VERSION ""

NS_ :

BS_:

BU_: SOBDM_BCCM GWM GENERIC BECM TSTR

BO_ 2026 TesterPhysicalResSOBDM: 8 SOBDM_BCCM
 SG_ TesterPhysicalResSOBDM : 7|64@0+ (1,0) [0|1.84467E+019] "unitless"  TSTR

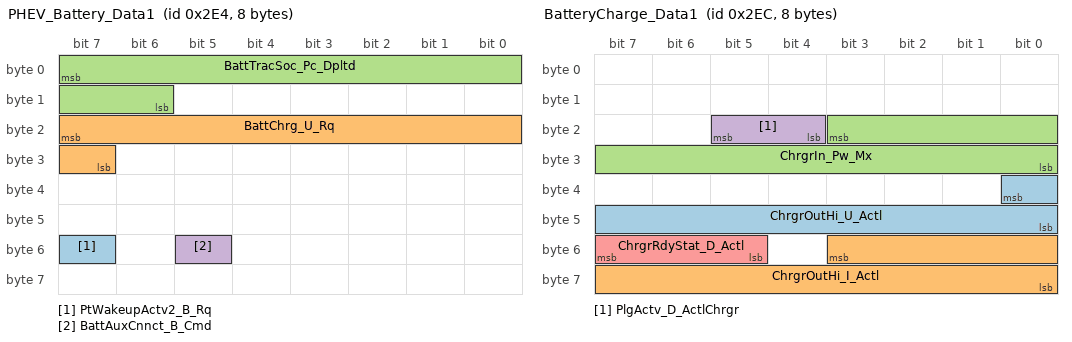
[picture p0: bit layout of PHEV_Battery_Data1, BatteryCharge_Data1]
BO_ 740 PHEV_Battery_Data1: 8 BECM
 SG_ PtWakeupActv2_B_Rq : 55|1@0+ (1,0) [0|1] "SED"  GWM
 SG_ BattChrg_U_Rq : 23|9@0+ (1,0) [0|511] "volt"  GWM,SOBDM_BCCM
 SG_ BattTracSoc_Pc_Dpltd : 7|10@0+ (0.1,0) [0|102.3] "percent"  GWM
 SG_ BattAuxCnnct_B_Cmd : 53|1@0+ (1,0) [0|1] "SED"  GWM,SOBDM_BCCM

BO_ 748 BatteryCharge_Data1: 8 SOBDM_BCCM
 SG_ ChrgrOutHi_U_Actl : 32|9@0+ (1,0) [0|510] "volt"  BECM,GWM
 SG_ ChrgrOutHi_I_Actl : 51|12@0+ (0.1,0) [0|409.4] "ampere"  BECM,GWM
 SG_ ChrgrIn_Pw_Mx : 19|12@0+ (50,0) [0|204700] "watts"  BECM,GWM
 SG_ PlgActv_D_ActlChrgr : 21|2@0+ (1,0) [0|3] "SED"  BECM,GWM
 SG_ ChrgrRdyStat_D_Actl : 55|3@0+ (1,0) [0|7] "SED"  BECM,GWM

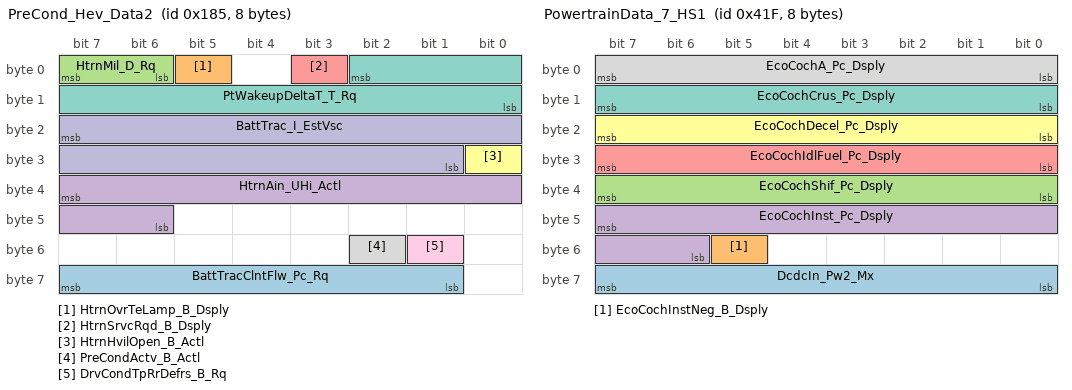
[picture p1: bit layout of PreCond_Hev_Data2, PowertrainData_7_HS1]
BO_ 389 PreCond_Hev_Data2: 8 GWM
 SG_ BattTracClntFlw_Pc_Rq : 63|7@0+ (1,0) [0|127] "percent"  BECM
 SG_ HtrnOvrTeLamp_B_Dsply : 5|1@0+ (1,0) [0|1] "SED" Vector__XXX
 SG_ HtrnMil_D_Rq : 7|2@0+ (1,0) [0|3] "SED" Vector__XXX
 SG_ HtrnAin_UHi_Actl : 39|10@0+ (0.5,0) [0|510.5] "volt"  BECM
 SG_ HtrnSrvcRqd_B_Dsply : 3|1@0+ (1,0) [0|1] "SED" Vector__XXX
 SG_ HtrnHvilOpen_B_Actl : 24|1@0+ (1,0) [0|1] "SED"  BECM
 SG_ PtWakeupDeltaT_T_Rq : 2|11@0+ (1,0) [0|2045] "minute" Vector__XXX
 SG_ PreCondActv_B_Actl : 50|1@0+ (1,0) [0|1] "SED" Vector__XXX
 SG_ DrvCondTpRrDefrs_B_Rq : 49|1@0+ (1,0) [0|1] "SED" Vector__XXX
 SG_ BattTrac_I_EstVsc : 23|15@0+ (0.05,-750) [-750|888.25] "Amps"  BECM

BO_ 1055 PowertrainData_7_HS1: 8 GWM
 SG_ DcdcIn_Pw2_Mx : 63|8@0+ (20,500) [500|5600] "watts"  BECM
 SG_ EcoCochInstNeg_B_Dsply : 53|1@0+ (1,0) [0|1] "SED" Vector__XXX
 SG_ EcoCochShif_Pc_Dsply : 39|8@0+ (0.392157,0) [0|100.000035] "percent" Vector__XXX
 SG_ EcoCochInst_Pc_Dsply : 47|10@0+ (0.1,0) [0|102.3] "percent" Vector__XXX
 SG_ EcoCochIdlFuel_Pc_Dsply : 31|8@0+ (0.392157,0) [0|100.000035] "percent" Vector__XXX
 SG_ EcoCochDecel_Pc_Dsply : 23|8@0+ (0.392157,0) [0|100.000035] "percent" Vector__XXX
 SG_ EcoCochCrus_Pc_Dsply : 15|8@0+ (0.392157,0) [0|100.000035] "percent" Vector__XXX
 SG_ EcoCochA_Pc_Dsply : 7|8@0+ (0.392157,0) [0|100.000035] "percent" Vector__XXX

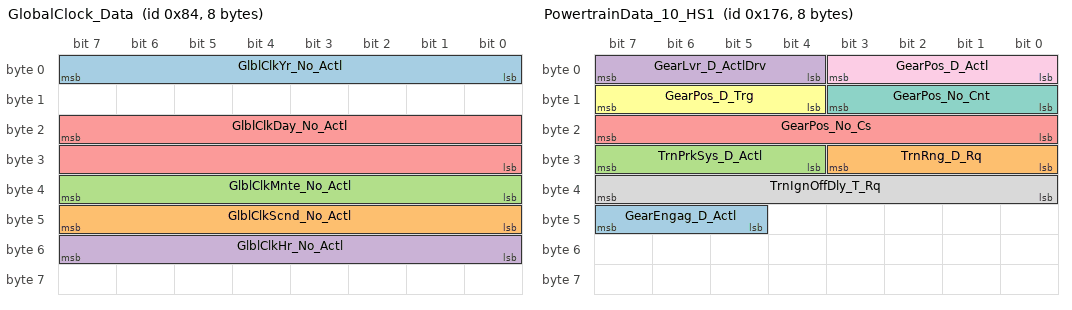
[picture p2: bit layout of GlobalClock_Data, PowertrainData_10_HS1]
BO_ 132 GlobalClock_Data: 8 GWM
 SG_ GlblClkYr_No_Actl : 7|8@0+ (1,2000) [2000|2255] "year"  BECM
 SG_ GlblClkScnd_No_Actl : 47|8@0+ (1,0) [0|255] "second" Vector__XXX
 SG_ GlblClkMnte_No_Actl : 39|8@0+ (1,0) [0|255] "minute" Vector__XXX
 SG_ GlblClkHr_No_Actl : 55|8@0+ (1,0) [0|255] "hour" Vector__XXX
 SG_ GlblClkDay_No_Actl : 23|16@0+ (1,0) [0|65535] "julian day"  BECM

BO_ 374 PowertrainData_10_HS1: 8 GWM
 SG_ GearEngag_D_Actl : 47|3@0+ (1,0) [0|7] "SED" Vector__XXX
 SG_ TrnRng_D_Rq : 27|4@0+ (1,0) [0|15] "SED"  BECM,SOBDM_BCCM
 SG_ TrnPrkSys_D_Actl : 31|4@0+ (1,0) [0|15] "SED" Vector__XXX
 SG_ GearLvr_D_ActlDrv : 7|4@0+ (1,0) [0|15] "SED" Vector__XXX
 SG_ GearPos_No_Cs : 23|8@0+ (1,0) [0|255] "unitless" Vector__XXX
 SG_ GearPos_D_Trg : 15|4@0+ (1,0) [0|15] "SED" Vector__XXX
 SG_ GearPos_No_Cnt : 11|4@0+ (1,0) [0|15] "unitless" Vector__XXX
 SG_ TrnIgnOffDly_T_Rq : 39|8@0+ (4,0) [0|1020] "ms" Vector__XXX
 SG_ GearPos_D_Actl : 3|4@0+ (1,0) [0|15] "SED" Vector__XXX

BO_ 817 Locking_Systems_2: 8 GWM
 SG_ ChildLckMde_B_Stat : 56|1@0+ (1,0) [0|1] "SED" Vector__XXX
 SG_ VehLckInd_D_Rq : 58|2@0+ (1,0) [0|3] "SED" Vector__XXX
 SG_ DrTgateOpen_B_Rq : 59|1@0+ (1,0) [0|1] "SED" Vector__XXX
 SG_ DrTgateExtSwMde_B_Stat : 32|1@0+ (1,0) [0|1] "SED" Vector__XXX
 SG_ Remote_Device_Feedback : 50|3@0+ (1,0) [0|7] "SED" Vector__XXX
 SG_ Veh_Lock_Requestor : 55|5@0+ (1,0) [0|31] "SED" Vector__XXX
 SG_ R_Pwr_Sliding_Dr_Rqst : 36|1@0+ (1,0) [0|1] "SED" Vector__XXX
 SG_ Power_Liftgate_Rqst : 0|1@0+ (1,0) [0|1] "SED" Vector__XXX
 SG_ Veh_Lock_EvNum : 47|8@0+ (1,0) [0|255] "unitless" Vector__XXX
 SG_ Power_Decklid_Rqst : 1|1@0+ (1,0) [0|1] "SED" Vector__XXX
 SG_ L_Pwr_Sliding_Dr_Rqst : 3|1@0+ (1,0) [0|1] "SED" Vector__XXX
 SG_ Keyfob_Pad_Msg_Count : 15|8@0+ (1,0) [0|255] "Counts" Vector__XXX
 SG_ Veh_Lock_Sub_Id : 63|4@0+ (1,0) [0|15] "SED" Vector__XXX
 SG_ Veh_Lock_Status : 34|2@0+ (1,0) [0|3] "SED"  SOBDM_BCCM
 SG_ ChildLck_D_Dsply : 7|2@0+ (1,0) [0|3] "SED" Vector__XXX
 SG_ WindowLockout_B_Stat : 35|1@0+ (1,0) [0|1] "SED" Vector__XXX
 SG_ RollCodeUnlock : 23|16@0+ (1,0) [0|65535] "Unitless" Vector__XXX
 SG_ Lockmsgtxt_D_Rq : 39|3@0+ (1,0) [0|7] "SED" Vector__XXX
 SG_ FobComm_D_Stat : 5|2@0+ (1,0) [0|3] "SED" Vector__XXX
 SG_ LockInhibit : 2|1@0+ (1,0) [0|1] "SED" Vector__XXX

BO_ 2018 TesterPhysicalReqSOBDM: 8 TSTR
 SG_ TesterPhysicalReqSOBDM : 7|64@0+ (1,0) [0|1.84467E+019] "unitless"  SOBDM_BCCM

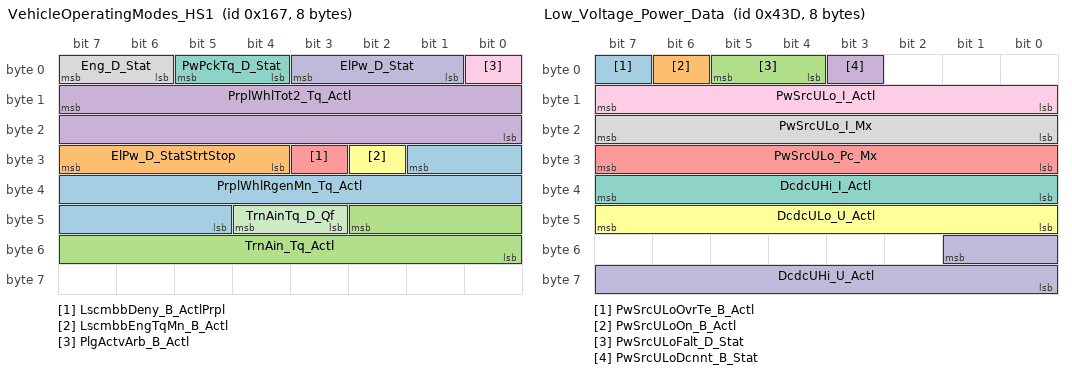
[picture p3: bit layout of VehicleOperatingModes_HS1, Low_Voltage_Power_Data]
BO_ 359 VehicleOperatingModes_HS1: 8 GWM
 SG_ PrplWhlRgenMn_Tq_Actl : 25|13@0+ (4,-16380) [-16380|16380] "Nm" Vector__XXX
 SG_ ElPw_D_StatStrtStop : 31|4@0+ (1,0) [0|15] "SED" Vector__XXX
 SG_ TrnAin_Tq_Actl : 42|11@0+ (1,-500) [-500|1547] "Nm" Vector__XXX
 SG_ PrplWhlTot2_Tq_Actl : 15|16@0+ (4,-131072) [-131072|131060] "Nm" Vector__XXX
 SG_ LscmbbDeny_B_ActlPrpl : 27|1@0+ (1,0) [0|1] "SED" Vector__XXX
 SG_ LscmbbEngTqMn_B_Actl : 26|1@0+ (1,0) [0|1] "SED" Vector__XXX
 SG_ PwPckTq_D_Stat : 5|2@0+ (1,0) [0|3] "SED"  SOBDM_BCCM,BECM
 SG_ Eng_D_Stat : 7|2@0+ (1,0) [0|3] "SED" Vector__XXX
 SG_ PlgActvArb_B_Actl : 0|1@0+ (1,0) [0|1] "SED" Vector__XXX
 SG_ ElPw_D_Stat : 3|3@0+ (1,0) [0|7] "SED" Vector__XXX
 SG_ TrnAinTq_D_Qf : 44|2@0+ (1,0) [0|3] "SED" Vector__XXX

BO_ 1085 Low_Voltage_Power_Data: 8 GWM
 SG_ PwSrcULoOvrTe_B_Actl : 7|1@0+ (1,0) [0|1] "SED" Vector__XXX
 SG_ PwSrcULoOn_B_Actl : 6|1@0+ (1,0) [0|1] "SED"  SOBDM_BCCM
 SG_ PwSrcULoFalt_D_Stat : 5|2@0+ (1,0) [0|3] "SED" Vector__XXX
 SG_ PwSrcULoDcnnt_B_Stat : 3|1@0+ (1,0) [0|1] "SED" Vector__XXX
 SG_ PwSrcULo_Pc_Mx : 31|8@0+ (0.4,0) [0|101.6] "%" Vector__XXX
 SG_ DcdcULo_U_Actl : 47|8@0+ (0.1,0) [0|25.4] "Volts" Vector__XXX
 SG_ DcdcUHi_I_Actl : 39|8@0+ (0.1,0) [0|25.4] "Amps"  BECM
 SG_ PwSrcULo_I_Mx : 23|8@0+ (1,0) [0|254] "ampere" Vector__XXX
 SG_ PwSrcULo_I_Actl : 15|8@0+ (1,0) [0|254] "ampere" Vector__XXX
 SG_ DcdcUHi_U_Actl : 49|10@0+ (0.5,0) [0|510.5] "V"  BECM

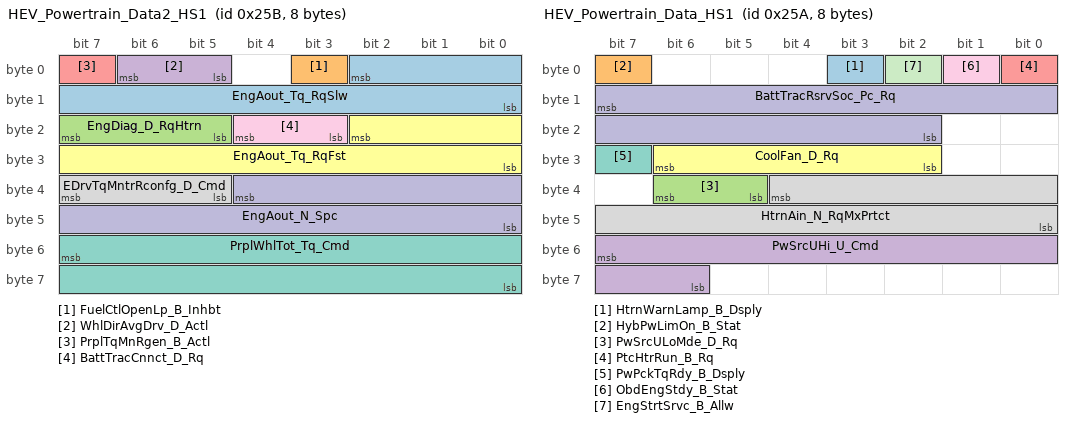
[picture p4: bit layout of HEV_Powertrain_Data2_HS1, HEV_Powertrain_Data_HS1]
BO_ 603 HEV_Powertrain_Data2_HS1: 8 GWM
 SG_ EngAout_Tq_RqSlw : 2|11@0+ (1,-500) [-500|1547] "Nm" Vector__XXX
 SG_ FuelCtlOpenLp_B_Inhbt : 3|1@0+ (1,0) [0|1] "SED" Vector__XXX
 SG_ EngDiag_D_RqHtrn : 23|3@0+ (1,0) [0|7] "SED" Vector__XXX
 SG_ WhlDirAvgDrv_D_Actl : 6|2@0+ (1,0) [0|3] "SED" Vector__XXX
 SG_ PrplTqMnRgen_B_Actl : 7|1@0+ (1,0) [0|1] "SED" Vector__XXX
 SG_ EngAout_Tq_RqFst : 18|11@0+ (1,-500) [-500|1547] "Nm" Vector__XXX
 SG_ PrplWhlTot_Tq_Cmd : 55|16@0+ (4,-131072) [-131072|131068] "Nm" Vector__XXX
 SG_ EDrvTqMntrRconfg_D_Cmd : 39|3@0+ (1,0) [0|7] "SED" Vector__XXX
 SG_ BattTracCnnct_D_Rq : 20|2@0+ (1,0) [0|3] "SED"  SOBDM_BCCM,BECM
 SG_ EngAout_N_Spc : 36|13@0+ (2,0) [0|16382] "rpm" Vector__XXX

BO_ 602 HEV_Powertrain_Data_HS1: 8 GWM
 SG_ HtrnWarnLamp_B_Dsply : 3|1@0+ (1,0) [0|1] "SED" Vector__XXX
 SG_ HybPwLimOn_B_Stat : 7|1@0+ (1,0) [0|1] "SED"  BECM
 SG_ PwSrcULoMde_D_Rq : 38|2@0+ (1,0) [0|3] "SED"  BECM
 SG_ PwSrcUHi_U_Cmd : 55|10@0+ (0.5,0) [0|511.5] "volt"  BECM
 SG_ PtcHtrRun_B_Rq : 0|1@0+ (1,0) [0|1] "SED" Vector__XXX
 SG_ CoolFan_D_Rq : 30|5@0+ (1,0) [0|31] "unitless" Vector__XXX
 SG_ PwPckTqRdy_B_Dsply : 31|1@0+ (1,0) [0|1] "SED" Vector__XXX
 SG_ HtrnAin_N_RqMxPrtct : 36|13@0+ (2,0) [0|16382] "RPM" Vector__XXX
 SG_ ObdEngStdy_B_Stat : 1|1@0+ (1,0) [0|1] "SED" Vector__XXX
 SG_ BattTracRsrvSoc_Pc_Rq : 15|14@0+ (0.01,0) [0|163.81] "percent"  BECM
 SG_ EngStrtSrvc_B_Allw : 2|1@0+ (1,0) [0|1] "SED" Vector__XXX

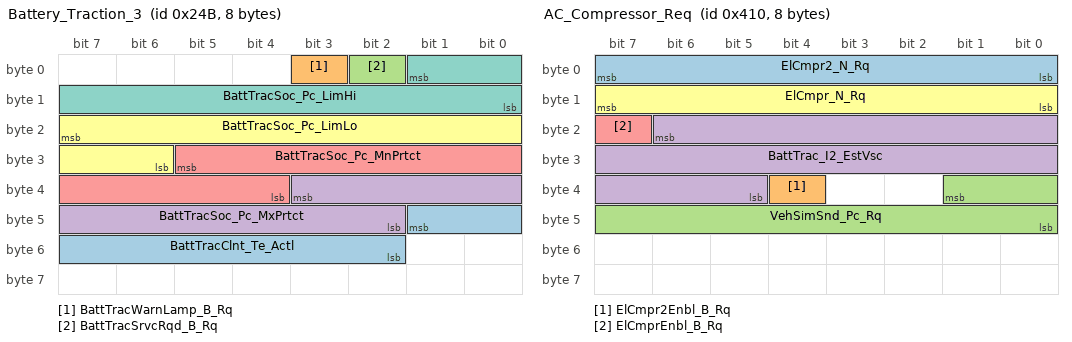
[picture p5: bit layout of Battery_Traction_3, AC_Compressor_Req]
BO_ 587 Battery_Traction_3: 8 BECM
 SG_ BattTracClnt_Te_Actl : 41|8@0+ (0.5,-60) [-60|66.5] "degC"  GWM
 SG_ BattTracWarnLamp_B_Rq : 3|1@0+ (1,0) [0|1] "SED"  GWM
 SG_ BattTracSrvcRqd_B_Rq : 2|1@0+ (1,0) [0|1] "SED"  GWM
 SG_ BattTracSoc_Pc_MxPrtct : 35|10@0+ (0.1,0) [0|100] "%"  GWM
 SG_ BattTracSoc_Pc_MnPrtct : 29|10@0+ (0.1,0) [0|100] "%"  GWM
 SG_ BattTracSoc_Pc_LimLo : 23|10@0+ (0.1,0) [0|100] "%"  GWM
 SG_ BattTracSoc_Pc_LimHi : 1|10@0+ (0.1,0) [0|100] "%"  GWM

BO_ 1040 AC_Compressor_Req: 8 GWM
 SG_ ElCmpr2_N_Rq : 7|8@0+ (50,0) [0|12750] "RPM" Vector__XXX
 SG_ ElCmpr2Enbl_B_Rq : 36|1@0+ (1,0) [0|1] "SED" Vector__XXX
 SG_ VehSimSnd_Pc_Rq : 33|10@0+ (0.2,-102.2) [-102.2|102.4] "percent" Vector__XXX
 SG_ BattTrac_I2_EstVsc : 22|18@0+ (0.05,-6553.52) [-6553.52|6553.53] "ampere"  BECM
 SG_ ElCmprEnbl_B_Rq : 23|1@0+ (1,0) [0|1] "SED" Vector__XXX
 SG_ ElCmpr_N_Rq : 15|8@0+ (50,0) [0|12750] "RPM" Vector__XXX

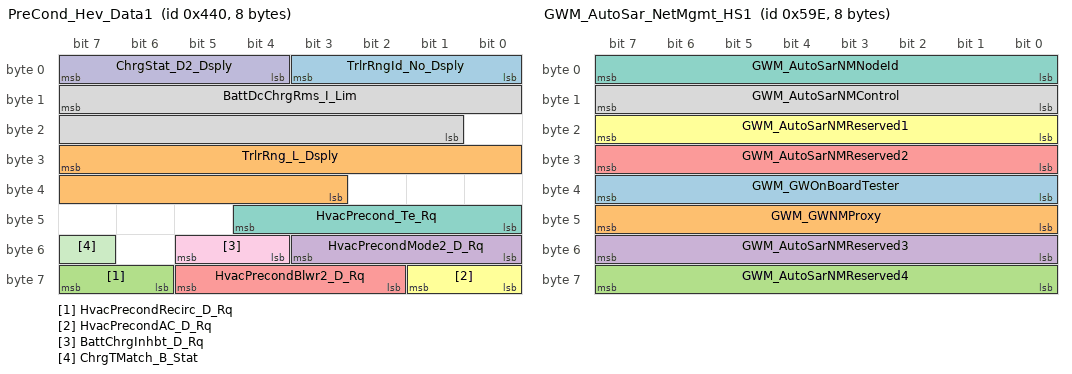
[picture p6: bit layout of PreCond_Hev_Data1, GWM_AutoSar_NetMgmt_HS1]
BO_ 1088 PreCond_Hev_Data1: 8 GWM
 SG_ TrlrRngId_No_Dsply : 3|4@0+ (1,0) [0|15] "unitless" Vector__XXX
 SG_ TrlrRng_L_Dsply : 31|13@0+ (0.1,0) [0|818.9] "kilometer" Vector__XXX
 SG_ HvacPrecondRecirc_D_Rq : 63|2@0+ (1,0) [0|3] "SED" Vector__XXX
 SG_ HvacPrecondMode2_D_Rq : 51|4@0+ (1,0) [0|15] "SED" Vector__XXX
 SG_ HvacPrecondBlwr2_D_Rq : 61|4@0+ (1,0) [0|15] "SED" Vector__XXX
 SG_ HvacPrecondAC_D_Rq : 57|2@0+ (1,0) [0|3] "SED" Vector__XXX
 SG_ HvacPrecond_Te_Rq : 44|5@0+ (0.5,14.5) [14.5|30] "deg C" Vector__XXX
 SG_ BattDcChrgRms_I_Lim : 15|15@0+ (0.05,0) [0|1638.25] "ampere"  BECM
 SG_ BattChrgInhbt_D_Rq : 53|2@0+ (1,0) [0|3] "SED"  BECM,SOBDM_BCCM
 SG_ ChrgStat_D2_Dsply : 7|4@0+ (1,0) [0|15] "SED" Vector__XXX
 SG_ ChrgTMatch_B_Stat : 55|1@0+ (1,0) [0|1] "SED" Vector__XXX

BO_ 1072 Cluster_Info1_HS1: 8 GWM
 SG_ ePRNDL_MODE_UB : 63|1@0+ (1,0) [0|1] "SED" Vector__XXX
 SG_ NtrlTowMdeEnbl_B_RqDrv : 6|1@0+ (1,0) [0|1] "SED" Vector__XXX
 SG_ NtrlTowMdeEnbl_B_RqDrv_UB : 48|1@0+ (1,0) [0|1] "SED" Vector__XXX
 SG_ Remote_Start_QuietMode_UB : 50|1@0+ (1,0) [0|1] "SED" Vector__XXX
 SG_ Remote_Start_QuietMode : 51|1@0+ (1,0) [0|1] "SED" Vector__XXX
 SG_ ParkDetect_Stat_UB : 52|1@0+ (1,0) [0|1] "SED" Vector__XXX
 SG_ ParkDetect_Stat : 53|1@0+ (1,0) [0|1] "SED" Vector__XXX
 SG_ TrlrLampCnnct_B_Actl_UB : 42|1@0+ (1,0) [0|1] "SED" Vector__XXX
 SG_ StopLamp_B_RqTrlrBrk_UB : 46|1@0+ (1,0) [0|1] "SED" Vector__XXX
 SG_ StopLamp_B_RqTrlrBrk : 47|1@0+ (1,0) [0|1] "SED" Vector__XXX
 SG_ OdometerMasterValue_UB : 1|1@0+ (1,0) [0|1] "SED"  SOBDM_BCCM,BECM
 SG_ OdometerMasterValue : 15|24@0+ (1,0) [0|16777214] "km"  SOBDM_BCCM,BECM
 SG_ FrostWarn_D_Stat : 5|2@0+ (1,0) [0|3] "SED" Vector__XXX
 SG_ ReducedGuard_D_Rq_UB : 49|1@0+ (1,0) [0|1] "SED" Vector__XXX
 SG_ ReducedGuard_D_Rq : 41|2@0+ (1,0) [0|3] "SED" Vector__XXX
 SG_ ePRNDL_MODE : 0|1@0+ (1,0) [0|1] "SED" Vector__XXX
 SG_ EngOilLife_B_RqReset : 43|1@0+ (1,0) [0|1] "SED" Vector__XXX
 SG_ Outside_Air_Temp_Stat_UB : 2|1@0+ (1,0) [0|1] "SED" Vector__XXX
 SG_ Outside_Air_Temp_Stat : 39|8@0+ (0.5,-40) [-40|86.5] "Degrees C" Vector__XXX
 SG_ KeyTypeChngMykey_D_Rq_UB : 60|1@0+ (1,0) [0|1] "SED" Vector__XXX
 SG_ KeyTypeChngMykey_D_Rq : 62|2@0+ (1,0) [0|3] "SED" Vector__XXX
 SG_ TrlrLampCnnct_B_Actl : 3|1@0+ (1,0) [0|1] "SED" Vector__XXX

BO_ 1438 GWM_AutoSar_NetMgmt_HS1: 8 GWM
 SG_ GWM_GWOnBoardTester : 39|8@0+ (1,0) [0|255] "unitless"  SOBDM_BCCM,BECM
 SG_ GWM_GWNMProxy : 47|8@0+ (1,0) [0|255] "unitless"  SOBDM_BCCM,BECM
 SG_ GWM_AutoSarNMReserved4 : 63|8@0+ (1,0) [0|255] "unitless"  SOBDM_BCCM,BECM
 SG_ GWM_AutoSarNMReserved3 : 55|8@0+ (1,0) [0|255] "unitless"  SOBDM_BCCM,BECM
 SG_ GWM_AutoSarNMReserved2 : 31|8@0+ (1,0) [0|255] "unitless"  SOBDM_BCCM,BECM
 SG_ GWM_AutoSarNMReserved1 : 23|8@0+ (1,0) [0|255] "unitless"  SOBDM_BCCM,BECM
 SG_ GWM_AutoSarNMNodeId : 7|8@0+ (1,0) [0|255] "unitless"  SOBDM_BCCM,BECM
 SG_ GWM_AutoSarNMControl : 15|8@0+ (1,0) [0|255] "unitless"  SOBDM_BCCM,BECM

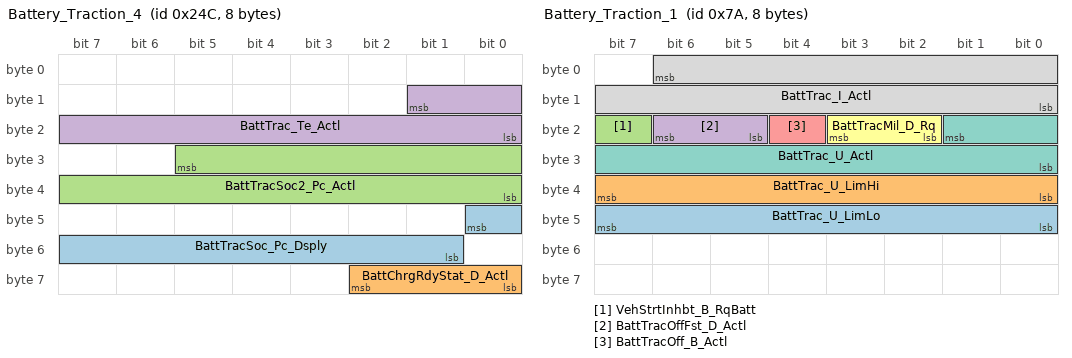
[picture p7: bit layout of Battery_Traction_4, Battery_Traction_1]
BO_ 588 Battery_Traction_4: 8 BECM
 SG_ BattTracSoc_Pc_Dsply : 40|8@0+ (0.5,0) [0|126.5] "Percent"  GWM,SOBDM_BCCM
 SG_ BattChrgRdyStat_D_Actl : 58|3@0+ (1,0) [0|7] "SED"  GWM,SOBDM_BCCM
 SG_ BattTracSoc2_Pc_Actl : 29|14@0+ (0.01,0) [0|163.81] "%"  GWM
 SG_ BattTrac_Te_Actl : 9|10@0+ (0.5,-50) [-50|460.5] "degC"  GWM

BO_ 122 Battery_Traction_1: 8 BECM
 SG_ BattTrac_U_LimLo : 47|8@0+ (2,0) [0|510] "volt"  GWM
 SG_ BattTrac_U_LimHi : 39|8@0+ (2,0) [0|510] "volt"  GWM
 SG_ VehStrtInhbt_B_RqBatt : 23|1@0+ (1,0) [0|1] "SED"  GWM
 SG_ BattTracOffFst_D_Actl : 22|2@0+ (1,0) [0|3] "SED"  SOBDM_BCCM,GWM
 SG_ BattTracOff_B_Actl : 20|1@0+ (1,0) [0|1] "SED"  GWM,SOBDM_BCCM
 SG_ BattTracMil_D_Rq : 19|2@0+ (1,0) [0|3] "SED"  GWM
 SG_ BattTrac_U_Actl : 17|10@0+ (0.5,0) [0|510.5] "Volts"  GWM,SOBDM_BCCM
 SG_ BattTrac_I_Actl : 6|15@0+ (0.05,-750) [-750|888.25] "Amps"  SOBDM_BCCM,GWM

BO_ 1814 TesterPhysicalReqGWM_H1: 8 TSTR
 SG_ TesterPhysicalReqGWM_H1 : 7|64@0+ (1,0) [0|1.84467E+019] "unitless"  GWM

BO_ 1822 TesterPhysicalResGWM_HS1: 8 GWM
 SG_ TesterPhysicalResGWM_H1 : 7|64@0+ (1,0) [0|1.84467E+019] "unitless"  TSTR

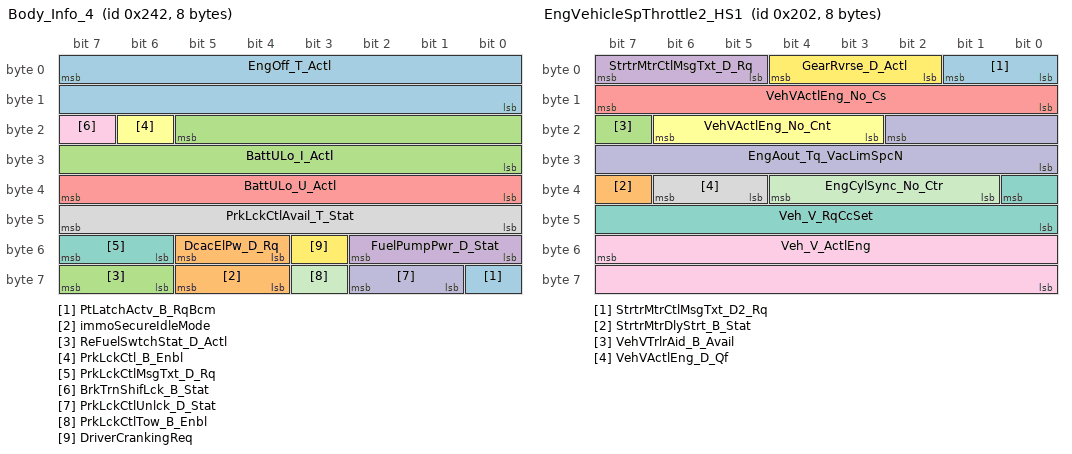
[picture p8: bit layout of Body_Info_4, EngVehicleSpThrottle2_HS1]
BO_ 578 Body_Info_4: 8 GWM
 SG_ PtLatchActv_B_RqBcm : 56|1@0+ (1,0) [0|1] "SED" Vector__XXX
 SG_ immoSecureIdleMode : 61|2@0+ (1,0) [0|3] "SED" Vector__XXX
 SG_ ReFuelSwtchStat_D_Actl : 63|2@0+ (1,0) [0|3] "SED" Vector__XXX
 SG_ FuelPumpPwr_D_Stat : 50|3@0+ (1,0) [0|7] "SED" Vector__XXX
 SG_ BattULo_U_Actl : 39|8@0+ (0.0625,0) [0|15.875] "volt"  SOBDM_BCCM,BECM
 SG_ PrkLckCtl_B_Enbl : 22|1@0+ (1,0) [0|1] "SED" Vector__XXX
 SG_ PrkLckCtlMsgTxt_D_Rq : 55|2@0+ (1,0) [0|3] "SED" Vector__XXX
 SG_ PrkLckCtlAvail_T_Stat : 47|8@0+ (1,0) [0|255] "second" Vector__XXX
 SG_ BrkTrnShifLck_B_Stat : 23|1@0+ (1,0) [0|1] "SED" Vector__XXX
 SG_ PrkLckCtlUnlck_D_Stat : 58|2@0+ (1,0) [0|3] "SED" Vector__XXX
 SG_ PrkLckCtlTow_B_Enbl : 59|1@0+ (1,0) [0|1] "SED" Vector__XXX
 SG_ DriverCrankingReq : 51|1@0+ (1,0) [0|1] "SED" Vector__XXX
 SG_ EngOff_T_Actl : 7|16@0+ (1,0) [0|65534] "second^0.5" Vector__XXX
 SG_ DcacElPw_D_Rq : 53|2@0+ (1,0) [0|3] "SED" Vector__XXX
 SG_ BattULo_I_Actl : 21|14@0+ (0.0625,-512) [-512|511.875] "ampere" Vector__XXX

BO_ 514 EngVehicleSpThrottle2_HS1: 8 GWM
 SG_ StrtrMtrCtlMsgTxt_D2_Rq : 1|2@0+ (1,0) [0|3] "SED" Vector__XXX
 SG_ StrtrMtrDlyStrt_B_Stat : 39|1@0+ (1,0) [0|1] "SED" Vector__XXX
 SG_ VehVTrlrAid_B_Avail : 23|1@0+ (1,0) [0|1] "SED" Vector__XXX
 SG_ StrtrMtrCtlMsgTxt_D_Rq : 7|3@0+ (1,0) [0|7] "SED" Vector__XXX
 SG_ VehVActlEng_No_Cs : 15|8@0+ (1,0) [0|255] "Unitless" Vector__XXX
 SG_ VehVActlEng_No_Cnt : 22|4@0+ (1,0) [0|15] "Unitless" Vector__XXX
 SG_ Veh_V_RqCcSet : 32|9@0+ (0.5,0) [0|255.5] "kph" Vector__XXX
 SG_ VehVActlEng_D_Qf : 38|2@0+ (1,0) [0|3] "SED"  BECM
 SG_ Veh_V_ActlEng : 55|16@0+ (0.01,0) [0|655.35] "kph"  BECM
 SG_ EngAout_Tq_VacLimSpcN : 18|11@0+ (1,-500) [-500|1547] "Nm" Vector__XXX
 SG_ EngCylSync_No_Ctr : 36|4@0+ (1,0) [0|15] "unitless" Vector__XXX
 SG_ GearRvrse_D_Actl : 4|3@0+ (1,0) [0|7] "SED" Vector__XXX

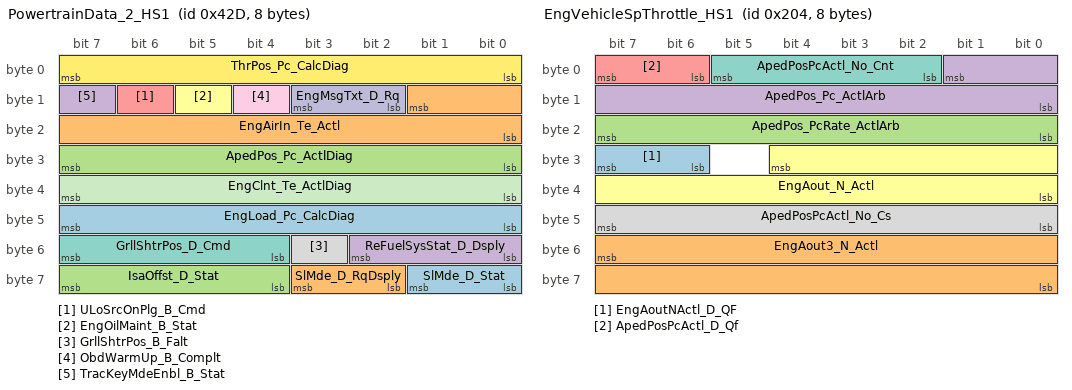
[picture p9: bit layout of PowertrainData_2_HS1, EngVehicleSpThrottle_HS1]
BO_ 1069 PowertrainData_2_HS1: 8 GWM
 SG_ SlMde_D_Stat : 57|2@0+ (1,0) [0|3] "SED" Vector__XXX
 SG_ SlMde_D_RqDsply : 59|2@0+ (1,0) [0|3] "SED" Vector__XXX
 SG_ IsaOffst_D_Stat : 63|4@0+ (1,0) [0|15] "SED" Vector__XXX
 SG_ ReFuelSysStat_D_Dsply : 50|3@0+ (1,0) [0|7] "SED" Vector__XXX
 SG_ ULoSrcOnPlg_B_Cmd : 14|1@0+ (1,0) [0|1] "SED"  BECM
 SG_ EngOilMaint_B_Stat : 13|1@0+ (1,0) [0|1] "SED" Vector__XXX
 SG_ GrllShtrPos_D_Cmd : 55|4@0+ (1,0) [0|15] "SED" Vector__XXX
 SG_ GrllShtrPos_B_Falt : 51|1@0+ (1,0) [0|1] "SED" Vector__XXX
 SG_ ObdWarmUp_B_Complt : 12|1@0+ (1,0) [0|1] "SED"  SOBDM_BCCM,BECM
 SG_ EngMsgTxt_D_Rq : 11|2@0+ (1,0) [0|3] "SED" Vector__XXX
 SG_ EngClnt_Te_ActlDiag : 39|8@0+ (1,-40) [-40|215] "degC"  BECM
 SG_ ThrPos_Pc_CalcDiag : 7|8@0+ (0.392157,0) [0|100.000035] "%" Vector__XXX
 SG_ EngLoad_Pc_CalcDiag : 47|8@0+ (0.392157,0) [0|100.000035] "%"  BECM
 SG_ EngAirIn_Te_Actl : 9|10@0+ (0.25,-128) [-128|127.25] "degC" Vector__XXX
 SG_ ApedPos_Pc_ActlDiag : 31|8@0+ (0.392157,0) [0|100.000035] "%"  BECM
 SG_ TracKeyMdeEnbl_B_Stat : 15|1@0+ (1,0) [0|1] "SED" Vector__XXX

BO_ 2015 TesterFunctionalReq_H1: 8 TSTR
 SG_ TesterFunctionalReq : 7|64@0+ (1,0) [0|1.84467E+019] "unitless"  SOBDM_BCCM,GWM,BECM

BO_ 516 EngVehicleSpThrottle_HS1: 8 GWM
 SG_ EngAoutNActl_D_QF : 31|2@0+ (1,0) [0|3] "SED" Vector__XXX
 SG_ EngAout3_N_Actl : 55|16@0+ (0.25,0) [0|16383.5] "RPM" Vector__XXX
 SG_ ApedPos_PcRate_ActlArb : 23|8@0+ (0.04,-5) [-5|5.12] "%/ms" Vector__XXX
 SG_ ApedPos_Pc_ActlArb : 1|10@0+ (0.1,0) [0|102.3] "%" Vector__XXX
 SG_ ApedPosPcActl_D_Qf : 7|2@0+ (1,0) [0|3] "SED" Vector__XXX
 SG_ EngAout_N_Actl : 28|13@0+ (2,0) [0|16382] "rpm"  BECM
 SG_ ApedPosPcActl_No_Cnt : 5|4@0+ (1,0) [0|15] "Unitless" Vector__XXX
 SG_ ApedPosPcActl_No_Cs : 47|8@0+ (1,0) [0|255] "Unitless" Vector__XXX

BO_ 76 RCMStatusMessage2_HS1: 8 GWM
 SG_ RstrnPsngrOn_D_Stat : 39|4@0+ (1,0) [0|15] "SED" Vector__XXX
 SG_ FirstRowBuckle_No_Cs : 47|8@0+ (1,0) [0|255] "unitless" Vector__XXX
 SG_ RCMStatusMsg2_No_Cnt : 35|4@0+ (1,0) [0|15] "Unitless" Vector__XXX
 SG_ PsngrFmidDetct_D_Actl : 26|2@0+ (1,0) [0|3] "SED" Vector__XXX
 SG_ FirstRowBuckleMid : 28|2@0+ (1,0) [0|3] "SED" Vector__XXX
 SG_ ThirdRowBucklePsngr : 17|2@0+ (1,0) [0|3] "SED" Vector__XXX
 SG_ ThirdRowBuckleMid : 19|2@0+ (1,0) [0|3] "SED" Vector__XXX
 SG_ ThirdRowBuckleDriver : 21|2@0+ (1,0) [0|3] "SED" Vector__XXX
 SG_ SecondRowBucklePsngr : 23|2@0+ (1,0) [0|3] "SED" Vector__XXX
 SG_ SecondRowBuckleMid : 9|2@0+ (1,0) [0|3] "SED" Vector__XXX
 SG_ SecondRowBuckleDriver : 11|2@0+ (1,0) [0|3] "SED" Vector__XXX
 SG_ FirstRowBuckleDriver : 15|2@0+ (1,0) [0|3] "SED" Vector__XXX
 SG_ RILReq : 7|2@0+ (1,0) [0|3] "SED" Vector__XXX
 SG_ FirstRowBucklePsngr : 13|2@0+ (1,0) [0|3] "SED" Vector__XXX
 SG_ RstrnImpactEvntStatus : 3|3@0+ (1,0) [0|7] "SED"  SOBDM_BCCM,BECM
 SG_ PsngrFrntDetct_D_Actl : 5|2@0+ (1,0) [0|3] "SED" Vector__XXX
 SG_ EDRTriggerEvntSync : 29|1@0+ (1,0) [0|1] "SED" Vector__XXX
 SG_ PassRstrnInd_Req : 31|2@0+ (1,0) [0|3] "SED" Vector__XXX

BO_ 2028 TesterPhysicalResBECM: 8 BECM
 SG_ TesterPhysicalResBECM : 7|64@0+ (1,0) [0|1.84467E+019] "unitless"  TSTR

BO_ 2020 TesterPhysicalReqBECM: 8 TSTR
 SG_ TesterPhysicalReqBECM : 7|64@0+ (1,0) [0|1.84467E+019] "unitless"  BECM

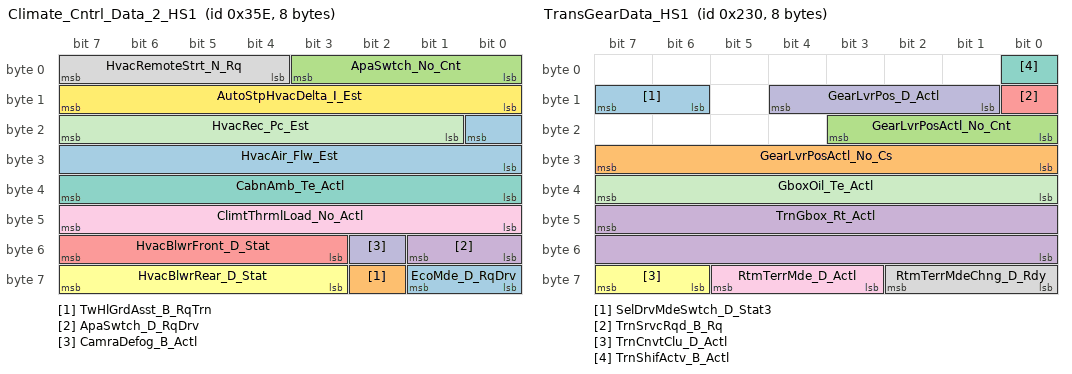
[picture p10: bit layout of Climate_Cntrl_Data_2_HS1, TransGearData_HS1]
BO_ 862 Climate_Cntrl_Data_2_HS1: 8 GWM
 SG_ EcoMde_D_RqDrv : 57|2@0+ (1,0) [0|3] "SED" Vector__XXX
 SG_ TwHlGrdAsst_B_RqTrn : 58|1@0+ (1,0) [0|1] "SED" Vector__XXX
 SG_ ApaSwtch_No_Cnt : 3|4@0+ (1,0) [0|15] "Unitless" Vector__XXX
 SG_ ApaSwtch_D_RqDrv : 49|2@0+ (1,0) [0|3] "SED" Vector__XXX
 SG_ HvacBlwrFront_D_Stat : 55|5@0+ (1,0) [0|31] "SED" Vector__XXX
 SG_ HvacBlwrRear_D_Stat : 63|5@0+ (1,0) [0|31] "SED" Vector__XXX
 SG_ CabnAmb_Te_Actl : 39|8@0+ (0.5,-57) [-57|70] "degreesC"  SOBDM_BCCM
 SG_ HvacRemoteStrt_N_Rq : 7|4@0+ (100,450) [450|1950] "RPM" Vector__XXX
 SG_ ClimtThrmlLoad_No_Actl : 47|8@0+ (1,0) [0|254] "unitless" Vector__XXX
 SG_ CamraDefog_B_Actl : 50|1@0+ (1,0) [0|1] "SED" Vector__XXX
 SG_ HvacRec_Pc_Est : 23|7@0+ (1,0) [0|127] "Percent" Vector__XXX
 SG_ AutoStpHvacDelta_I_Est : 15|8@0+ (1,-192) [-192|62] "ampere" Vector__XXX
 SG_ HvacAir_Flw_Est : 16|9@0+ (0.5,0) [0|255.5] "liter/second"  BECM

BO_ 560 TransGearData_HS1: 8 GWM
 SG_ SelDrvMdeSwtch_D_Stat3 : 15|2@0+ (1,0) [0|3] "SED" Vector__XXX
 SG_ GearLvrPosActl_No_Cs : 31|8@0+ (1,0) [0|255] "Unitless" Vector__XXX
 SG_ GearLvrPosActl_No_Cnt : 19|4@0+ (1,0) [0|15] "Unitless" Vector__XXX
 SG_ TrnGbox_Rt_Actl : 47|16@0+ (0.001,0) [0|65.533] "Unitless" Vector__XXX
 SG_ TrnSrvcRqd_B_Rq : 8|1@0+ (1,0) [0|1] "SED" Vector__XXX
 SG_ TrnCnvtClu_D_Actl : 63|2@0+ (1,0) [0|3] "SED" Vector__XXX
 SG_ TrnShifActv_B_Actl : 0|1@0+ (1,0) [0|1] "SED" Vector__XXX
 SG_ RtmTerrMdeChng_D_Rdy : 58|3@0+ (1,0) [0|7] "SED" Vector__XXX
 SG_ RtmTerrMde_D_Actl : 61|3@0+ (1,0) [0|7] "SED" Vector__XXX
 SG_ GearLvrPos_D_Actl : 12|4@0+ (1,0) [0|15] "SED"  SOBDM_BCCM,BECM
 SG_ GboxOil_Te_Actl : 39|8@0+ (1,-60) [-60|193] "degC" Vector__XXX

BO_ 1034 GGCC_Config_Mgmt_ID_1: 8 GWM
 SG_ VehicleGGCCData : 7|64@0+ (1,0) [0|1.84467E+019] "mixed"  SOBDM_BCCM,BECM

BO_ 947 BodyInfo_3: 8 GWM
 SG_ ValetMode_D_Mem : 16|1@0+ (1,0) [0|1] "SED" Vector__XXX
 SG_ DimmingLvlEvnt_No_Actl : 18|2@0+ (1,0) [0|3] "unitless" Vector__XXX
 SG_ DrStatDrvErrCnt_B_Stat : 19|1@0+ (1,0) [0|1] "SED" Vector__XXX
 SG_ TurnLghtRight_D_Rq : 63|2@0+ (1,0) [0|3] "SED" Vector__XXX
 SG_ TurnLghtRightOn_B_Stat : 35|1@0+ (1,0) [0|1] "SED" Vector__XXX
 SG_ TurnLghtLeftOn_B_Stat : 54|1@0+ (1,0) [0|1] "SED" Vector__XXX
 SG_ FogLghtRearOn_B_Stat : 1|1@0+ (1,0) [0|1] "SED" Vector__XXX
 SG_ Backlit_LED_Status : 23|4@0+ (1,0) [0|15] "SED" Vector__XXX
 SG_ TurnLghtLeft_D_Rq : 9|2@0+ (1,0) [0|3] "SED" Vector__XXX
 SG_ FogLghtFrontOn_B_Stat : 56|1@0+ (1,0) [0|1] "SED" Vector__XXX
 SG_ IgnKeyType_D_Actl : 39|4@0+ (1,0) [0|15] "SED" Vector__XXX
 SG_ Parklamp_Status : 3|2@0+ (1,0) [0|3] "SED" Vector__XXX
 SG_ Litval : 47|8@0+ (1,0) [0|253] "SED" Vector__XXX
 SG_ Key_In_Ignition_Stat : 11|1@0+ (1,0) [0|1] "SED" Vector__XXX
 SG_ Ignition_Status : 7|4@0+ (1,0) [0|15] "SED"  SOBDM_BCCM,BECM
 SG_ Dimming_Lvl : 31|8@0+ (1,0) [0|253] "SED" Vector__XXX
 SG_ Day_Night_Status : 15|2@0+ (1,0) [0|3] "SED"  SOBDM_BCCM
 SG_ Remote_Start_Status : 13|2@0+ (1,0) [0|3] "SED" Vector__XXX
 SG_ DrStatTgate_B_Actl : 0|1@0+ (1,0) [0|1] "SED" Vector__XXX
 SG_ DrStatRr_B_Actl : 49|1@0+ (1,0) [0|1] "SED" Vector__XXX
 SG_ DrStatRl_B_Actl : 48|1@0+ (1,0) [0|1] "SED" Vector__XXX
 SG_ DrStatPsngr_B_Actl : 60|1@0+ (1,0) [0|1] "SED" Vector__XXX
 SG_ DrStatInnrTgate_B_Actl : 58|1@0+ (1,0) [0|1] "SED" Vector__XXX
 SG_ DrStatHood_B_Actl : 59|1@0+ (1,0) [0|1] "SED" Vector__XXX
 SG_ DrStatDrv_B_Actl : 61|1@0+ (1,0) [0|1] "SED" Vector__XXX
 SG_ PrkBrkActv_B_Actl : 55|1@0+ (1,0) [0|1] "SED" Vector__XXX
 SG_ LifeCycMde_D_Actl : 53|4@0+ (1,0) [0|15] "SED"  SOBDM_BCCM
 SG_ Delay_Accy : 57|1@0+ (1,0) [0|1] "SED" Vector__XXX
 SG_ CrashEvnt_D_Stat : 34|2@0+ (1,0) [0|3] "SED" Vector__XXX
 SG_ FuelPmpInhbt_B_Stat : 32|1@0+ (1,0) [0|1] "SED" Vector__XXX
 SG_ BodySrvcRqd_B_Rq : 10|1@0+ (1,0) [0|1] "SED" Vector__XXX

CM_ BO_ 374 "Programs w/o HS1 0x172 will need HS1 0x176 for GearPos_D_Actl.  Future MY Programs that choose c/o still require HS1 0x172. ";
CM_ SG_ 374 TrnRng_D_Rq "Powersplit HEVs with HF45, HPCM will Tx  this message.  For all other programs it will be Tx by PCM or TCM. ";
CM_ SG_ 374 TrnPrkSys_D_Actl "Powersplit HEVs with HF45, HPCM will Tx  this message.  For all other programs it will be Tx by PCM or TCM. ";
CM_ SG_ 374 GearLvr_D_ActlDrv "Powersplit HEVs with HF45, HPCM will Tx  this message.  For all other programs it will be Tx by PCM or TCM. ";
CM_ SG_ 374 GearPos_No_Cs "Powersplit HEVs with HF45, HPCM will Tx  this message.  For all other programs it will be Tx by PCM or TCM. ";
CM_ SG_ 374 GearPos_D_Trg "Powersplit HEVs with HF45, HPCM will Tx  this message.  For all other programs it will be Tx by PCM or TCM. ";
CM_ SG_ 374 GearPos_No_Cnt "Powersplit HEVs with HF45, HPCM will Tx  this message.  For all other programs it will be Tx by PCM or TCM. ";
CM_ SG_ 374 GearPos_D_Actl "Powersplit HEVs with HF45, HPCM will Tx  this message.  For all other programs it will be Tx by PCM or TCM. ";
CM_ SG_ 359 TrnAin_Tq_Actl "Signal not transmitted on HEV variances.";
CM_ SG_ 359 PlgActvArb_B_Actl "Only supported on PHEV programs.  PlgActvArb_B_Actl HPCM will Tx on Powersplit PHEV’s,  On MHT PHEVs the PCM_HEV will Tx and HPCM will Rx. 
";
CM_ SG_ 359 TrnAinTq_D_Qf "Signal not transmitted on HEV variances.";
CM_ BO_ 1085 "HS1 0x43D Tx by HS1 BECM, DCDC_HEV, DCDC_LISB
Or FrameGateway from FD1
Set to FixedPeriodic 50ms at all nodes so the transmit method and rate export from mdc to dbc
Program specific msg lists update attributes as needed.";
CM_ SG_ 1085 DcdcULo_U_Actl "Signal not transmitted on gas and diesel variants.";
CM_ SG_ 1085 DcdcUHi_I_Actl "Signal not transmitted on gas and diesel variants.";
CM_ SG_ 1085 DcdcUHi_U_Actl "Signal not transmitted on gas and diesel variants.";
CM_ BO_ 603 "48V mHEV: ECM_HEVDSL is Tx
MHT HEV: PCM_HEV is Tx
Powersplit HEV: SOBDMC_HPCM is Tx
";
CM_ SG_ 603 WhlDirAvgDrv_D_Actl "48V mHEV: ECM_HEVDSL is Tx,  MHT HEV: PCM_HEV is Tx,  Powersplit HEV: SOBDMC_HPCM is Tx";
CM_ SG_ 603 PrplTqMnRgen_B_Actl "48V mHEV: ECM_HEVDSL is Tx,  MHT HEV: PCM_HEV is Tx,  Powersplit HEV: SOBDMC_HPCM is Tx";
CM_ SG_ 603 BattTracCnnct_D_Rq "48V mHEV: ECM_HEVDSL is Tx,  MHT HEV: PCM_HEV is Tx,  Powersplit HEV: SOBDMC_HPCM is Tx";
CM_ SG_ 1088 HvacPrecondMode2_D_Rq "Signal not transmitted on vehicles that do not have the Fuel operated heater feature.";
CM_ SG_ 1088 HvacPrecondBlwr2_D_Rq "Signal not transmitted on vehicles that do not have the Fuel operated heater feature.";
CM_ SG_ 1072 StopLamp_B_RqTrlrBrk "Signal not transmitted on all variants.";
CM_ SG_ 1072 Outside_Air_Temp_Stat "Filtered value, i.e. same as disply for customer";
CM_ SG_ 514 EngAout_Tq_VacLimSpcN "Signal not transmitted on gas and diesel variances.";
CM_ SG_ 514 EngCylSync_No_Ctr "Signal not transmitted on gas and diesel variances.";
CM_ SG_ 514 GearRvrse_D_Actl "Do not implement GearRvrse_D_Actl  until eTracker 8804151 is approved, 11/24/09";
CM_ SG_ 1069 SlMde_D_Stat "IPC and HUD_ADV Receve from HS3 FGW 0x42D, not HS3 0x38A, MSG DCR 506.";
CM_ SG_ 1069 SlMde_D_RqDsply "IPC and HUD_ADV Receve from HS3 FGW 0x42D, not HS3 0x38A, MSG DCR 506.";
CM_ SG_ 1069 ObdWarmUp_B_Complt "Signal not transmitted on gas and diesel variants.";
CM_ SG_ 1069 EngMsgTxt_D_Rq "Signal not transmitted on diesel variants.";
CM_ SG_ 1069 EngClnt_Te_ActlDiag "Signal not transmitted on gas variants.";
CM_ SG_ 1069 EngLoad_Pc_CalcDiag "Signal not transmitted on gas variants.";
CM_ SG_ 1069 ApedPos_Pc_ActlDiag "Signal not transmitted on gas variants.";
CM_ BO_ 2015 "OBDII Request ($7DF) messages are for FNOS 1.0.1 only.
Diagnostic Functional Addressing ($7DF) and Dual Rate Periodic messages are for FNOS I3 only.";
CM_ SG_ 516 EngAout3_N_Actl "Signal not transmitted on gas and diesel variants.";
CM_ SG_ 516 ApedPosPcActl_No_Cnt "Signal not transmitted on gas and diesel variants.";
CM_ SG_ 516 ApedPosPcActl_No_Cs "Signal not transmitted on gas and diesel variants.";
CM_ BO_ 560 "MHT (U611/625) the HPCM will Rx 0x230 from the PCM_HEV
Powersplit FWD HEV’s (Cx482/3 430) the HPCM will Tx 0x230";
CM_ SG_ 560 SelDrvMdeSwtch_D_Stat3 "ECM_HEV does not support or Transmit signal.";
CM_ SG_ 560 GearLvrPosActl_No_Cs "Signal not transmitted on Gas & HEV variants. MHT(U611/625) HPCM Rx 0x230 from PCM_HEV. Powersplit FWD HEV’s(Cx482/3 430) HPCM Tx 0x230.";
CM_ SG_ 560 GearLvrPosActl_No_Cnt "Signal not transmitted on Gas & HEV variants. MHT(U611/625) HPCM Rx 0x230 from PCM_HEV. Powersplit FWD HEV’s(Cx482/3 430) HPCM Tx 0x230.";
CM_ SG_ 560 TrnGbox_Rt_Actl "Signal not transmitted on Gas & HEV variants. MHT(U611/625) HPCM Rx 0x230 from PCM_HEV. Powersplit FWD HEV’s(Cx482/3 430) HPCM Tx 0x230.";
CM_ SG_ 560 TrnSrvcRqd_B_Rq "Signal not transmitted on Diesel & HEV variants. MHT(U611/625) HPCM Rx 0x230 from PCM_HEV. Powersplit FWD HEV’s(Cx482/3 430) HPCM Tx 0x230.";
CM_ SG_ 560 TrnCnvtClu_D_Actl "Signal not transmitted on Gas & HEV variants. MHT(U611/625) HPCM Rx 0x230 from PCM_HEV. Powersplit FWD HEV’s(Cx482/3 430) HPCM Tx 0x230.";
CM_ SG_ 560 TrnShifActv_B_Actl "Signal not transmitted on HEV variants. MHT(U611/625) HPCM Rx 0x230 from PCM_HEV. Powersplit FWD HEV’s(Cx482/3 430) HPCM Tx 0x230.";
CM_ SG_ 560 GboxOil_Te_Actl "Signal not transmitted on HEV variants. MHT(U611/625) HPCM Rx 0x230 from PCM_HEV. Powersplit FWD HEV’s(Cx482/3 430) HPCM Tx 0x230.";
CM_ SG_ 1034 VehicleGGCCData "RCMGenSigTimeout=6000";
CM_ SG_ 947 Dimming_Lvl "Refer to Vehicle Interior Illum Dimming Ctrl Sys Eng Spec, Table 2

";
CM_ SG_ 947 PrkBrkActv_B_Actl "Signal not transmitted on vehicles with electric park brake. ";
BA_DEF_ BO_  "FrameRouting" STRING ;
BA_DEF_ BO_  "FrameGatewayNetwork" STRING ;
BA_DEF_ BO_  "NetworkInitialization" ENUM  "No","Yes";
BA_DEF_ BO_  "FrameGatewayId" HEX 0 1407;
BA_DEF_ BO_  "EventRateOfChange" INT 10 10000;
BA_DEF_ BO_  "GenMsgNrOfRepetition" INT 0 100;
BA_DEF_ BO_  "GenMsgDelayTime" INT 0 1000;
BA_DEF_ BO_  "GenMsgCycleTime" INT 0 100000;
BA_DEF_ BO_  "GenMsgSendType" ENUM  "FixedPeriodic","Event","EnabledPeriodic","NotUsed","NotUsed","EventPeriodic","NotUsed","NotUsed","NoMsgSendType";
BA_DEF_ SG_  "U_CD764_MY2022_Tx" ENUM  "No","Yes";
BA_DEF_ SG_  "U_U55X_MY2022_Tx" ENUM  "No","Yes";
BA_DEF_ SG_  "U_CD542_MY2021_Tx" ENUM  "No","Yes";
BA_DEF_ SG_  "ECGUsedTxSignal" ENUM  "No","Yes";
BA_DEF_ SG_  "U_T6_MCA_MY2020_Tx" ENUM  "No","Yes";
BA_DEF_ SG_  "U_P702_MY2021_Tx" ENUM  "No","Yes";
BA_DEF_ SG_  "U_CX727_MY2021_Tx" ENUM  "No","Yes";
BA_DEF_ SG_  "U_CD764_MY2022_Rx" ENUM  "No","Yes";
BA_DEF_ SG_  "U_U55X_MY2022_Rx" ENUM  "No","Yes";
BA_DEF_ SG_  "U_CD542_MY2021_Rx" ENUM  "No","Yes";
BA_DEF_ SG_  "ECGUsedRxSignal" ENUM  "No","Yes";
BA_DEF_ SG_  "U_T6_MCA_MY2020_Rx" ENUM  "No","Yes";
BA_DEF_ SG_  "U_P702_MY2021_Rx" ENUM  "No","Yes";
BA_DEF_ SG_  "U_CX727_MY2021_Rx" ENUM  "No","Yes";
BA_DEF_ SG_  "GenSigStartValue" HEX 0 268435455;
BA_DEF_ SG_  "MetaData" ENUM  "No","Yes";
BA_DEF_ SG_  "ContentDependant" ENUM  "No","Yes";
BA_DEF_ SG_  "GenSigStartValueInteger" INT 0 1000000000;
BA_DEF_ SG_  "UsedOnPgmDBC" ENUM  "No","Yes";
BA_DEF_ SG_  "WakeupSignal" ENUM  "No","Yes";
BA_DEF_ SG_  "GenSigInactiveValue" INT 0 100000;
BA_DEF_ SG_  "GenSigSendType" ENUM  "Cyclic","OnWrite","vector_leerstring","OnChange","vector_leerstring","IfActive","vector_leerstring","NoSigSendType";
BA_DEF_ BO_  "SCP_FreshnessValueLength" INT 0 512;
BA_DEF_ BO_  "SCP_FreshnessValueTxLength" INT 0 512;
BA_DEF_ BO_  "SCP_AuthInfoTxLength" INT 0 512;
BA_DEF_ BO_  "NmAsrMessage" ENUM  "No","Yes";
BA_DEF_ BO_  "DiagState" ENUM  "No","Yes";
BA_DEF_ BO_  "DiagRequest" ENUM  "No","Yes";
BA_DEF_ BO_  "DiagResponse" ENUM  "No","Yes";
BA_DEF_ BO_  "GenMsgILSupport" ENUM  "No","Yes";
BA_DEF_DEF_  "FrameRouting" "";
BA_DEF_DEF_  "FrameGatewayNetwork" "NONE";
BA_DEF_DEF_  "NetworkInitialization" "Yes";
BA_DEF_DEF_  "FrameGatewayId" 0;
BA_DEF_DEF_  "EventRateOfChange" 10000;
BA_DEF_DEF_  "GenMsgNrOfRepetition" 1;
BA_DEF_DEF_  "GenMsgDelayTime" 20;
BA_DEF_DEF_  "GenMsgCycleTime" 0;
BA_DEF_DEF_  "GenMsgSendType" "NoMsgSendType";
BA_DEF_DEF_  "U_CD764_MY2022_Tx" "No";
BA_DEF_DEF_  "U_U55X_MY2022_Tx" "No";
BA_DEF_DEF_  "U_CD542_MY2021_Tx" "No";
BA_DEF_DEF_  "ECGUsedTxSignal" "No";
BA_DEF_DEF_  "U_T6_MCA_MY2020_Tx" "No";
BA_DEF_DEF_  "U_P702_MY2021_Tx" "No";
BA_DEF_DEF_  "U_CX727_MY2021_Tx" "No";
BA_DEF_DEF_  "U_CD764_MY2022_Rx" "No";
BA_DEF_DEF_  "U_U55X_MY2022_Rx" "No";
BA_DEF_DEF_  "U_CD542_MY2021_Rx" "No";
BA_DEF_DEF_  "ECGUsedRxSignal" "No";
BA_DEF_DEF_  "U_T6_MCA_MY2020_Rx" "No";
BA_DEF_DEF_  "U_P702_MY2021_Rx" "No";
BA_DEF_DEF_  "U_CX727_MY2021_Rx" "No";
BA_DEF_DEF_  "GenSigStartValue" 0;
BA_DEF_DEF_  "MetaData" "No";
BA_DEF_DEF_  "ContentDependant" "No";
BA_DEF_DEF_  "GenSigStartValueInteger" 0;
BA_DEF_DEF_  "UsedOnPgmDBC" "Yes";
BA_DEF_DEF_  "WakeupSignal" "No";
BA_DEF_DEF_  "GenSigInactiveValue" 0;
BA_DEF_DEF_  "GenSigSendType" "NoSigSendType";
BA_DEF_DEF_  "SCP_FreshnessValueLength" 64;
BA_DEF_DEF_  "SCP_FreshnessValueTxLength" 11;
BA_DEF_DEF_  "SCP_AuthInfoTxLength" 53;
BA_DEF_DEF_  "NmAsrMessage" "No";
BA_DEF_DEF_  "DiagState" "No";
BA_DEF_DEF_  "DiagRequest" "No";
BA_DEF_DEF_  "DiagResponse" "No";
BA_DEF_DEF_  "GenMsgILSupport" "Yes";
BA_ "GenMsgILSupport" BO_ 2026 0;
BA_ "DiagResponse" BO_ 2026 1;
BA_ "GenMsgSendType" BO_ 2026 1;
BA_ "GenMsgDelayTime" BO_ 2026 0;
BA_ "NetworkInitialization" BO_ 2026 0;
BA_ "GenMsgSendType" BO_ 740 0;
BA_ "GenMsgCycleTime" BO_ 740 100;
BA_ "GenMsgSendType" BO_ 748 0;
BA_ "GenMsgCycleTime" BO_ 748 100;
BA_ "FrameGatewayId" BO_ 389 389;
BA_ "FrameGatewayNetwork" BO_ 389 "FD1_CAN";
BA_ "FrameRouting" BO_ 389 "FD1_CAN,0x185;";
BA_ "FrameGatewayId" BO_ 1055 1055;
BA_ "FrameGatewayNetwork" BO_ 1055 "FD1_CAN";
BA_ "FrameRouting" BO_ 1055 "FD1_CAN,0x41F;";
BA_ "FrameRouting" BO_ 132 "HS1_CAN,0x84";
BA_ "FrameGatewayId" BO_ 132 132;
BA_ "FrameGatewayNetwork" BO_ 132 "HS1_CAN";
BA_ "FrameGatewayId" BO_ 374 374;
BA_ "FrameGatewayNetwork" BO_ 374 "FD1_CAN";
BA_ "FrameRouting" BO_ 374 "FD1_CAN,0x176;";
BA_ "FrameRouting" BO_ 817 "HS1_CAN,0x331";
BA_ "FrameGatewayId" BO_ 817 817;
BA_ "FrameGatewayNetwork" BO_ 817 "HS1_CAN";
BA_ "GenMsgILSupport" BO_ 2018 0;
BA_ "DiagRequest" BO_ 2018 1;
BA_ "GenMsgSendType" BO_ 2018 1;
BA_ "GenMsgDelayTime" BO_ 2018 0;
BA_ "NetworkInitialization" BO_ 2018 0;
BA_ "FrameGatewayId" BO_ 359 359;
BA_ "FrameGatewayNetwork" BO_ 359 "FD1_CAN";
BA_ "FrameRouting" BO_ 359 "FD1_CAN,0x167;";
BA_ "FrameRouting" BO_ 1085 "HS1_CAN,0x43D";
BA_ "FrameGatewayId" BO_ 1085 1085;
BA_ "FrameGatewayNetwork" BO_ 1085 "HS1_CAN";
BA_ "FrameGatewayId" BO_ 603 603;
BA_ "FrameGatewayNetwork" BO_ 603 "FD1_CAN";
BA_ "FrameRouting" BO_ 603 "FD1_CAN,0x25B;";
BA_ "FrameGatewayId" BO_ 602 602;
BA_ "FrameGatewayNetwork" BO_ 602 "FD1_CAN";
BA_ "FrameRouting" BO_ 602 "FD1_CAN,0x25A;";
BA_ "GenMsgSendType" BO_ 587 0;
BA_ "GenMsgCycleTime" BO_ 587 100;
BA_ "FrameGatewayId" BO_ 1040 1040;
BA_ "FrameGatewayNetwork" BO_ 1040 "FD1_CAN";
BA_ "FrameRouting" BO_ 1040 "FD1_CAN,0x410;";
BA_ "FrameGatewayId" BO_ 1088 1088;
BA_ "FrameGatewayNetwork" BO_ 1088 "FD1_CAN";
BA_ "FrameRouting" BO_ 1088 "FD1_CAN,0x440;";
BA_ "GenMsgSendType" BO_ 1072 5;
BA_ "GenMsgCycleTime" BO_ 1072 100;
BA_ "GenMsgILSupport" BO_ 1438 0;
BA_ "NmAsrMessage" BO_ 1438 1;
BA_ "GenMsgSendType" BO_ 1438 0;
BA_ "GenMsgCycleTime" BO_ 1438 1000;
BA_ "NetworkInitialization" BO_ 1438 0;
BA_ "GenMsgSendType" BO_ 588 0;
BA_ "GenMsgCycleTime" BO_ 588 100;
BA_ "GenMsgSendType" BO_ 122 0;
BA_ "GenMsgCycleTime" BO_ 122 10;
BA_ "GenMsgDelayTime" BO_ 122 0;
BA_ "GenMsgILSupport" BO_ 1814 0;
BA_ "DiagRequest" BO_ 1814 1;
BA_ "GenMsgSendType" BO_ 1814 1;
BA_ "GenMsgDelayTime" BO_ 1814 0;
BA_ "NetworkInitialization" BO_ 1814 0;
BA_ "GenMsgILSupport" BO_ 1822 0;
BA_ "DiagResponse" BO_ 1822 1;
BA_ "GenMsgSendType" BO_ 1822 1;
BA_ "GenMsgDelayTime" BO_ 1822 0;
BA_ "NetworkInitialization" BO_ 1822 0;
BA_ "FrameRouting" BO_ 578 "HS1_CAN,0x242";
BA_ "FrameGatewayId" BO_ 578 578;
BA_ "FrameGatewayNetwork" BO_ 578 "HS1_CAN";
BA_ "FrameGatewayId" BO_ 514 514;
BA_ "FrameGatewayNetwork" BO_ 514 "FD1_CAN";
BA_ "FrameRouting" BO_ 514 "FD1_CAN,0x202;";
BA_ "FrameGatewayId" BO_ 1069 1069;
BA_ "FrameGatewayNetwork" BO_ 1069 "FD1_CAN";
BA_ "FrameRouting" BO_ 1069 "FD1_CAN,0x42D;";
BA_ "GenMsgILSupport" BO_ 2015 0;
BA_ "DiagState" BO_ 2015 1;
BA_ "GenMsgSendType" BO_ 2015 1;
BA_ "GenMsgDelayTime" BO_ 2015 0;
BA_ "NetworkInitialization" BO_ 2015 0;
BA_ "FrameGatewayId" BO_ 516 516;
BA_ "FrameGatewayNetwork" BO_ 516 "FD1_CAN";
BA_ "FrameRouting" BO_ 516 "FD1_CAN,0x204;";
BA_ "GenMsgDelayTime" BO_ 76 10;
BA_ "FrameGatewayId" BO_ 76 76;
BA_ "FrameGatewayNetwork" BO_ 76 "HS2_CAN";
BA_ "FrameRouting" BO_ 76 "HS2_CAN,0x4C;";
BA_ "GenMsgILSupport" BO_ 2028 0;
BA_ "DiagResponse" BO_ 2028 1;
BA_ "GenMsgSendType" BO_ 2028 1;
BA_ "GenMsgDelayTime" BO_ 2028 0;
BA_ "NetworkInitialization" BO_ 2028 0;
BA_ "GenMsgILSupport" BO_ 2020 0;
BA_ "DiagRequest" BO_ 2020 1;
BA_ "GenMsgSendType" BO_ 2020 1;
BA_ "GenMsgDelayTime" BO_ 2020 0;
BA_ "NetworkInitialization" BO_ 2020 0;
BA_ "FrameGatewayId" BO_ 862 862;
BA_ "FrameGatewayNetwork" BO_ 862 "MS1_CAN";
BA_ "FrameRouting" BO_ 862 "MS1_CAN,0x35E;";
BA_ "FrameGatewayId" BO_ 560 560;
BA_ "FrameGatewayNetwork" BO_ 560 "FD1_CAN";
BA_ "FrameRouting" BO_ 560 "FD1_CAN,0x230;";
BA_ "FrameRouting" BO_ 1034 "HS1_CAN,0x40A";
BA_ "FrameGatewayId" BO_ 1034 1034;
BA_ "FrameGatewayNetwork" BO_ 1034 "HS1_CAN";
BA_ "FrameRouting" BO_ 947 "HS1_CAN,0x3B3";
BA_ "FrameGatewayId" BO_ 947 947;
BA_ "FrameGatewayNetwork" BO_ 947 "HS1_CAN";
BA_ "GenSigSendType" SG_ 2026 TesterPhysicalResSOBDM 3;
BA_ "U_CX727_MY2021_Tx" SG_ 2026 TesterPhysicalResSOBDM 1;
BA_ "U_CD542_MY2021_Tx" SG_ 2026 TesterPhysicalResSOBDM 1;
BA_ "WakeupSignal" SG_ 740 PtWakeupActv2_B_Rq 1;
BA_ "U_CX727_MY2021_Rx" SG_ 740 PtWakeupActv2_B_Rq 1;
BA_ "U_P702_MY2021_Rx" SG_ 740 PtWakeupActv2_B_Rq 1;
BA_ "U_T6_MCA_MY2020_Rx" SG_ 740 PtWakeupActv2_B_Rq 1;
BA_ "U_CD542_MY2021_Rx" SG_ 740 PtWakeupActv2_B_Rq 1;
BA_ "U_U55X_MY2022_Rx" SG_ 740 PtWakeupActv2_B_Rq 1;
BA_ "U_CD764_MY2022_Rx" SG_ 740 PtWakeupActv2_B_Rq 1;
BA_ "U_CX727_MY2021_Rx" SG_ 740 BattChrg_U_Rq 1;
BA_ "U_CD542_MY2021_Rx" SG_ 740 BattChrg_U_Rq 1;
BA_ "U_CX727_MY2021_Tx" SG_ 740 BattChrg_U_Rq 1;
BA_ "U_CD542_MY2021_Tx" SG_ 740 BattChrg_U_Rq 1;
BA_ "U_CX727_MY2021_Tx" SG_ 740 BattTracSoc_Pc_Dpltd 1;
BA_ "U_CD542_MY2021_Tx" SG_ 740 BattTracSoc_Pc_Dpltd 1;
BA_ "U_CX727_MY2021_Rx" SG_ 740 BattAuxCnnct_B_Cmd 1;
BA_ "U_CD542_MY2021_Rx" SG_ 740 BattAuxCnnct_B_Cmd 1;
BA_ "U_P702_MY2021_Rx" SG_ 740 BattAuxCnnct_B_Cmd 1;
BA_ "U_CX727_MY2021_Tx" SG_ 740 BattAuxCnnct_B_Cmd 1;
BA_ "U_CD542_MY2021_Tx" SG_ 740 BattAuxCnnct_B_Cmd 1;
BA_ "U_CX727_MY2021_Rx" SG_ 748 ChrgrOutHi_U_Actl 1;
BA_ "U_CD542_MY2021_Rx" SG_ 748 ChrgrOutHi_U_Actl 1;
BA_ "ECGUsedRxSignal" SG_ 748 ChrgrOutHi_U_Actl 1;
BA_ "U_U55X_MY2022_Rx" SG_ 748 ChrgrOutHi_U_Actl 1;
BA_ "U_CX727_MY2021_Tx" SG_ 748 ChrgrOutHi_U_Actl 1;
BA_ "U_CD542_MY2021_Tx" SG_ 748 ChrgrOutHi_U_Actl 1;
BA_ "U_CX727_MY2021_Rx" SG_ 748 ChrgrOutHi_I_Actl 1;
BA_ "U_CD542_MY2021_Rx" SG_ 748 ChrgrOutHi_I_Actl 1;
BA_ "ECGUsedRxSignal" SG_ 748 ChrgrOutHi_I_Actl 1;
BA_ "U_U55X_MY2022_Rx" SG_ 748 ChrgrOutHi_I_Actl 1;
BA_ "U_CX727_MY2021_Tx" SG_ 748 ChrgrOutHi_I_Actl 1;
BA_ "U_CD542_MY2021_Tx" SG_ 748 ChrgrOutHi_I_Actl 1;
BA_ "ECGUsedRxSignal" SG_ 748 ChrgrIn_Pw_Mx 1;
BA_ "U_CD542_MY2021_Rx" SG_ 748 ChrgrIn_Pw_Mx 1;
BA_ "U_U55X_MY2022_Rx" SG_ 748 ChrgrIn_Pw_Mx 1;
BA_ "U_CX727_MY2021_Rx" SG_ 748 ChrgrIn_Pw_Mx 1;
BA_ "U_CX727_MY2021_Tx" SG_ 748 ChrgrIn_Pw_Mx 1;
BA_ "U_CD542_MY2021_Tx" SG_ 748 ChrgrIn_Pw_Mx 1;
BA_ "GenSigStartValueInteger" SG_ 748 PlgActv_D_ActlChrgr 3;
BA_ "GenSigStartValue" SG_ 748 PlgActv_D_ActlChrgr 2;
BA_ "U_CX727_MY2021_Rx" SG_ 748 PlgActv_D_ActlChrgr 1;
BA_ "ECGUsedRxSignal" SG_ 748 PlgActv_D_ActlChrgr 1;
BA_ "U_CD542_MY2021_Rx" SG_ 748 PlgActv_D_ActlChrgr 1;
BA_ "U_U55X_MY2022_Rx" SG_ 748 PlgActv_D_ActlChrgr 1;
BA_ "U_CX727_MY2021_Tx" SG_ 748 PlgActv_D_ActlChrgr 1;
BA_ "U_CD542_MY2021_Tx" SG_ 748 PlgActv_D_ActlChrgr 1;
BA_ "U_CX727_MY2021_Rx" SG_ 748 ChrgrRdyStat_D_Actl 1;
BA_ "U_CD542_MY2021_Rx" SG_ 748 ChrgrRdyStat_D_Actl 1;
BA_ "U_CX727_MY2021_Tx" SG_ 748 ChrgrRdyStat_D_Actl 1;
BA_ "U_CD542_MY2021_Tx" SG_ 748 ChrgrRdyStat_D_Actl 1;
BA_ "U_CX727_MY2021_Rx" SG_ 389 BattTracClntFlw_Pc_Rq 1;
BA_ "U_P702_MY2021_Rx" SG_ 389 BattTracClntFlw_Pc_Rq 1;
BA_ "U_CD542_MY2021_Rx" SG_ 389 BattTracClntFlw_Pc_Rq 1;
BA_ "U_CX727_MY2021_Rx" SG_ 389 HtrnAin_UHi_Actl 1;
BA_ "U_P702_MY2021_Rx" SG_ 389 HtrnAin_UHi_Actl 1;
BA_ "U_CD542_MY2021_Rx" SG_ 389 HtrnAin_UHi_Actl 1;
BA_ "U_CX727_MY2021_Rx" SG_ 389 HtrnHvilOpen_B_Actl 1;
BA_ "U_P702_MY2021_Rx" SG_ 389 HtrnHvilOpen_B_Actl 1;
BA_ "U_CD542_MY2021_Rx" SG_ 389 HtrnHvilOpen_B_Actl 1;
BA_ "U_CX727_MY2021_Rx" SG_ 389 PreCondActv_B_Actl 1;
BA_ "U_P702_MY2021_Rx" SG_ 389 PreCondActv_B_Actl 1;
BA_ "U_T6_MCA_MY2020_Rx" SG_ 389 PreCondActv_B_Actl 1;
BA_ "U_CD542_MY2021_Rx" SG_ 389 PreCondActv_B_Actl 1;
BA_ "U_U55X_MY2022_Rx" SG_ 389 PreCondActv_B_Actl 1;
BA_ "U_CD764_MY2022_Rx" SG_ 389 PreCondActv_B_Actl 1;
BA_ "GenSigStartValueInteger" SG_ 389 BattTrac_I_EstVsc 15000;
BA_ "U_CX727_MY2021_Rx" SG_ 389 BattTrac_I_EstVsc 1;
BA_ "U_P702_MY2021_Rx" SG_ 389 BattTrac_I_EstVsc 1;
BA_ "U_CD542_MY2021_Rx" SG_ 389 BattTrac_I_EstVsc 1;
BA_ "GenSigStartValueInteger" SG_ 1055 EcoCochShif_Pc_Dsply 255;
BA_ "GenSigStartValue" SG_ 1055 EcoCochShif_Pc_Dsply 255;
BA_ "GenSigStartValueInteger" SG_ 1055 EcoCochInst_Pc_Dsply 1000;
BA_ "GenSigStartValue" SG_ 1055 EcoCochInst_Pc_Dsply 100;
BA_ "GenSigStartValueInteger" SG_ 1055 EcoCochIdlFuel_Pc_Dsply 255;
BA_ "GenSigStartValue" SG_ 1055 EcoCochIdlFuel_Pc_Dsply 255;
BA_ "GenSigStartValueInteger" SG_ 1055 EcoCochDecel_Pc_Dsply 255;
BA_ "GenSigStartValue" SG_ 1055 EcoCochDecel_Pc_Dsply 255;
BA_ "GenSigStartValueInteger" SG_ 1055 EcoCochCrus_Pc_Dsply 255;
BA_ "GenSigStartValue" SG_ 1055 EcoCochCrus_Pc_Dsply 255;
BA_ "GenSigStartValueInteger" SG_ 1055 EcoCochA_Pc_Dsply 255;
BA_ "GenSigStartValue" SG_ 1055 EcoCochA_Pc_Dsply 255;
BA_ "U_CX727_MY2021_Tx" SG_ 132 GlblClkYr_No_Actl 1;
BA_ "U_P702_MY2021_Tx" SG_ 132 GlblClkYr_No_Actl 1;
BA_ "U_T6_MCA_MY2020_Tx" SG_ 132 GlblClkYr_No_Actl 1;
BA_ "U_CD542_MY2021_Tx" SG_ 132 GlblClkYr_No_Actl 1;
BA_ "U_U55X_MY2022_Tx" SG_ 132 GlblClkYr_No_Actl 1;
BA_ "U_CD764_MY2022_Tx" SG_ 132 GlblClkYr_No_Actl 1;
BA_ "GenSigSendType" SG_ 132 GlblClkScnd_No_Actl 3;
BA_ "U_CX727_MY2021_Tx" SG_ 132 GlblClkScnd_No_Actl 1;
BA_ "U_P702_MY2021_Tx" SG_ 132 GlblClkScnd_No_Actl 1;
BA_ "U_T6_MCA_MY2020_Tx" SG_ 132 GlblClkScnd_No_Actl 1;
BA_ "U_CD542_MY2021_Tx" SG_ 132 GlblClkScnd_No_Actl 1;
BA_ "U_U55X_MY2022_Tx" SG_ 132 GlblClkScnd_No_Actl 1;
BA_ "U_CD764_MY2022_Tx" SG_ 132 GlblClkScnd_No_Actl 1;
BA_ "U_CX727_MY2021_Tx" SG_ 132 GlblClkMnte_No_Actl 1;
BA_ "U_P702_MY2021_Tx" SG_ 132 GlblClkMnte_No_Actl 1;
BA_ "U_T6_MCA_MY2020_Tx" SG_ 132 GlblClkMnte_No_Actl 1;
BA_ "U_CD542_MY2021_Tx" SG_ 132 GlblClkMnte_No_Actl 1;
BA_ "U_U55X_MY2022_Tx" SG_ 132 GlblClkMnte_No_Actl 1;
BA_ "U_CD764_MY2022_Tx" SG_ 132 GlblClkMnte_No_Actl 1;
BA_ "U_CX727_MY2021_Tx" SG_ 132 GlblClkHr_No_Actl 1;
BA_ "U_P702_MY2021_Tx" SG_ 132 GlblClkHr_No_Actl 1;
BA_ "U_T6_MCA_MY2020_Tx" SG_ 132 GlblClkHr_No_Actl 1;
BA_ "U_CD542_MY2021_Tx" SG_ 132 GlblClkHr_No_Actl 1;
BA_ "U_U55X_MY2022_Tx" SG_ 132 GlblClkHr_No_Actl 1;
BA_ "U_CD764_MY2022_Tx" SG_ 132 GlblClkHr_No_Actl 1;
BA_ "U_CX727_MY2021_Tx" SG_ 132 GlblClkDay_No_Actl 1;
BA_ "U_P702_MY2021_Tx" SG_ 132 GlblClkDay_No_Actl 1;
BA_ "U_T6_MCA_MY2020_Tx" SG_ 132 GlblClkDay_No_Actl 1;
BA_ "U_CD542_MY2021_Tx" SG_ 132 GlblClkDay_No_Actl 1;
BA_ "U_U55X_MY2022_Tx" SG_ 132 GlblClkDay_No_Actl 1;
BA_ "U_CD764_MY2022_Tx" SG_ 132 GlblClkDay_No_Actl 1;
BA_ "GenSigSendType" SG_ 374 GearEngag_D_Actl 3;
BA_ "GenSigStartValueInteger" SG_ 374 TrnRng_D_Rq 14;
BA_ "ContentDependant" SG_ 374 TrnRng_D_Rq 1;
BA_ "GenSigStartValue" SG_ 374 TrnRng_D_Rq 14;
BA_ "GenSigSendType" SG_ 374 TrnRng_D_Rq 3;
BA_ "U_CX727_MY2021_Rx" SG_ 374 TrnRng_D_Rq 1;
BA_ "U_U55X_MY2022_Rx" SG_ 374 TrnRng_D_Rq 1;
BA_ "U_CD542_MY2021_Rx" SG_ 374 TrnRng_D_Rq 1;
BA_ "ContentDependant" SG_ 374 TrnPrkSys_D_Actl 1;
BA_ "GenSigSendType" SG_ 374 TrnPrkSys_D_Actl 3;
BA_ "U_CX727_MY2021_Rx" SG_ 374 TrnPrkSys_D_Actl 1;
BA_ "U_P702_MY2021_Rx" SG_ 374 TrnPrkSys_D_Actl 1;
BA_ "U_T6_MCA_MY2020_Rx" SG_ 374 TrnPrkSys_D_Actl 1;
BA_ "U_CD542_MY2021_Rx" SG_ 374 TrnPrkSys_D_Actl 1;
BA_ "U_U55X_MY2022_Rx" SG_ 374 TrnPrkSys_D_Actl 1;
BA_ "U_CD764_MY2022_Rx" SG_ 374 TrnPrkSys_D_Actl 1;
BA_ "ContentDependant" SG_ 374 GearLvr_D_ActlDrv 1;
BA_ "GenSigSendType" SG_ 374 GearLvr_D_ActlDrv 3;
BA_ "U_CX727_MY2021_Rx" SG_ 374 GearLvr_D_ActlDrv 1;
BA_ "U_U55X_MY2022_Rx" SG_ 374 GearLvr_D_ActlDrv 1;
BA_ "ContentDependant" SG_ 374 GearPos_No_Cs 1;
BA_ "MetaData" SG_ 374 GearPos_No_Cs 1;
BA_ "U_CX727_MY2021_Rx" SG_ 374 GearPos_No_Cs 1;
BA_ "U_U55X_MY2022_Rx" SG_ 374 GearPos_No_Cs 1;
BA_ "GenSigStartValueInteger" SG_ 374 GearPos_D_Trg 15;
BA_ "ContentDependant" SG_ 374 GearPos_D_Trg 1;
BA_ "GenSigStartValue" SG_ 374 GearPos_D_Trg 15;
BA_ "GenSigSendType" SG_ 374 GearPos_D_Trg 3;
BA_ "U_CX727_MY2021_Rx" SG_ 374 GearPos_D_Trg 1;
BA_ "U_U55X_MY2022_Rx" SG_ 374 GearPos_D_Trg 1;
BA_ "ContentDependant" SG_ 374 GearPos_No_Cnt 1;
BA_ "MetaData" SG_ 374 GearPos_No_Cnt 1;
BA_ "U_CX727_MY2021_Rx" SG_ 374 GearPos_No_Cnt 1;
BA_ "U_U55X_MY2022_Rx" SG_ 374 GearPos_No_Cnt 1;
BA_ "U_CX727_MY2021_Rx" SG_ 374 TrnIgnOffDly_T_Rq 1;
BA_ "U_P702_MY2021_Rx" SG_ 374 TrnIgnOffDly_T_Rq 1;
BA_ "U_T6_MCA_MY2020_Rx" SG_ 374 TrnIgnOffDly_T_Rq 1;
BA_ "U_CD542_MY2021_Rx" SG_ 374 TrnIgnOffDly_T_Rq 1;
BA_ "U_U55X_MY2022_Rx" SG_ 374 TrnIgnOffDly_T_Rq 1;
BA_ "U_CD764_MY2022_Rx" SG_ 374 TrnIgnOffDly_T_Rq 1;
BA_ "GenSigStartValueInteger" SG_ 374 GearPos_D_Actl 15;
BA_ "ContentDependant" SG_ 374 GearPos_D_Actl 1;
BA_ "GenSigStartValue" SG_ 374 GearPos_D_Actl 15;
BA_ "GenSigSendType" SG_ 374 GearPos_D_Actl 3;
BA_ "U_CX727_MY2021_Rx" SG_ 374 GearPos_D_Actl 1;
BA_ "U_U55X_MY2022_Rx" SG_ 374 GearPos_D_Actl 1;
BA_ "GenSigSendType" SG_ 817 ChildLckMde_B_Stat 3;
BA_ "U_CX727_MY2021_Tx" SG_ 817 ChildLckMde_B_Stat 1;
BA_ "U_P702_MY2021_Tx" SG_ 817 ChildLckMde_B_Stat 1;
BA_ "U_T6_MCA_MY2020_Tx" SG_ 817 ChildLckMde_B_Stat 1;
BA_ "U_CD542_MY2021_Tx" SG_ 817 ChildLckMde_B_Stat 1;
BA_ "U_U55X_MY2022_Tx" SG_ 817 ChildLckMde_B_Stat 1;
BA_ "U_CD764_MY2022_Tx" SG_ 817 ChildLckMde_B_Stat 1;
BA_ "GenSigSendType" SG_ 817 VehLckInd_D_Rq 3;
BA_ "U_CX727_MY2021_Tx" SG_ 817 VehLckInd_D_Rq 1;
BA_ "U_P702_MY2021_Tx" SG_ 817 VehLckInd_D_Rq 1;
BA_ "U_T6_MCA_MY2020_Tx" SG_ 817 VehLckInd_D_Rq 1;
BA_ "U_CD542_MY2021_Tx" SG_ 817 VehLckInd_D_Rq 1;
BA_ "U_U55X_MY2022_Tx" SG_ 817 VehLckInd_D_Rq 1;
BA_ "U_CD764_MY2022_Tx" SG_ 817 VehLckInd_D_Rq 1;
BA_ "WakeupSignal" SG_ 817 DrTgateOpen_B_Rq 1;
BA_ "GenSigSendType" SG_ 817 DrTgateOpen_B_Rq 3;
BA_ "U_CX727_MY2021_Tx" SG_ 817 DrTgateOpen_B_Rq 1;
BA_ "U_P702_MY2021_Tx" SG_ 817 DrTgateOpen_B_Rq 1;
BA_ "U_T6_MCA_MY2020_Tx" SG_ 817 DrTgateOpen_B_Rq 1;
BA_ "U_CD542_MY2021_Tx" SG_ 817 DrTgateOpen_B_Rq 1;
BA_ "U_U55X_MY2022_Tx" SG_ 817 DrTgateOpen_B_Rq 1;
BA_ "U_CD764_MY2022_Tx" SG_ 817 DrTgateOpen_B_Rq 1;
BA_ "WakeupSignal" SG_ 817 DrTgateExtSwMde_B_Stat 1;
BA_ "GenSigSendType" SG_ 817 DrTgateExtSwMde_B_Stat 3;
BA_ "U_CX727_MY2021_Tx" SG_ 817 DrTgateExtSwMde_B_Stat 1;
BA_ "U_P702_MY2021_Tx" SG_ 817 DrTgateExtSwMde_B_Stat 1;
BA_ "U_T6_MCA_MY2020_Tx" SG_ 817 DrTgateExtSwMde_B_Stat 1;
BA_ "U_CD542_MY2021_Tx" SG_ 817 DrTgateExtSwMde_B_Stat 1;
BA_ "U_U55X_MY2022_Tx" SG_ 817 DrTgateExtSwMde_B_Stat 1;
BA_ "U_CD764_MY2022_Tx" SG_ 817 DrTgateExtSwMde_B_Stat 1;
BA_ "WakeupSignal" SG_ 817 Remote_Device_Feedback 1;
BA_ "GenSigSendType" SG_ 817 Remote_Device_Feedback 3;
BA_ "U_T6_MCA_MY2020_Rx" SG_ 817 Remote_Device_Feedback 1;
BA_ "ECGUsedRxSignal" SG_ 817 Remote_Device_Feedback 1;
BA_ "U_CD542_MY2021_Rx" SG_ 817 Remote_Device_Feedback 1;
BA_ "U_U55X_MY2022_Rx" SG_ 817 Remote_Device_Feedback 1;
BA_ "U_CD764_MY2022_Rx" SG_ 817 Remote_Device_Feedback 1;
BA_ "U_CX727_MY2021_Tx" SG_ 817 Remote_Device_Feedback 1;
BA_ "U_P702_MY2021_Tx" SG_ 817 Remote_Device_Feedback 1;
BA_ "U_T6_MCA_MY2020_Tx" SG_ 817 Remote_Device_Feedback 1;
BA_ "U_CD542_MY2021_Tx" SG_ 817 Remote_Device_Feedback 1;
BA_ "U_U55X_MY2022_Tx" SG_ 817 Remote_Device_Feedback 1;
BA_ "U_CD764_MY2022_Tx" SG_ 817 Remote_Device_Feedback 1;
BA_ "WakeupSignal" SG_ 817 Veh_Lock_Requestor 1;
BA_ "GenSigSendType" SG_ 817 Veh_Lock_Requestor 3;
BA_ "U_CX727_MY2021_Tx" SG_ 817 Veh_Lock_Requestor 1;
BA_ "U_P702_MY2021_Tx" SG_ 817 Veh_Lock_Requestor 1;
BA_ "U_T6_MCA_MY2020_Tx" SG_ 817 Veh_Lock_Requestor 1;
BA_ "U_CD542_MY2021_Tx" SG_ 817 Veh_Lock_Requestor 1;
BA_ "U_U55X_MY2022_Tx" SG_ 817 Veh_Lock_Requestor 1;
BA_ "U_CD764_MY2022_Tx" SG_ 817 Veh_Lock_Requestor 1;
BA_ "WakeupSignal" SG_ 817 R_Pwr_Sliding_Dr_Rqst 1;
BA_ "GenSigSendType" SG_ 817 R_Pwr_Sliding_Dr_Rqst 3;
BA_ "U_CX727_MY2021_Tx" SG_ 817 R_Pwr_Sliding_Dr_Rqst 1;
BA_ "U_P702_MY2021_Tx" SG_ 817 R_Pwr_Sliding_Dr_Rqst 1;
BA_ "U_T6_MCA_MY2020_Tx" SG_ 817 R_Pwr_Sliding_Dr_Rqst 1;
BA_ "U_CD542_MY2021_Tx" SG_ 817 R_Pwr_Sliding_Dr_Rqst 1;
BA_ "U_U55X_MY2022_Tx" SG_ 817 R_Pwr_Sliding_Dr_Rqst 1;
BA_ "U_CD764_MY2022_Tx" SG_ 817 R_Pwr_Sliding_Dr_Rqst 1;
BA_ "WakeupSignal" SG_ 817 Power_Liftgate_Rqst 1;
BA_ "GenSigSendType" SG_ 817 Power_Liftgate_Rqst 3;
BA_ "U_CX727_MY2021_Tx" SG_ 817 Power_Liftgate_Rqst 1;
BA_ "U_P702_MY2021_Tx" SG_ 817 Power_Liftgate_Rqst 1;
BA_ "U_T6_MCA_MY2020_Tx" SG_ 817 Power_Liftgate_Rqst 1;
BA_ "U_CD542_MY2021_Tx" SG_ 817 Power_Liftgate_Rqst 1;
BA_ "U_U55X_MY2022_Tx" SG_ 817 Power_Liftgate_Rqst 1;
BA_ "U_CD764_MY2022_Tx" SG_ 817 Power_Liftgate_Rqst 1;
BA_ "WakeupSignal" SG_ 817 Veh_Lock_EvNum 1;
BA_ "GenSigSendType" SG_ 817 Veh_Lock_EvNum 3;
BA_ "U_CX727_MY2021_Tx" SG_ 817 Veh_Lock_EvNum 1;
BA_ "U_P702_MY2021_Tx" SG_ 817 Veh_Lock_EvNum 1;
BA_ "U_T6_MCA_MY2020_Tx" SG_ 817 Veh_Lock_EvNum 1;
BA_ "U_CD542_MY2021_Tx" SG_ 817 Veh_Lock_EvNum 1;
BA_ "U_U55X_MY2022_Tx" SG_ 817 Veh_Lock_EvNum 1;
BA_ "U_CD764_MY2022_Tx" SG_ 817 Veh_Lock_EvNum 1;
BA_ "WakeupSignal" SG_ 817 Power_Decklid_Rqst 1;
BA_ "GenSigSendType" SG_ 817 Power_Decklid_Rqst 3;
BA_ "U_CX727_MY2021_Tx" SG_ 817 Power_Decklid_Rqst 1;
BA_ "U_P702_MY2021_Tx" SG_ 817 Power_Decklid_Rqst 1;
BA_ "U_T6_MCA_MY2020_Tx" SG_ 817 Power_Decklid_Rqst 1;
BA_ "U_CD542_MY2021_Tx" SG_ 817 Power_Decklid_Rqst 1;
BA_ "U_U55X_MY2022_Tx" SG_ 817 Power_Decklid_Rqst 1;
BA_ "U_CD764_MY2022_Tx" SG_ 817 Power_Decklid_Rqst 1;
BA_ "WakeupSignal" SG_ 817 L_Pwr_Sliding_Dr_Rqst 1;
BA_ "GenSigSendType" SG_ 817 L_Pwr_Sliding_Dr_Rqst 3;
BA_ "U_CX727_MY2021_Tx" SG_ 817 L_Pwr_Sliding_Dr_Rqst 1;
BA_ "U_P702_MY2021_Tx" SG_ 817 L_Pwr_Sliding_Dr_Rqst 1;
BA_ "U_T6_MCA_MY2020_Tx" SG_ 817 L_Pwr_Sliding_Dr_Rqst 1;
BA_ "U_CD542_MY2021_Tx" SG_ 817 L_Pwr_Sliding_Dr_Rqst 1;
BA_ "U_U55X_MY2022_Tx" SG_ 817 L_Pwr_Sliding_Dr_Rqst 1;
BA_ "U_CD764_MY2022_Tx" SG_ 817 L_Pwr_Sliding_Dr_Rqst 1;
BA_ "WakeupSignal" SG_ 817 Keyfob_Pad_Msg_Count 1;
BA_ "GenSigSendType" SG_ 817 Keyfob_Pad_Msg_Count 3;
BA_ "U_CX727_MY2021_Tx" SG_ 817 Keyfob_Pad_Msg_Count 1;
BA_ "U_P702_MY2021_Tx" SG_ 817 Keyfob_Pad_Msg_Count 1;
BA_ "U_T6_MCA_MY2020_Tx" SG_ 817 Keyfob_Pad_Msg_Count 1;
BA_ "U_CD542_MY2021_Tx" SG_ 817 Keyfob_Pad_Msg_Count 1;
BA_ "U_U55X_MY2022_Tx" SG_ 817 Keyfob_Pad_Msg_Count 1;
BA_ "U_CD764_MY2022_Tx" SG_ 817 Keyfob_Pad_Msg_Count 1;
BA_ "GenSigSendType" SG_ 817 Veh_Lock_Sub_Id 3;
BA_ "U_CX727_MY2021_Tx" SG_ 817 Veh_Lock_Sub_Id 1;
BA_ "U_P702_MY2021_Tx" SG_ 817 Veh_Lock_Sub_Id 1;
BA_ "U_T6_MCA_MY2020_Tx" SG_ 817 Veh_Lock_Sub_Id 1;
BA_ "U_CD542_MY2021_Tx" SG_ 817 Veh_Lock_Sub_Id 1;
BA_ "U_U55X_MY2022_Tx" SG_ 817 Veh_Lock_Sub_Id 1;
BA_ "U_CD764_MY2022_Tx" SG_ 817 Veh_Lock_Sub_Id 1;
BA_ "WakeupSignal" SG_ 817 Veh_Lock_Status 1;
BA_ "GenSigStartValueInteger" SG_ 817 Veh_Lock_Status 1;
BA_ "GenSigStartValue" SG_ 817 Veh_Lock_Status 1;
BA_ "GenSigSendType" SG_ 817 Veh_Lock_Status 3;
BA_ "U_T6_MCA_MY2020_Rx" SG_ 817 Veh_Lock_Status 1;
BA_ "ECGUsedRxSignal" SG_ 817 Veh_Lock_Status 1;
BA_ "U_CD542_MY2021_Rx" SG_ 817 Veh_Lock_Status 1;
BA_ "U_U55X_MY2022_Rx" SG_ 817 Veh_Lock_Status 1;
BA_ "U_CD764_MY2022_Rx" SG_ 817 Veh_Lock_Status 1;
BA_ "U_CX727_MY2021_Tx" SG_ 817 Veh_Lock_Status 1;
BA_ "U_P702_MY2021_Tx" SG_ 817 Veh_Lock_Status 1;
BA_ "U_T6_MCA_MY2020_Tx" SG_ 817 Veh_Lock_Status 1;
BA_ "U_CD542_MY2021_Tx" SG_ 817 Veh_Lock_Status 1;
BA_ "U_U55X_MY2022_Tx" SG_ 817 Veh_Lock_Status 1;
BA_ "U_CD764_MY2022_Tx" SG_ 817 Veh_Lock_Status 1;
BA_ "WakeupSignal" SG_ 817 ChildLck_D_Dsply 1;
BA_ "GenSigStartValueInteger" SG_ 817 ChildLck_D_Dsply 1;
BA_ "GenSigStartValue" SG_ 817 ChildLck_D_Dsply 1;
BA_ "GenSigSendType" SG_ 817 ChildLck_D_Dsply 3;
BA_ "U_CX727_MY2021_Tx" SG_ 817 ChildLck_D_Dsply 1;
BA_ "U_P702_MY2021_Tx" SG_ 817 ChildLck_D_Dsply 1;
BA_ "U_T6_MCA_MY2020_Tx" SG_ 817 ChildLck_D_Dsply 1;
BA_ "U_CD542_MY2021_Tx" SG_ 817 ChildLck_D_Dsply 1;
BA_ "U_U55X_MY2022_Tx" SG_ 817 ChildLck_D_Dsply 1;
BA_ "U_CD764_MY2022_Tx" SG_ 817 ChildLck_D_Dsply 1;
BA_ "GenSigSendType" SG_ 817 WindowLockout_B_Stat 3;
BA_ "U_CX727_MY2021_Tx" SG_ 817 WindowLockout_B_Stat 1;
BA_ "U_P702_MY2021_Tx" SG_ 817 WindowLockout_B_Stat 1;
BA_ "U_T6_MCA_MY2020_Tx" SG_ 817 WindowLockout_B_Stat 1;
BA_ "U_CD542_MY2021_Tx" SG_ 817 WindowLockout_B_Stat 1;
BA_ "U_U55X_MY2022_Tx" SG_ 817 WindowLockout_B_Stat 1;
BA_ "U_CD764_MY2022_Tx" SG_ 817 WindowLockout_B_Stat 1;
BA_ "GenSigSendType" SG_ 817 RollCodeUnlock 3;
BA_ "U_T6_MCA_MY2020_Rx" SG_ 817 RollCodeUnlock 1;
BA_ "ECGUsedRxSignal" SG_ 817 RollCodeUnlock 1;
BA_ "U_CD542_MY2021_Rx" SG_ 817 RollCodeUnlock 1;
BA_ "U_U55X_MY2022_Rx" SG_ 817 RollCodeUnlock 1;
BA_ "U_CD764_MY2022_Rx" SG_ 817 RollCodeUnlock 1;
BA_ "U_CX727_MY2021_Tx" SG_ 817 RollCodeUnlock 1;
BA_ "U_P702_MY2021_Tx" SG_ 817 RollCodeUnlock 1;
BA_ "U_T6_MCA_MY2020_Tx" SG_ 817 RollCodeUnlock 1;
BA_ "U_CD542_MY2021_Tx" SG_ 817 RollCodeUnlock 1;
BA_ "U_U55X_MY2022_Tx" SG_ 817 RollCodeUnlock 1;
BA_ "U_CD764_MY2022_Tx" SG_ 817 RollCodeUnlock 1;
BA_ "WakeupSignal" SG_ 817 Lockmsgtxt_D_Rq 1;
BA_ "GenSigSendType" SG_ 817 Lockmsgtxt_D_Rq 3;
BA_ "U_CX727_MY2021_Tx" SG_ 817 Lockmsgtxt_D_Rq 1;
BA_ "U_P702_MY2021_Tx" SG_ 817 Lockmsgtxt_D_Rq 1;
BA_ "U_T6_MCA_MY2020_Tx" SG_ 817 Lockmsgtxt_D_Rq 1;
BA_ "U_CD542_MY2021_Tx" SG_ 817 Lockmsgtxt_D_Rq 1;
BA_ "U_U55X_MY2022_Tx" SG_ 817 Lockmsgtxt_D_Rq 1;
BA_ "U_CD764_MY2022_Tx" SG_ 817 Lockmsgtxt_D_Rq 1;
BA_ "GenSigSendType" SG_ 817 FobComm_D_Stat 3;
BA_ "U_CX727_MY2021_Tx" SG_ 817 FobComm_D_Stat 1;
BA_ "U_P702_MY2021_Tx" SG_ 817 FobComm_D_Stat 1;
BA_ "U_T6_MCA_MY2020_Tx" SG_ 817 FobComm_D_Stat 1;
BA_ "U_CD542_MY2021_Tx" SG_ 817 FobComm_D_Stat 1;
BA_ "U_U55X_MY2022_Tx" SG_ 817 FobComm_D_Stat 1;
BA_ "U_CD764_MY2022_Tx" SG_ 817 FobComm_D_Stat 1;
BA_ "WakeupSignal" SG_ 817 LockInhibit 1;
BA_ "GenSigSendType" SG_ 817 LockInhibit 3;
BA_ "U_CX727_MY2021_Tx" SG_ 817 LockInhibit 1;
BA_ "U_P702_MY2021_Tx" SG_ 817 LockInhibit 1;
BA_ "U_T6_MCA_MY2020_Tx" SG_ 817 LockInhibit 1;
BA_ "U_CD542_MY2021_Tx" SG_ 817 LockInhibit 1;
BA_ "U_U55X_MY2022_Tx" SG_ 817 LockInhibit 1;
BA_ "U_CD764_MY2022_Tx" SG_ 817 LockInhibit 1;
BA_ "GenSigSendType" SG_ 2018 TesterPhysicalReqSOBDM 3;
BA_ "U_CX727_MY2021_Rx" SG_ 2018 TesterPhysicalReqSOBDM 1;
BA_ "U_CD542_MY2021_Rx" SG_ 2018 TesterPhysicalReqSOBDM 1;
BA_ "GenSigStartValueInteger" SG_ 359 PrplWhlRgenMn_Tq_Actl 4095;
BA_ "ContentDependant" SG_ 359 TrnAin_Tq_Actl 1;
BA_ "U_U55X_MY2022_Rx" SG_ 359 PrplWhlTot2_Tq_Actl 1;
BA_ "U_CX727_MY2021_Rx" SG_ 359 PwPckTq_D_Stat 1;
BA_ "U_P702_MY2021_Rx" SG_ 359 PwPckTq_D_Stat 1;
BA_ "U_CD542_MY2021_Rx" SG_ 359 PwPckTq_D_Stat 1;
BA_ "U_T6_MCA_MY2020_Rx" SG_ 359 PwPckTq_D_Stat 1;
BA_ "U_U55X_MY2022_Rx" SG_ 359 PwPckTq_D_Stat 1;
BA_ "U_CD764_MY2022_Rx" SG_ 359 PwPckTq_D_Stat 1;
BA_ "U_CX727_MY2021_Rx" SG_ 359 Eng_D_Stat 1;
BA_ "U_P702_MY2021_Rx" SG_ 359 Eng_D_Stat 1;
BA_ "U_T6_MCA_MY2020_Rx" SG_ 359 Eng_D_Stat 1;
BA_ "U_CD542_MY2021_Rx" SG_ 359 Eng_D_Stat 1;
BA_ "U_U55X_MY2022_Rx" SG_ 359 Eng_D_Stat 1;
BA_ "U_CD764_MY2022_Rx" SG_ 359 Eng_D_Stat 1;
BA_ "GenSigStartValueInteger" SG_ 359 PlgActvArb_B_Actl 1;
BA_ "ContentDependant" SG_ 359 PlgActvArb_B_Actl 1;
BA_ "GenSigStartValue" SG_ 359 PlgActvArb_B_Actl 1;
BA_ "U_CX727_MY2021_Rx" SG_ 359 PlgActvArb_B_Actl 1;
BA_ "U_P702_MY2021_Rx" SG_ 359 PlgActvArb_B_Actl 1;
BA_ "U_T6_MCA_MY2020_Rx" SG_ 359 PlgActvArb_B_Actl 1;
BA_ "U_CD542_MY2021_Rx" SG_ 359 PlgActvArb_B_Actl 1;
BA_ "U_U55X_MY2022_Rx" SG_ 359 PlgActvArb_B_Actl 1;
BA_ "U_CD764_MY2022_Rx" SG_ 359 PlgActvArb_B_Actl 1;
BA_ "U_CX727_MY2021_Rx" SG_ 359 ElPw_D_Stat 1;
BA_ "U_P702_MY2021_Rx" SG_ 359 ElPw_D_Stat 1;
BA_ "U_T6_MCA_MY2020_Rx" SG_ 359 ElPw_D_Stat 1;
BA_ "U_CD542_MY2021_Rx" SG_ 359 ElPw_D_Stat 1;
BA_ "U_U55X_MY2022_Rx" SG_ 359 ElPw_D_Stat 1;
BA_ "U_CD764_MY2022_Rx" SG_ 359 ElPw_D_Stat 1;
BA_ "ContentDependant" SG_ 359 TrnAinTq_D_Qf 1;
BA_ "MetaData" SG_ 359 TrnAinTq_D_Qf 1;
BA_ "U_CX727_MY2021_Rx" SG_ 1085 PwSrcULoOvrTe_B_Actl 1;
BA_ "U_P702_MY2021_Rx" SG_ 1085 PwSrcULoOvrTe_B_Actl 1;
BA_ "U_T6_MCA_MY2020_Rx" SG_ 1085 PwSrcULoOvrTe_B_Actl 1;
BA_ "U_U55X_MY2022_Rx" SG_ 1085 PwSrcULoOvrTe_B_Actl 1;
BA_ "U_CD764_MY2022_Rx" SG_ 1085 PwSrcULoOvrTe_B_Actl 1;
BA_ "ECGUsedRxSignal" SG_ 1085 PwSrcULoOvrTe_B_Actl 1;
BA_ "U_CX727_MY2021_Tx" SG_ 1085 PwSrcULoOvrTe_B_Actl 1;
BA_ "U_P702_MY2021_Tx" SG_ 1085 PwSrcULoOvrTe_B_Actl 1;
BA_ "U_CD542_MY2021_Tx" SG_ 1085 PwSrcULoOvrTe_B_Actl 1;
BA_ "U_CX727_MY2021_Rx" SG_ 1085 PwSrcULoOn_B_Actl 1;
BA_ "ECGUsedRxSignal" SG_ 1085 PwSrcULoOn_B_Actl 1;
BA_ "U_U55X_MY2022_Rx" SG_ 1085 PwSrcULoOn_B_Actl 1;
BA_ "U_CX727_MY2021_Tx" SG_ 1085 PwSrcULoOn_B_Actl 1;
BA_ "U_P702_MY2021_Tx" SG_ 1085 PwSrcULoOn_B_Actl 1;
BA_ "U_CD542_MY2021_Tx" SG_ 1085 PwSrcULoOn_B_Actl 1;
BA_ "U_CX727_MY2021_Rx" SG_ 1085 PwSrcULoFalt_D_Stat 1;
BA_ "U_P702_MY2021_Rx" SG_ 1085 PwSrcULoFalt_D_Stat 1;
BA_ "U_T6_MCA_MY2020_Rx" SG_ 1085 PwSrcULoFalt_D_Stat 1;
BA_ "U_U55X_MY2022_Rx" SG_ 1085 PwSrcULoFalt_D_Stat 1;
BA_ "U_CD764_MY2022_Rx" SG_ 1085 PwSrcULoFalt_D_Stat 1;
BA_ "ECGUsedRxSignal" SG_ 1085 PwSrcULoFalt_D_Stat 1;
BA_ "U_CX727_MY2021_Tx" SG_ 1085 PwSrcULoFalt_D_Stat 1;
BA_ "U_P702_MY2021_Tx" SG_ 1085 PwSrcULoFalt_D_Stat 1;
BA_ "U_CD542_MY2021_Tx" SG_ 1085 PwSrcULoFalt_D_Stat 1;
BA_ "U_CX727_MY2021_Rx" SG_ 1085 PwSrcULoDcnnt_B_Stat 1;
BA_ "U_P702_MY2021_Rx" SG_ 1085 PwSrcULoDcnnt_B_Stat 1;
BA_ "U_T6_MCA_MY2020_Rx" SG_ 1085 PwSrcULoDcnnt_B_Stat 1;
BA_ "U_CD542_MY2021_Rx" SG_ 1085 PwSrcULoDcnnt_B_Stat 1;
BA_ "U_U55X_MY2022_Rx" SG_ 1085 PwSrcULoDcnnt_B_Stat 1;
BA_ "U_CD764_MY2022_Rx" SG_ 1085 PwSrcULoDcnnt_B_Stat 1;
BA_ "U_CX727_MY2021_Tx" SG_ 1085 PwSrcULoDcnnt_B_Stat 1;
BA_ "U_P702_MY2021_Tx" SG_ 1085 PwSrcULoDcnnt_B_Stat 1;
BA_ "U_CD542_MY2021_Tx" SG_ 1085 PwSrcULoDcnnt_B_Stat 1;
BA_ "U_CX727_MY2021_Rx" SG_ 1085 PwSrcULo_Pc_Mx 1;
BA_ "U_P702_MY2021_Rx" SG_ 1085 PwSrcULo_Pc_Mx 1;
BA_ "U_T6_MCA_MY2020_Rx" SG_ 1085 PwSrcULo_Pc_Mx 1;
BA_ "U_CD542_MY2021_Rx" SG_ 1085 PwSrcULo_Pc_Mx 1;
BA_ "U_U55X_MY2022_Rx" SG_ 1085 PwSrcULo_Pc_Mx 1;
BA_ "U_CD764_MY2022_Rx" SG_ 1085 PwSrcULo_Pc_Mx 1;
BA_ "U_CX727_MY2021_Tx" SG_ 1085 PwSrcULo_Pc_Mx 1;
BA_ "U_P702_MY2021_Tx" SG_ 1085 PwSrcULo_Pc_Mx 1;
BA_ "U_CD542_MY2021_Tx" SG_ 1085 PwSrcULo_Pc_Mx 1;
BA_ "ContentDependant" SG_ 1085 DcdcULo_U_Actl 1;
BA_ "U_CX727_MY2021_Rx" SG_ 1085 DcdcULo_U_Actl 1;
BA_ "U_P702_MY2021_Rx" SG_ 1085 DcdcULo_U_Actl 1;
BA_ "U_CX727_MY2021_Tx" SG_ 1085 DcdcULo_U_Actl 1;
BA_ "U_P702_MY2021_Tx" SG_ 1085 DcdcULo_U_Actl 1;
BA_ "U_CD542_MY2021_Tx" SG_ 1085 DcdcULo_U_Actl 1;
BA_ "ContentDependant" SG_ 1085 DcdcUHi_I_Actl 1;
BA_ "U_CX727_MY2021_Rx" SG_ 1085 DcdcUHi_I_Actl 1;
BA_ "U_CD542_MY2021_Rx" SG_ 1085 DcdcUHi_I_Actl 1;
BA_ "U_U55X_MY2022_Rx" SG_ 1085 DcdcUHi_I_Actl 1;
BA_ "U_CX727_MY2021_Tx" SG_ 1085 DcdcUHi_I_Actl 1;
BA_ "U_P702_MY2021_Tx" SG_ 1085 DcdcUHi_I_Actl 1;
BA_ "U_CD542_MY2021_Tx" SG_ 1085 DcdcUHi_I_Actl 1;
BA_ "U_CX727_MY2021_Rx" SG_ 1085 PwSrcULo_I_Mx 1;
BA_ "U_P702_MY2021_Rx" SG_ 1085 PwSrcULo_I_Mx 1;
BA_ "U_T6_MCA_MY2020_Rx" SG_ 1085 PwSrcULo_I_Mx 1;
BA_ "U_CD542_MY2021_Rx" SG_ 1085 PwSrcULo_I_Mx 1;
BA_ "U_U55X_MY2022_Rx" SG_ 1085 PwSrcULo_I_Mx 1;
BA_ "U_CD764_MY2022_Rx" SG_ 1085 PwSrcULo_I_Mx 1;
BA_ "U_CX727_MY2021_Tx" SG_ 1085 PwSrcULo_I_Mx 1;
BA_ "U_P702_MY2021_Tx" SG_ 1085 PwSrcULo_I_Mx 1;
BA_ "U_CD542_MY2021_Tx" SG_ 1085 PwSrcULo_I_Mx 1;
BA_ "U_CX727_MY2021_Rx" SG_ 1085 PwSrcULo_I_Actl 1;
BA_ "U_P702_MY2021_Rx" SG_ 1085 PwSrcULo_I_Actl 1;
BA_ "U_T6_MCA_MY2020_Rx" SG_ 1085 PwSrcULo_I_Actl 1;
BA_ "U_CD542_MY2021_Rx" SG_ 1085 PwSrcULo_I_Actl 1;
BA_ "U_U55X_MY2022_Rx" SG_ 1085 PwSrcULo_I_Actl 1;
BA_ "U_CD764_MY2022_Rx" SG_ 1085 PwSrcULo_I_Actl 1;
BA_ "U_CX727_MY2021_Tx" SG_ 1085 PwSrcULo_I_Actl 1;
BA_ "U_P702_MY2021_Tx" SG_ 1085 PwSrcULo_I_Actl 1;
BA_ "U_CD542_MY2021_Tx" SG_ 1085 PwSrcULo_I_Actl 1;
BA_ "ContentDependant" SG_ 1085 DcdcUHi_U_Actl 1;
BA_ "U_CX727_MY2021_Rx" SG_ 1085 DcdcUHi_U_Actl 1;
BA_ "U_P702_MY2021_Rx" SG_ 1085 DcdcUHi_U_Actl 1;
BA_ "U_CD542_MY2021_Rx" SG_ 1085 DcdcUHi_U_Actl 1;
BA_ "U_U55X_MY2022_Rx" SG_ 1085 DcdcUHi_U_Actl 1;
BA_ "U_CX727_MY2021_Tx" SG_ 1085 DcdcUHi_U_Actl 1;
BA_ "U_P702_MY2021_Tx" SG_ 1085 DcdcUHi_U_Actl 1;
BA_ "U_CD542_MY2021_Tx" SG_ 1085 DcdcUHi_U_Actl 1;
BA_ "ContentDependant" SG_ 603 WhlDirAvgDrv_D_Actl 1;
BA_ "ContentDependant" SG_ 603 PrplTqMnRgen_B_Actl 1;
BA_ "U_CX727_MY2021_Rx" SG_ 603 PrplWhlTot_Tq_Cmd 1;
BA_ "GenSigStartValueInteger" SG_ 603 EDrvTqMntrRconfg_D_Cmd 7;
BA_ "GenSigStartValue" SG_ 603 EDrvTqMntrRconfg_D_Cmd 7;
BA_ "GenSigStartValueInteger" SG_ 603 BattTracCnnct_D_Rq 2;
BA_ "ContentDependant" SG_ 603 BattTracCnnct_D_Rq 1;
BA_ "GenSigStartValue" SG_ 603 BattTracCnnct_D_Rq 2;
BA_ "U_CX727_MY2021_Rx" SG_ 603 BattTracCnnct_D_Rq 1;
BA_ "U_P702_MY2021_Rx" SG_ 603 BattTracCnnct_D_Rq 1;
BA_ "U_CD542_MY2021_Rx" SG_ 603 BattTracCnnct_D_Rq 1;
BA_ "ECGUsedRxSignal" SG_ 602 HtrnWarnLamp_B_Dsply 1;
BA_ "U_CD542_MY2021_Rx" SG_ 602 HtrnWarnLamp_B_Dsply 1;
BA_ "GenSigStartValue" SG_ 602 BattTracRsrvSoc_Pc_Rq 16382;
BA_ "GenSigStartValueInteger" SG_ 587 BattTracClnt_Te_Actl 164;
BA_ "GenSigStartValue" SG_ 587 BattTracClnt_Te_Actl 254;
BA_ "U_CX727_MY2021_Tx" SG_ 587 BattTracClnt_Te_Actl 1;
BA_ "U_P702_MY2021_Tx" SG_ 587 BattTracClnt_Te_Actl 1;
BA_ "U_CD542_MY2021_Tx" SG_ 587 BattTracClnt_Te_Actl 1;
BA_ "ECGUsedRxSignal" SG_ 587 BattTracWarnLamp_B_Rq 1;
BA_ "U_CD542_MY2021_Rx" SG_ 587 BattTracWarnLamp_B_Rq 1;
BA_ "U_U55X_MY2022_Rx" SG_ 587 BattTracWarnLamp_B_Rq 1;
BA_ "U_CX727_MY2021_Tx" SG_ 587 BattTracWarnLamp_B_Rq 1;
BA_ "U_P702_MY2021_Tx" SG_ 587 BattTracWarnLamp_B_Rq 1;
BA_ "U_CD542_MY2021_Tx" SG_ 587 BattTracWarnLamp_B_Rq 1;
BA_ "ECGUsedRxSignal" SG_ 587 BattTracSrvcRqd_B_Rq 1;
BA_ "U_CD542_MY2021_Rx" SG_ 587 BattTracSrvcRqd_B_Rq 1;
BA_ "U_U55X_MY2022_Rx" SG_ 587 BattTracSrvcRqd_B_Rq 1;
BA_ "U_CX727_MY2021_Tx" SG_ 587 BattTracSrvcRqd_B_Rq 1;
BA_ "U_P702_MY2021_Tx" SG_ 587 BattTracSrvcRqd_B_Rq 1;
BA_ "U_CD542_MY2021_Tx" SG_ 587 BattTracSrvcRqd_B_Rq 1;
BA_ "GenSigStartValueInteger" SG_ 587 BattTracSoc_Pc_MxPrtct 700;
BA_ "GenSigStartValue" SG_ 587 BattTracSoc_Pc_MxPrtct 700;
BA_ "U_CX727_MY2021_Tx" SG_ 587 BattTracSoc_Pc_MxPrtct 1;
BA_ "U_P702_MY2021_Tx" SG_ 587 BattTracSoc_Pc_MxPrtct 1;
BA_ "U_CD542_MY2021_Tx" SG_ 587 BattTracSoc_Pc_MxPrtct 1;
BA_ "GenSigStartValueInteger" SG_ 587 BattTracSoc_Pc_MnPrtct 300;
BA_ "GenSigStartValue" SG_ 587 BattTracSoc_Pc_MnPrtct 30;
BA_ "U_CX727_MY2021_Tx" SG_ 587 BattTracSoc_Pc_MnPrtct 1;
BA_ "U_P702_MY2021_Tx" SG_ 587 BattTracSoc_Pc_MnPrtct 1;
BA_ "U_CD542_MY2021_Tx" SG_ 587 BattTracSoc_Pc_MnPrtct 1;
BA_ "GenSigStartValueInteger" SG_ 587 BattTracSoc_Pc_LimLo 400;
BA_ "GenSigStartValue" SG_ 587 BattTracSoc_Pc_LimLo 400;
BA_ "U_CX727_MY2021_Tx" SG_ 587 BattTracSoc_Pc_LimLo 1;
BA_ "U_P702_MY2021_Tx" SG_ 587 BattTracSoc_Pc_LimLo 1;
BA_ "U_CD542_MY2021_Tx" SG_ 587 BattTracSoc_Pc_LimLo 1;
BA_ "GenSigStartValueInteger" SG_ 587 BattTracSoc_Pc_LimHi 600;
BA_ "GenSigStartValue" SG_ 587 BattTracSoc_Pc_LimHi 600;
BA_ "U_CX727_MY2021_Tx" SG_ 587 BattTracSoc_Pc_LimHi 1;
BA_ "U_P702_MY2021_Tx" SG_ 587 BattTracSoc_Pc_LimHi 1;
BA_ "U_CD542_MY2021_Tx" SG_ 587 BattTracSoc_Pc_LimHi 1;
BA_ "GenSigStartValue" SG_ 1040 VehSimSnd_Pc_Rq 511;
BA_ "GenSigStartValueInteger" SG_ 1040 BattTrac_I2_EstVsc 15000;
BA_ "GenSigStartValue" SG_ 1040 BattTrac_I2_EstVsc 262142;
BA_ "U_CX727_MY2021_Rx" SG_ 1040 ElCmprEnbl_B_Rq 1;
BA_ "U_P702_MY2021_Rx" SG_ 1040 ElCmprEnbl_B_Rq 1;
BA_ "U_CD542_MY2021_Rx" SG_ 1040 ElCmprEnbl_B_Rq 1;
BA_ "U_CX727_MY2021_Rx" SG_ 1040 ElCmpr_N_Rq 1;
BA_ "U_P702_MY2021_Rx" SG_ 1040 ElCmpr_N_Rq 1;
BA_ "U_CD542_MY2021_Rx" SG_ 1040 ElCmpr_N_Rq 1;
BA_ "GenSigStartValue" SG_ 1088 TrlrRng_L_Dsply 8190;
BA_ "WakeupSignal" SG_ 1088 HvacPrecondMode2_D_Rq 1;
BA_ "ContentDependant" SG_ 1088 HvacPrecondMode2_D_Rq 1;
BA_ "WakeupSignal" SG_ 1088 HvacPrecondBlwr2_D_Rq 1;
BA_ "ContentDependant" SG_ 1088 HvacPrecondBlwr2_D_Rq 1;
BA_ "GenSigStartValueInteger" SG_ 1088 HvacPrecond_Te_Rq 2;
BA_ "GenSigStartValue" SG_ 1088 HvacPrecond_Te_Rq 2;
BA_ "GenSigStartValue" SG_ 1088 BattDcChrgRms_I_Lim 32766;
BA_ "U_CX727_MY2021_Rx" SG_ 1088 BattChrgInhbt_D_Rq 1;
BA_ "U_CD542_MY2021_Rx" SG_ 1088 BattChrgInhbt_D_Rq 1;
BA_ "WakeupSignal" SG_ 1088 ChrgStat_D2_Dsply 1;
BA_ "U_CX727_MY2021_Rx" SG_ 1072 ePRNDL_MODE_UB 1;
BA_ "U_P702_MY2021_Rx" SG_ 1072 ePRNDL_MODE_UB 1;
BA_ "U_T6_MCA_MY2020_Rx" SG_ 1072 ePRNDL_MODE_UB 1;
BA_ "U_CD542_MY2021_Rx" SG_ 1072 ePRNDL_MODE_UB 1;
BA_ "U_U55X_MY2022_Rx" SG_ 1072 ePRNDL_MODE_UB 1;
BA_ "U_CD764_MY2022_Rx" SG_ 1072 ePRNDL_MODE_UB 1;
BA_ "GenSigSendType" SG_ 1072 NtrlTowMdeEnbl_B_RqDrv 3;
BA_ "U_CX727_MY2021_Rx" SG_ 1072 Remote_Start_QuietMode_UB 1;
BA_ "U_P702_MY2021_Rx" SG_ 1072 Remote_Start_QuietMode_UB 1;
BA_ "U_T6_MCA_MY2020_Rx" SG_ 1072 Remote_Start_QuietMode_UB 1;
BA_ "U_CD542_MY2021_Rx" SG_ 1072 Remote_Start_QuietMode_UB 1;
BA_ "U_U55X_MY2022_Rx" SG_ 1072 Remote_Start_QuietMode_UB 1;
BA_ "U_CD764_MY2022_Rx" SG_ 1072 Remote_Start_QuietMode_UB 1;
BA_ "GenSigSendType" SG_ 1072 Remote_Start_QuietMode 3;
BA_ "U_CX727_MY2021_Rx" SG_ 1072 Remote_Start_QuietMode 1;
BA_ "U_P702_MY2021_Rx" SG_ 1072 Remote_Start_QuietMode 1;
BA_ "U_T6_MCA_MY2020_Rx" SG_ 1072 Remote_Start_QuietMode 1;
BA_ "U_CD542_MY2021_Rx" SG_ 1072 Remote_Start_QuietMode 1;
BA_ "U_U55X_MY2022_Rx" SG_ 1072 Remote_Start_QuietMode 1;
BA_ "U_CD764_MY2022_Rx" SG_ 1072 Remote_Start_QuietMode 1;
BA_ "U_CX727_MY2021_Rx" SG_ 1072 ParkDetect_Stat_UB 1;
BA_ "U_P702_MY2021_Rx" SG_ 1072 ParkDetect_Stat_UB 1;
BA_ "U_T6_MCA_MY2020_Rx" SG_ 1072 ParkDetect_Stat_UB 1;
BA_ "U_CD542_MY2021_Rx" SG_ 1072 ParkDetect_Stat_UB 1;
BA_ "U_U55X_MY2022_Rx" SG_ 1072 ParkDetect_Stat_UB 1;
BA_ "U_CD764_MY2022_Rx" SG_ 1072 ParkDetect_Stat_UB 1;
BA_ "GenSigSendType" SG_ 1072 ParkDetect_Stat 3;
BA_ "U_CX727_MY2021_Rx" SG_ 1072 ParkDetect_Stat 1;
BA_ "U_P702_MY2021_Rx" SG_ 1072 ParkDetect_Stat 1;
BA_ "U_T6_MCA_MY2020_Rx" SG_ 1072 ParkDetect_Stat 1;
BA_ "U_CD542_MY2021_Rx" SG_ 1072 ParkDetect_Stat 1;
BA_ "U_U55X_MY2022_Rx" SG_ 1072 ParkDetect_Stat 1;
BA_ "U_CD764_MY2022_Rx" SG_ 1072 ParkDetect_Stat 1;
BA_ "U_CX727_MY2021_Rx" SG_ 1072 TrlrLampCnnct_B_Actl_UB 1;
BA_ "U_P702_MY2021_Rx" SG_ 1072 TrlrLampCnnct_B_Actl_UB 1;
BA_ "U_T6_MCA_MY2020_Rx" SG_ 1072 TrlrLampCnnct_B_Actl_UB 1;
BA_ "U_CD542_MY2021_Rx" SG_ 1072 TrlrLampCnnct_B_Actl_UB 1;
BA_ "U_U55X_MY2022_Rx" SG_ 1072 TrlrLampCnnct_B_Actl_UB 1;
BA_ "U_CD764_MY2022_Rx" SG_ 1072 TrlrLampCnnct_B_Actl_UB 1;
BA_ "U_CX727_MY2021_Rx" SG_ 1072 StopLamp_B_RqTrlrBrk_UB 1;
BA_ "U_P702_MY2021_Rx" SG_ 1072 StopLamp_B_RqTrlrBrk_UB 1;
BA_ "U_T6_MCA_MY2020_Rx" SG_ 1072 StopLamp_B_RqTrlrBrk_UB 1;
BA_ "U_CD542_MY2021_Rx" SG_ 1072 StopLamp_B_RqTrlrBrk_UB 1;
BA_ "U_U55X_MY2022_Rx" SG_ 1072 StopLamp_B_RqTrlrBrk_UB 1;
BA_ "U_CD764_MY2022_Rx" SG_ 1072 StopLamp_B_RqTrlrBrk_UB 1;
BA_ "ContentDependant" SG_ 1072 StopLamp_B_RqTrlrBrk 1;
BA_ "GenSigSendType" SG_ 1072 StopLamp_B_RqTrlrBrk 3;
BA_ "U_CX727_MY2021_Rx" SG_ 1072 StopLamp_B_RqTrlrBrk 1;
BA_ "U_P702_MY2021_Rx" SG_ 1072 StopLamp_B_RqTrlrBrk 1;
BA_ "U_T6_MCA_MY2020_Rx" SG_ 1072 StopLamp_B_RqTrlrBrk 1;
BA_ "U_CD542_MY2021_Rx" SG_ 1072 StopLamp_B_RqTrlrBrk 1;
BA_ "U_U55X_MY2022_Rx" SG_ 1072 StopLamp_B_RqTrlrBrk 1;
BA_ "U_CD764_MY2022_Rx" SG_ 1072 StopLamp_B_RqTrlrBrk 1;
BA_ "U_CX727_MY2021_Rx" SG_ 1072 OdometerMasterValue_UB 1;
BA_ "U_P702_MY2021_Rx" SG_ 1072 OdometerMasterValue_UB 1;
BA_ "U_T6_MCA_MY2020_Rx" SG_ 1072 OdometerMasterValue_UB 1;
BA_ "U_CD542_MY2021_Rx" SG_ 1072 OdometerMasterValue_UB 1;
BA_ "U_U55X_MY2022_Rx" SG_ 1072 OdometerMasterValue_UB 1;
BA_ "U_CD764_MY2022_Rx" SG_ 1072 OdometerMasterValue_UB 1;
BA_ "GenSigSendType" SG_ 1072 OdometerMasterValue 3;
BA_ "U_CX727_MY2021_Rx" SG_ 1072 OdometerMasterValue 1;
BA_ "U_P702_MY2021_Rx" SG_ 1072 OdometerMasterValue 1;
BA_ "U_T6_MCA_MY2020_Rx" SG_ 1072 OdometerMasterValue 1;
BA_ "U_CD542_MY2021_Rx" SG_ 1072 OdometerMasterValue 1;
BA_ "U_U55X_MY2022_Rx" SG_ 1072 OdometerMasterValue 1;
BA_ "U_CD764_MY2022_Rx" SG_ 1072 OdometerMasterValue 1;
BA_ "GenSigSendType" SG_ 1072 FrostWarn_D_Stat 3;
BA_ "U_CX727_MY2021_Rx" SG_ 1072 ReducedGuard_D_Rq_UB 1;
BA_ "U_P702_MY2021_Rx" SG_ 1072 ReducedGuard_D_Rq_UB 1;
BA_ "U_T6_MCA_MY2020_Rx" SG_ 1072 ReducedGuard_D_Rq_UB 1;
BA_ "U_CD542_MY2021_Rx" SG_ 1072 ReducedGuard_D_Rq_UB 1;
BA_ "U_U55X_MY2022_Rx" SG_ 1072 ReducedGuard_D_Rq_UB 1;
BA_ "U_CD764_MY2022_Rx" SG_ 1072 ReducedGuard_D_Rq_UB 1;
BA_ "GenSigSendType" SG_ 1072 ReducedGuard_D_Rq 3;
BA_ "U_CX727_MY2021_Rx" SG_ 1072 ReducedGuard_D_Rq 1;
BA_ "U_P702_MY2021_Rx" SG_ 1072 ReducedGuard_D_Rq 1;
BA_ "U_T6_MCA_MY2020_Rx" SG_ 1072 ReducedGuard_D_Rq 1;
BA_ "U_CD542_MY2021_Rx" SG_ 1072 ReducedGuard_D_Rq 1;
BA_ "U_U55X_MY2022_Rx" SG_ 1072 ReducedGuard_D_Rq 1;
BA_ "U_CD764_MY2022_Rx" SG_ 1072 ReducedGuard_D_Rq 1;
BA_ "WakeupSignal" SG_ 1072 ePRNDL_MODE 1;
BA_ "GenSigSendType" SG_ 1072 ePRNDL_MODE 3;
BA_ "U_CX727_MY2021_Rx" SG_ 1072 ePRNDL_MODE 1;
BA_ "U_P702_MY2021_Rx" SG_ 1072 ePRNDL_MODE 1;
BA_ "U_T6_MCA_MY2020_Rx" SG_ 1072 ePRNDL_MODE 1;
BA_ "U_CD542_MY2021_Rx" SG_ 1072 ePRNDL_MODE 1;
BA_ "U_U55X_MY2022_Rx" SG_ 1072 ePRNDL_MODE 1;
BA_ "U_CD764_MY2022_Rx" SG_ 1072 ePRNDL_MODE 1;
BA_ "GenSigSendType" SG_ 1072 EngOilLife_B_RqReset 3;
BA_ "U_U55X_MY2022_Rx" SG_ 1072 Outside_Air_Temp_Stat_UB 1;
BA_ "GenSigStartValueInteger" SG_ 1072 Outside_Air_Temp_Stat 254;
BA_ "GenSigStartValue" SG_ 1072 Outside_Air_Temp_Stat 254;
BA_ "GenSigSendType" SG_ 1072 Outside_Air_Temp_Stat 3;
BA_ "U_U55X_MY2022_Rx" SG_ 1072 Outside_Air_Temp_Stat 1;
BA_ "U_CX727_MY2021_Rx" SG_ 1072 KeyTypeChngMykey_D_Rq_UB 1;
BA_ "U_P702_MY2021_Rx" SG_ 1072 KeyTypeChngMykey_D_Rq_UB 1;
BA_ "U_T6_MCA_MY2020_Rx" SG_ 1072 KeyTypeChngMykey_D_Rq_UB 1;
BA_ "U_CD542_MY2021_Rx" SG_ 1072 KeyTypeChngMykey_D_Rq_UB 1;
BA_ "U_U55X_MY2022_Rx" SG_ 1072 KeyTypeChngMykey_D_Rq_UB 1;
BA_ "U_CD764_MY2022_Rx" SG_ 1072 KeyTypeChngMykey_D_Rq_UB 1;
BA_ "GenSigSendType" SG_ 1072 KeyTypeChngMykey_D_Rq 3;
BA_ "U_CX727_MY2021_Rx" SG_ 1072 KeyTypeChngMykey_D_Rq 1;
BA_ "U_P702_MY2021_Rx" SG_ 1072 KeyTypeChngMykey_D_Rq 1;
BA_ "U_T6_MCA_MY2020_Rx" SG_ 1072 KeyTypeChngMykey_D_Rq 1;
BA_ "U_CD542_MY2021_Rx" SG_ 1072 KeyTypeChngMykey_D_Rq 1;
BA_ "U_U55X_MY2022_Rx" SG_ 1072 KeyTypeChngMykey_D_Rq 1;
BA_ "U_CD764_MY2022_Rx" SG_ 1072 KeyTypeChngMykey_D_Rq 1;
BA_ "GenSigSendType" SG_ 1072 TrlrLampCnnct_B_Actl 3;
BA_ "U_CX727_MY2021_Rx" SG_ 1072 TrlrLampCnnct_B_Actl 1;
BA_ "U_P702_MY2021_Rx" SG_ 1072 TrlrLampCnnct_B_Actl 1;
BA_ "U_T6_MCA_MY2020_Rx" SG_ 1072 TrlrLampCnnct_B_Actl 1;
BA_ "U_CD542_MY2021_Rx" SG_ 1072 TrlrLampCnnct_B_Actl 1;
BA_ "U_U55X_MY2022_Rx" SG_ 1072 TrlrLampCnnct_B_Actl 1;
BA_ "U_CD764_MY2022_Rx" SG_ 1072 TrlrLampCnnct_B_Actl 1;
BA_ "GenSigStartValueInteger" SG_ 1438 GWM_GWOnBoardTester 255;
BA_ "ContentDependant" SG_ 1438 GWM_GWOnBoardTester 1;
BA_ "GenSigStartValue" SG_ 1438 GWM_GWOnBoardTester 255;
BA_ "U_CX727_MY2021_Rx" SG_ 1438 GWM_GWOnBoardTester 1;
BA_ "U_P702_MY2021_Rx" SG_ 1438 GWM_GWOnBoardTester 1;
BA_ "U_T6_MCA_MY2020_Rx" SG_ 1438 GWM_GWOnBoardTester 1;
BA_ "U_CD542_MY2021_Rx" SG_ 1438 GWM_GWOnBoardTester 1;
BA_ "U_U55X_MY2022_Rx" SG_ 1438 GWM_GWOnBoardTester 1;
BA_ "U_CD764_MY2022_Rx" SG_ 1438 GWM_GWOnBoardTester 1;
BA_ "U_T6_MCA_MY2020_Tx" SG_ 1438 GWM_GWOnBoardTester 1;
BA_ "ECGUsedTxSignal" SG_ 1438 GWM_GWOnBoardTester 1;
BA_ "U_CD542_MY2021_Tx" SG_ 1438 GWM_GWOnBoardTester 1;
BA_ "U_U55X_MY2022_Tx" SG_ 1438 GWM_GWOnBoardTester 1;
BA_ "U_CD764_MY2022_Tx" SG_ 1438 GWM_GWOnBoardTester 1;
BA_ "GenSigStartValueInteger" SG_ 1438 GWM_GWNMProxy 255;
BA_ "ContentDependant" SG_ 1438 GWM_GWNMProxy 1;
BA_ "GenSigStartValue" SG_ 1438 GWM_GWNMProxy 255;
BA_ "U_CX727_MY2021_Rx" SG_ 1438 GWM_GWNMProxy 1;
BA_ "U_P702_MY2021_Rx" SG_ 1438 GWM_GWNMProxy 1;
BA_ "U_T6_MCA_MY2020_Rx" SG_ 1438 GWM_GWNMProxy 1;
BA_ "U_CD542_MY2021_Rx" SG_ 1438 GWM_GWNMProxy 1;
BA_ "U_U55X_MY2022_Rx" SG_ 1438 GWM_GWNMProxy 1;
BA_ "U_CD764_MY2022_Rx" SG_ 1438 GWM_GWNMProxy 1;
BA_ "U_T6_MCA_MY2020_Tx" SG_ 1438 GWM_GWNMProxy 1;
BA_ "ECGUsedTxSignal" SG_ 1438 GWM_GWNMProxy 1;
BA_ "U_CD542_MY2021_Tx" SG_ 1438 GWM_GWNMProxy 1;
BA_ "U_U55X_MY2022_Tx" SG_ 1438 GWM_GWNMProxy 1;
BA_ "U_CD764_MY2022_Tx" SG_ 1438 GWM_GWNMProxy 1;
BA_ "GenSigStartValueInteger" SG_ 1438 GWM_AutoSarNMReserved4 255;
BA_ "ContentDependant" SG_ 1438 GWM_AutoSarNMReserved4 1;
BA_ "GenSigStartValue" SG_ 1438 GWM_AutoSarNMReserved4 255;
BA_ "U_CX727_MY2021_Rx" SG_ 1438 GWM_AutoSarNMReserved4 1;
BA_ "U_P702_MY2021_Rx" SG_ 1438 GWM_AutoSarNMReserved4 1;
BA_ "U_T6_MCA_MY2020_Rx" SG_ 1438 GWM_AutoSarNMReserved4 1;
BA_ "U_CD542_MY2021_Rx" SG_ 1438 GWM_AutoSarNMReserved4 1;
BA_ "U_U55X_MY2022_Rx" SG_ 1438 GWM_AutoSarNMReserved4 1;
BA_ "U_CD764_MY2022_Rx" SG_ 1438 GWM_AutoSarNMReserved4 1;
BA_ "U_T6_MCA_MY2020_Tx" SG_ 1438 GWM_AutoSarNMReserved4 1;
BA_ "ECGUsedTxSignal" SG_ 1438 GWM_AutoSarNMReserved4 1;
BA_ "U_CD542_MY2021_Tx" SG_ 1438 GWM_AutoSarNMReserved4 1;
BA_ "U_U55X_MY2022_Tx" SG_ 1438 GWM_AutoSarNMReserved4 1;
BA_ "U_CD764_MY2022_Tx" SG_ 1438 GWM_AutoSarNMReserved4 1;
BA_ "GenSigStartValueInteger" SG_ 1438 GWM_AutoSarNMReserved3 255;
BA_ "ContentDependant" SG_ 1438 GWM_AutoSarNMReserved3 1;
BA_ "GenSigStartValue" SG_ 1438 GWM_AutoSarNMReserved3 255;
BA_ "U_CX727_MY2021_Rx" SG_ 1438 GWM_AutoSarNMReserved3 1;
BA_ "U_P702_MY2021_Rx" SG_ 1438 GWM_AutoSarNMReserved3 1;
BA_ "U_T6_MCA_MY2020_Rx" SG_ 1438 GWM_AutoSarNMReserved3 1;
BA_ "U_CD542_MY2021_Rx" SG_ 1438 GWM_AutoSarNMReserved3 1;
BA_ "U_U55X_MY2022_Rx" SG_ 1438 GWM_AutoSarNMReserved3 1;
BA_ "U_CD764_MY2022_Rx" SG_ 1438 GWM_AutoSarNMReserved3 1;
BA_ "U_T6_MCA_MY2020_Tx" SG_ 1438 GWM_AutoSarNMReserved3 1;
BA_ "ECGUsedTxSignal" SG_ 1438 GWM_AutoSarNMReserved3 1;
BA_ "U_CD542_MY2021_Tx" SG_ 1438 GWM_AutoSarNMReserved3 1;
BA_ "U_U55X_MY2022_Tx" SG_ 1438 GWM_AutoSarNMReserved3 1;
BA_ "U_CD764_MY2022_Tx" SG_ 1438 GWM_AutoSarNMReserved3 1;
BA_ "GenSigStartValueInteger" SG_ 1438 GWM_AutoSarNMReserved2 255;
BA_ "ContentDependant" SG_ 1438 GWM_AutoSarNMReserved2 1;
BA_ "GenSigStartValue" SG_ 1438 GWM_AutoSarNMReserved2 255;
BA_ "U_CX727_MY2021_Rx" SG_ 1438 GWM_AutoSarNMReserved2 1;
BA_ "U_P702_MY2021_Rx" SG_ 1438 GWM_AutoSarNMReserved2 1;
BA_ "U_T6_MCA_MY2020_Rx" SG_ 1438 GWM_AutoSarNMReserved2 1;
BA_ "U_CD542_MY2021_Rx" SG_ 1438 GWM_AutoSarNMReserved2 1;
BA_ "U_U55X_MY2022_Rx" SG_ 1438 GWM_AutoSarNMReserved2 1;
BA_ "U_CD764_MY2022_Rx" SG_ 1438 GWM_AutoSarNMReserved2 1;
BA_ "U_T6_MCA_MY2020_Tx" SG_ 1438 GWM_AutoSarNMReserved2 1;
BA_ "ECGUsedTxSignal" SG_ 1438 GWM_AutoSarNMReserved2 1;
BA_ "U_CD542_MY2021_Tx" SG_ 1438 GWM_AutoSarNMReserved2 1;
BA_ "U_U55X_MY2022_Tx" SG_ 1438 GWM_AutoSarNMReserved2 1;
BA_ "U_CD764_MY2022_Tx" SG_ 1438 GWM_AutoSarNMReserved2 1;
BA_ "GenSigStartValueInteger" SG_ 1438 GWM_AutoSarNMReserved1 255;
BA_ "ContentDependant" SG_ 1438 GWM_AutoSarNMReserved1 1;
BA_ "GenSigStartValue" SG_ 1438 GWM_AutoSarNMReserved1 255;
BA_ "U_CX727_MY2021_Rx" SG_ 1438 GWM_AutoSarNMReserved1 1;
BA_ "U_P702_MY2021_Rx" SG_ 1438 GWM_AutoSarNMReserved1 1;
BA_ "U_T6_MCA_MY2020_Rx" SG_ 1438 GWM_AutoSarNMReserved1 1;
BA_ "U_CD542_MY2021_Rx" SG_ 1438 GWM_AutoSarNMReserved1 1;
BA_ "U_U55X_MY2022_Rx" SG_ 1438 GWM_AutoSarNMReserved1 1;
BA_ "U_CD764_MY2022_Rx" SG_ 1438 GWM_AutoSarNMReserved1 1;
BA_ "U_T6_MCA_MY2020_Tx" SG_ 1438 GWM_AutoSarNMReserved1 1;
BA_ "ECGUsedTxSignal" SG_ 1438 GWM_AutoSarNMReserved1 1;
BA_ "U_CD542_MY2021_Tx" SG_ 1438 GWM_AutoSarNMReserved1 1;
BA_ "U_U55X_MY2022_Tx" SG_ 1438 GWM_AutoSarNMReserved1 1;
BA_ "U_CD764_MY2022_Tx" SG_ 1438 GWM_AutoSarNMReserved1 1;
BA_ "GenSigStartValueInteger" SG_ 1438 GWM_AutoSarNMNodeId 158;
BA_ "ContentDependant" SG_ 1438 GWM_AutoSarNMNodeId 1;
BA_ "GenSigStartValue" SG_ 1438 GWM_AutoSarNMNodeId 158;
BA_ "U_CX727_MY2021_Rx" SG_ 1438 GWM_AutoSarNMNodeId 1;
BA_ "U_P702_MY2021_Rx" SG_ 1438 GWM_AutoSarNMNodeId 1;
BA_ "U_T6_MCA_MY2020_Rx" SG_ 1438 GWM_AutoSarNMNodeId 1;
BA_ "U_CD542_MY2021_Rx" SG_ 1438 GWM_AutoSarNMNodeId 1;
BA_ "U_U55X_MY2022_Rx" SG_ 1438 GWM_AutoSarNMNodeId 1;
BA_ "U_CD764_MY2022_Rx" SG_ 1438 GWM_AutoSarNMNodeId 1;
BA_ "U_T6_MCA_MY2020_Tx" SG_ 1438 GWM_AutoSarNMNodeId 1;
BA_ "ECGUsedTxSignal" SG_ 1438 GWM_AutoSarNMNodeId 1;
BA_ "U_CD542_MY2021_Tx" SG_ 1438 GWM_AutoSarNMNodeId 1;
BA_ "U_U55X_MY2022_Tx" SG_ 1438 GWM_AutoSarNMNodeId 1;
BA_ "U_CD764_MY2022_Tx" SG_ 1438 GWM_AutoSarNMNodeId 1;
BA_ "ContentDependant" SG_ 1438 GWM_AutoSarNMControl 1;
BA_ "U_CX727_MY2021_Rx" SG_ 1438 GWM_AutoSarNMControl 1;
BA_ "U_P702_MY2021_Rx" SG_ 1438 GWM_AutoSarNMControl 1;
BA_ "U_T6_MCA_MY2020_Rx" SG_ 1438 GWM_AutoSarNMControl 1;
BA_ "U_CD542_MY2021_Rx" SG_ 1438 GWM_AutoSarNMControl 1;
BA_ "U_U55X_MY2022_Rx" SG_ 1438 GWM_AutoSarNMControl 1;
BA_ "U_CD764_MY2022_Rx" SG_ 1438 GWM_AutoSarNMControl 1;
BA_ "U_T6_MCA_MY2020_Tx" SG_ 1438 GWM_AutoSarNMControl 1;
BA_ "ECGUsedTxSignal" SG_ 1438 GWM_AutoSarNMControl 1;
BA_ "U_CD542_MY2021_Tx" SG_ 1438 GWM_AutoSarNMControl 1;
BA_ "U_U55X_MY2022_Tx" SG_ 1438 GWM_AutoSarNMControl 1;
BA_ "U_CD764_MY2022_Tx" SG_ 1438 GWM_AutoSarNMControl 1;
BA_ "GenSigStartValueInteger" SG_ 588 BattTracSoc_Pc_Dsply 254;
BA_ "GenSigStartValue" SG_ 588 BattTracSoc_Pc_Dsply 254;
BA_ "U_CX727_MY2021_Rx" SG_ 588 BattTracSoc_Pc_Dsply 1;
BA_ "U_CD542_MY2021_Rx" SG_ 588 BattTracSoc_Pc_Dsply 1;
BA_ "ECGUsedRxSignal" SG_ 588 BattTracSoc_Pc_Dsply 1;
BA_ "U_U55X_MY2022_Rx" SG_ 588 BattTracSoc_Pc_Dsply 1;
BA_ "U_CX727_MY2021_Tx" SG_ 588 BattTracSoc_Pc_Dsply 1;
BA_ "U_CD542_MY2021_Tx" SG_ 588 BattTracSoc_Pc_Dsply 1;
BA_ "U_CX727_MY2021_Rx" SG_ 588 BattChrgRdyStat_D_Actl 1;
BA_ "U_CD542_MY2021_Rx" SG_ 588 BattChrgRdyStat_D_Actl 1;
BA_ "U_CX727_MY2021_Tx" SG_ 588 BattChrgRdyStat_D_Actl 1;
BA_ "U_CD542_MY2021_Tx" SG_ 588 BattChrgRdyStat_D_Actl 1;
BA_ "GenSigStartValueInteger" SG_ 588 BattTracSoc2_Pc_Actl 16382;
BA_ "GenSigStartValue" SG_ 588 BattTracSoc2_Pc_Actl 16382;
BA_ "ECGUsedRxSignal" SG_ 588 BattTracSoc2_Pc_Actl 1;
BA_ "U_CD542_MY2021_Rx" SG_ 588 BattTracSoc2_Pc_Actl 1;
BA_ "U_U55X_MY2022_Rx" SG_ 588 BattTracSoc2_Pc_Actl 1;
BA_ "U_CX727_MY2021_Tx" SG_ 588 BattTracSoc2_Pc_Actl 1;
BA_ "U_P702_MY2021_Tx" SG_ 588 BattTracSoc2_Pc_Actl 1;
BA_ "U_CD542_MY2021_Tx" SG_ 588 BattTracSoc2_Pc_Actl 1;
BA_ "GenSigStartValueInteger" SG_ 588 BattTrac_Te_Actl 150;
BA_ "GenSigStartValue" SG_ 588 BattTrac_Te_Actl 150;
BA_ "ECGUsedRxSignal" SG_ 588 BattTrac_Te_Actl 1;
BA_ "U_CD542_MY2021_Rx" SG_ 588 BattTrac_Te_Actl 1;
BA_ "U_U55X_MY2022_Rx" SG_ 588 BattTrac_Te_Actl 1;
BA_ "U_CX727_MY2021_Tx" SG_ 588 BattTrac_Te_Actl 1;
BA_ "U_P702_MY2021_Tx" SG_ 588 BattTrac_Te_Actl 1;
BA_ "U_CD542_MY2021_Tx" SG_ 588 BattTrac_Te_Actl 1;
BA_ "GenSigStartValueInteger" SG_ 122 BattTrac_U_LimLo 88;
BA_ "GenSigStartValue" SG_ 122 BattTrac_U_LimLo 88;
BA_ "U_CX727_MY2021_Rx" SG_ 122 BattTrac_U_LimLo 1;
BA_ "U_CX727_MY2021_Tx" SG_ 122 BattTrac_U_LimLo 1;
BA_ "U_P702_MY2021_Tx" SG_ 122 BattTrac_U_LimLo 1;
BA_ "U_CD542_MY2021_Tx" SG_ 122 BattTrac_U_LimLo 1;
BA_ "GenSigStartValueInteger" SG_ 122 BattTrac_U_LimHi 163;
BA_ "GenSigStartValue" SG_ 122 BattTrac_U_LimHi 163;
BA_ "U_CX727_MY2021_Rx" SG_ 122 BattTrac_U_LimHi 1;
BA_ "U_CX727_MY2021_Tx" SG_ 122 BattTrac_U_LimHi 1;
BA_ "U_P702_MY2021_Tx" SG_ 122 BattTrac_U_LimHi 1;
BA_ "U_CD542_MY2021_Tx" SG_ 122 BattTrac_U_LimHi 1;
BA_ "U_CX727_MY2021_Tx" SG_ 122 VehStrtInhbt_B_RqBatt 1;
BA_ "U_P702_MY2021_Tx" SG_ 122 VehStrtInhbt_B_RqBatt 1;
BA_ "U_CD542_MY2021_Tx" SG_ 122 VehStrtInhbt_B_RqBatt 1;
BA_ "U_CX727_MY2021_Rx" SG_ 122 BattTracOffFst_D_Actl 1;
BA_ "U_P702_MY2021_Rx" SG_ 122 BattTracOffFst_D_Actl 1;
BA_ "U_CD542_MY2021_Rx" SG_ 122 BattTracOffFst_D_Actl 1;
BA_ "U_CX727_MY2021_Tx" SG_ 122 BattTracOffFst_D_Actl 1;
BA_ "U_P702_MY2021_Tx" SG_ 122 BattTracOffFst_D_Actl 1;
BA_ "U_CD542_MY2021_Tx" SG_ 122 BattTracOffFst_D_Actl 1;
BA_ "U_CX727_MY2021_Rx" SG_ 122 BattTracOff_B_Actl 1;
BA_ "U_CD542_MY2021_Rx" SG_ 122 BattTracOff_B_Actl 1;
BA_ "ECGUsedRxSignal" SG_ 122 BattTracOff_B_Actl 1;
BA_ "U_U55X_MY2022_Rx" SG_ 122 BattTracOff_B_Actl 1;
BA_ "U_CX727_MY2021_Tx" SG_ 122 BattTracOff_B_Actl 1;
BA_ "U_P702_MY2021_Tx" SG_ 122 BattTracOff_B_Actl 1;
BA_ "U_CD542_MY2021_Tx" SG_ 122 BattTracOff_B_Actl 1;
BA_ "ECGUsedRxSignal" SG_ 122 BattTracMil_D_Rq 1;
BA_ "U_CD542_MY2021_Rx" SG_ 122 BattTracMil_D_Rq 1;
BA_ "U_U55X_MY2022_Rx" SG_ 122 BattTracMil_D_Rq 1;
BA_ "U_CX727_MY2021_Tx" SG_ 122 BattTracMil_D_Rq 1;
BA_ "U_P702_MY2021_Tx" SG_ 122 BattTracMil_D_Rq 1;
BA_ "U_CD542_MY2021_Tx" SG_ 122 BattTracMil_D_Rq 1;
BA_ "GenSigStartValueInteger" SG_ 122 BattTrac_U_Actl 1022;
BA_ "GenSigStartValue" SG_ 122 BattTrac_U_Actl 1022;
BA_ "U_CX727_MY2021_Rx" SG_ 122 BattTrac_U_Actl 1;
BA_ "U_P702_MY2021_Rx" SG_ 122 BattTrac_U_Actl 1;
BA_ "U_CD542_MY2021_Rx" SG_ 122 BattTrac_U_Actl 1;
BA_ "ECGUsedRxSignal" SG_ 122 BattTrac_U_Actl 1;
BA_ "U_U55X_MY2022_Rx" SG_ 122 BattTrac_U_Actl 1;
BA_ "U_CX727_MY2021_Tx" SG_ 122 BattTrac_U_Actl 1;
BA_ "U_P702_MY2021_Tx" SG_ 122 BattTrac_U_Actl 1;
BA_ "U_CD542_MY2021_Tx" SG_ 122 BattTrac_U_Actl 1;
BA_ "GenSigStartValueInteger" SG_ 122 BattTrac_I_Actl 15000;
BA_ "U_CX727_MY2021_Rx" SG_ 122 BattTrac_I_Actl 1;
BA_ "U_CD542_MY2021_Rx" SG_ 122 BattTrac_I_Actl 1;
BA_ "ECGUsedRxSignal" SG_ 122 BattTrac_I_Actl 1;
BA_ "U_U55X_MY2022_Rx" SG_ 122 BattTrac_I_Actl 1;
BA_ "U_CX727_MY2021_Tx" SG_ 122 BattTrac_I_Actl 1;
BA_ "U_P702_MY2021_Tx" SG_ 122 BattTrac_I_Actl 1;
BA_ "U_CD542_MY2021_Tx" SG_ 122 BattTrac_I_Actl 1;
BA_ "GenSigSendType" SG_ 1814 TesterPhysicalReqGWM_H1 3;
BA_ "U_T6_MCA_MY2020_Rx" SG_ 1814 TesterPhysicalReqGWM_H1 1;
BA_ "ECGUsedRxSignal" SG_ 1814 TesterPhysicalReqGWM_H1 1;
BA_ "U_CD542_MY2021_Rx" SG_ 1814 TesterPhysicalReqGWM_H1 1;
BA_ "U_U55X_MY2022_Rx" SG_ 1814 TesterPhysicalReqGWM_H1 1;
BA_ "U_CD764_MY2022_Rx" SG_ 1814 TesterPhysicalReqGWM_H1 1;
BA_ "GenSigSendType" SG_ 1822 TesterPhysicalResGWM_H1 3;
BA_ "U_T6_MCA_MY2020_Tx" SG_ 1822 TesterPhysicalResGWM_H1 1;
BA_ "ECGUsedTxSignal" SG_ 1822 TesterPhysicalResGWM_H1 1;
BA_ "U_CD542_MY2021_Tx" SG_ 1822 TesterPhysicalResGWM_H1 1;
BA_ "U_U55X_MY2022_Tx" SG_ 1822 TesterPhysicalResGWM_H1 1;
BA_ "U_CD764_MY2022_Tx" SG_ 1822 TesterPhysicalResGWM_H1 1;
BA_ "U_CX727_MY2021_Tx" SG_ 578 PtLatchActv_B_RqBcm 1;
BA_ "U_P702_MY2021_Tx" SG_ 578 PtLatchActv_B_RqBcm 1;
BA_ "U_T6_MCA_MY2020_Tx" SG_ 578 PtLatchActv_B_RqBcm 1;
BA_ "U_CD542_MY2021_Tx" SG_ 578 PtLatchActv_B_RqBcm 1;
BA_ "U_U55X_MY2022_Tx" SG_ 578 PtLatchActv_B_RqBcm 1;
BA_ "U_CD764_MY2022_Tx" SG_ 578 PtLatchActv_B_RqBcm 1;
BA_ "U_CX727_MY2021_Rx" SG_ 578 immoSecureIdleMode 1;
BA_ "U_CX727_MY2021_Tx" SG_ 578 immoSecureIdleMode 1;
BA_ "U_P702_MY2021_Tx" SG_ 578 immoSecureIdleMode 1;
BA_ "U_T6_MCA_MY2020_Tx" SG_ 578 immoSecureIdleMode 1;
BA_ "U_CD542_MY2021_Tx" SG_ 578 immoSecureIdleMode 1;
BA_ "U_U55X_MY2022_Tx" SG_ 578 immoSecureIdleMode 1;
BA_ "U_CD764_MY2022_Tx" SG_ 578 immoSecureIdleMode 1;
BA_ "WakeupSignal" SG_ 578 ReFuelSwtchStat_D_Actl 1;
BA_ "U_CX727_MY2021_Tx" SG_ 578 ReFuelSwtchStat_D_Actl 1;
BA_ "U_P702_MY2021_Tx" SG_ 578 ReFuelSwtchStat_D_Actl 1;
BA_ "U_T6_MCA_MY2020_Tx" SG_ 578 ReFuelSwtchStat_D_Actl 1;
BA_ "U_CD542_MY2021_Tx" SG_ 578 ReFuelSwtchStat_D_Actl 1;
BA_ "U_U55X_MY2022_Tx" SG_ 578 ReFuelSwtchStat_D_Actl 1;
BA_ "U_CD764_MY2022_Tx" SG_ 578 ReFuelSwtchStat_D_Actl 1;
BA_ "U_CX727_MY2021_Tx" SG_ 578 FuelPumpPwr_D_Stat 1;
BA_ "U_P702_MY2021_Tx" SG_ 578 FuelPumpPwr_D_Stat 1;
BA_ "U_T6_MCA_MY2020_Tx" SG_ 578 FuelPumpPwr_D_Stat 1;
BA_ "U_CD542_MY2021_Tx" SG_ 578 FuelPumpPwr_D_Stat 1;
BA_ "U_U55X_MY2022_Tx" SG_ 578 FuelPumpPwr_D_Stat 1;
BA_ "U_CD764_MY2022_Tx" SG_ 578 FuelPumpPwr_D_Stat 1;
BA_ "GenSigStartValueInteger" SG_ 578 BattULo_U_Actl 255;
BA_ "GenSigStartValue" SG_ 578 BattULo_U_Actl 255;
BA_ "U_CX727_MY2021_Rx" SG_ 578 BattULo_U_Actl 1;
BA_ "U_P702_MY2021_Rx" SG_ 578 BattULo_U_Actl 1;
BA_ "U_CD542_MY2021_Rx" SG_ 578 BattULo_U_Actl 1;
BA_ "U_T6_MCA_MY2020_Rx" SG_ 578 BattULo_U_Actl 1;
BA_ "ECGUsedRxSignal" SG_ 578 BattULo_U_Actl 1;
BA_ "U_U55X_MY2022_Rx" SG_ 578 BattULo_U_Actl 1;
BA_ "U_CX727_MY2021_Tx" SG_ 578 BattULo_U_Actl 1;
BA_ "U_P702_MY2021_Tx" SG_ 578 BattULo_U_Actl 1;
BA_ "U_T6_MCA_MY2020_Tx" SG_ 578 BattULo_U_Actl 1;
BA_ "U_CD542_MY2021_Tx" SG_ 578 BattULo_U_Actl 1;
BA_ "U_U55X_MY2022_Tx" SG_ 578 BattULo_U_Actl 1;
BA_ "U_CD764_MY2022_Tx" SG_ 578 BattULo_U_Actl 1;
BA_ "U_CX727_MY2021_Tx" SG_ 578 PrkLckCtl_B_Enbl 1;
BA_ "U_P702_MY2021_Tx" SG_ 578 PrkLckCtl_B_Enbl 1;
BA_ "U_T6_MCA_MY2020_Tx" SG_ 578 PrkLckCtl_B_Enbl 1;
BA_ "U_CD542_MY2021_Tx" SG_ 578 PrkLckCtl_B_Enbl 1;
BA_ "U_U55X_MY2022_Tx" SG_ 578 PrkLckCtl_B_Enbl 1;
BA_ "U_CD764_MY2022_Tx" SG_ 578 PrkLckCtl_B_Enbl 1;
BA_ "WakeupSignal" SG_ 578 PrkLckCtlMsgTxt_D_Rq 1;
BA_ "U_CX727_MY2021_Tx" SG_ 578 PrkLckCtlMsgTxt_D_Rq 1;
BA_ "U_P702_MY2021_Tx" SG_ 578 PrkLckCtlMsgTxt_D_Rq 1;
BA_ "U_T6_MCA_MY2020_Tx" SG_ 578 PrkLckCtlMsgTxt_D_Rq 1;
BA_ "U_CD542_MY2021_Tx" SG_ 578 PrkLckCtlMsgTxt_D_Rq 1;
BA_ "U_U55X_MY2022_Tx" SG_ 578 PrkLckCtlMsgTxt_D_Rq 1;
BA_ "U_CD764_MY2022_Tx" SG_ 578 PrkLckCtlMsgTxt_D_Rq 1;
BA_ "WakeupSignal" SG_ 578 PrkLckCtlAvail_T_Stat 1;
BA_ "U_CX727_MY2021_Tx" SG_ 578 PrkLckCtlAvail_T_Stat 1;
BA_ "U_P702_MY2021_Tx" SG_ 578 PrkLckCtlAvail_T_Stat 1;
BA_ "U_T6_MCA_MY2020_Tx" SG_ 578 PrkLckCtlAvail_T_Stat 1;
BA_ "U_CD542_MY2021_Tx" SG_ 578 PrkLckCtlAvail_T_Stat 1;
BA_ "U_U55X_MY2022_Tx" SG_ 578 PrkLckCtlAvail_T_Stat 1;
BA_ "U_CD764_MY2022_Tx" SG_ 578 PrkLckCtlAvail_T_Stat 1;
BA_ "U_CX727_MY2021_Tx" SG_ 578 BrkTrnShifLck_B_Stat 1;
BA_ "U_P702_MY2021_Tx" SG_ 578 BrkTrnShifLck_B_Stat 1;
BA_ "U_T6_MCA_MY2020_Tx" SG_ 578 BrkTrnShifLck_B_Stat 1;
BA_ "U_CD542_MY2021_Tx" SG_ 578 BrkTrnShifLck_B_Stat 1;
BA_ "U_U55X_MY2022_Tx" SG_ 578 BrkTrnShifLck_B_Stat 1;
BA_ "U_CD764_MY2022_Tx" SG_ 578 BrkTrnShifLck_B_Stat 1;
BA_ "U_CX727_MY2021_Tx" SG_ 578 PrkLckCtlUnlck_D_Stat 1;
BA_ "U_P702_MY2021_Tx" SG_ 578 PrkLckCtlUnlck_D_Stat 1;
BA_ "U_T6_MCA_MY2020_Tx" SG_ 578 PrkLckCtlUnlck_D_Stat 1;
BA_ "U_CD542_MY2021_Tx" SG_ 578 PrkLckCtlUnlck_D_Stat 1;
BA_ "U_U55X_MY2022_Tx" SG_ 578 PrkLckCtlUnlck_D_Stat 1;
BA_ "U_CD764_MY2022_Tx" SG_ 578 PrkLckCtlUnlck_D_Stat 1;
BA_ "U_CX727_MY2021_Tx" SG_ 578 PrkLckCtlTow_B_Enbl 1;
BA_ "U_P702_MY2021_Tx" SG_ 578 PrkLckCtlTow_B_Enbl 1;
BA_ "U_T6_MCA_MY2020_Tx" SG_ 578 PrkLckCtlTow_B_Enbl 1;
BA_ "U_CD542_MY2021_Tx" SG_ 578 PrkLckCtlTow_B_Enbl 1;
BA_ "U_U55X_MY2022_Tx" SG_ 578 PrkLckCtlTow_B_Enbl 1;
BA_ "U_CD764_MY2022_Tx" SG_ 578 PrkLckCtlTow_B_Enbl 1;
BA_ "U_CX727_MY2021_Tx" SG_ 578 DriverCrankingReq 1;
BA_ "U_P702_MY2021_Tx" SG_ 578 DriverCrankingReq 1;
BA_ "U_T6_MCA_MY2020_Tx" SG_ 578 DriverCrankingReq 1;
BA_ "U_CD542_MY2021_Tx" SG_ 578 DriverCrankingReq 1;
BA_ "U_U55X_MY2022_Tx" SG_ 578 DriverCrankingReq 1;
BA_ "U_CD764_MY2022_Tx" SG_ 578 DriverCrankingReq 1;
BA_ "U_U55X_MY2022_Rx" SG_ 578 EngOff_T_Actl 1;
BA_ "U_CX727_MY2021_Tx" SG_ 578 EngOff_T_Actl 1;
BA_ "U_P702_MY2021_Tx" SG_ 578 EngOff_T_Actl 1;
BA_ "U_T6_MCA_MY2020_Tx" SG_ 578 EngOff_T_Actl 1;
BA_ "U_CD542_MY2021_Tx" SG_ 578 EngOff_T_Actl 1;
BA_ "U_U55X_MY2022_Tx" SG_ 578 EngOff_T_Actl 1;
BA_ "U_CD764_MY2022_Tx" SG_ 578 EngOff_T_Actl 1;
BA_ "U_CX727_MY2021_Tx" SG_ 578 DcacElPw_D_Rq 1;
BA_ "U_P702_MY2021_Tx" SG_ 578 DcacElPw_D_Rq 1;
BA_ "U_T6_MCA_MY2020_Tx" SG_ 578 DcacElPw_D_Rq 1;
BA_ "U_CD542_MY2021_Tx" SG_ 578 DcacElPw_D_Rq 1;
BA_ "U_U55X_MY2022_Tx" SG_ 578 DcacElPw_D_Rq 1;
BA_ "U_CD764_MY2022_Tx" SG_ 578 DcacElPw_D_Rq 1;
BA_ "GenSigStartValueInteger" SG_ 578 BattULo_I_Actl 16383;
BA_ "GenSigStartValue" SG_ 578 BattULo_I_Actl 16383;
BA_ "U_CX727_MY2021_Tx" SG_ 578 BattULo_I_Actl 1;
BA_ "U_P702_MY2021_Tx" SG_ 578 BattULo_I_Actl 1;
BA_ "U_T6_MCA_MY2020_Tx" SG_ 578 BattULo_I_Actl 1;
BA_ "U_CD542_MY2021_Tx" SG_ 578 BattULo_I_Actl 1;
BA_ "U_U55X_MY2022_Tx" SG_ 578 BattULo_I_Actl 1;
BA_ "U_CD764_MY2022_Tx" SG_ 578 BattULo_I_Actl 1;
BA_ "U_T6_MCA_MY2020_Rx" SG_ 514 StrtrMtrCtlMsgTxt_D2_Rq 1;
BA_ "U_CD542_MY2021_Rx" SG_ 514 StrtrMtrCtlMsgTxt_D2_Rq 1;
BA_ "U_U55X_MY2022_Rx" SG_ 514 StrtrMtrCtlMsgTxt_D2_Rq 1;
BA_ "U_CD764_MY2022_Rx" SG_ 514 StrtrMtrCtlMsgTxt_D2_Rq 1;
BA_ "U_CX727_MY2021_Rx" SG_ 514 StrtrMtrDlyStrt_B_Stat 1;
BA_ "U_P702_MY2021_Rx" SG_ 514 StrtrMtrDlyStrt_B_Stat 1;
BA_ "U_T6_MCA_MY2020_Rx" SG_ 514 StrtrMtrDlyStrt_B_Stat 1;
BA_ "U_CD542_MY2021_Rx" SG_ 514 StrtrMtrDlyStrt_B_Stat 1;
BA_ "U_U55X_MY2022_Rx" SG_ 514 StrtrMtrDlyStrt_B_Stat 1;
BA_ "U_CD764_MY2022_Rx" SG_ 514 StrtrMtrDlyStrt_B_Stat 1;
BA_ "MetaData" SG_ 514 VehVActlEng_No_Cs 1;
BA_ "MetaData" SG_ 514 VehVActlEng_No_Cnt 1;
BA_ "MetaData" SG_ 514 VehVActlEng_D_Qf 1;
BA_ "U_CX727_MY2021_Rx" SG_ 514 VehVActlEng_D_Qf 1;
BA_ "U_P702_MY2021_Rx" SG_ 514 VehVActlEng_D_Qf 1;
BA_ "U_T6_MCA_MY2020_Rx" SG_ 514 VehVActlEng_D_Qf 1;
BA_ "U_CD542_MY2021_Rx" SG_ 514 VehVActlEng_D_Qf 1;
BA_ "U_U55X_MY2022_Rx" SG_ 514 VehVActlEng_D_Qf 1;
BA_ "U_CD764_MY2022_Rx" SG_ 514 VehVActlEng_D_Qf 1;
BA_ "U_CX727_MY2021_Rx" SG_ 514 Veh_V_ActlEng 1;
BA_ "U_P702_MY2021_Rx" SG_ 514 Veh_V_ActlEng 1;
BA_ "U_T6_MCA_MY2020_Rx" SG_ 514 Veh_V_ActlEng 1;
BA_ "U_CD542_MY2021_Rx" SG_ 514 Veh_V_ActlEng 1;
BA_ "U_U55X_MY2022_Rx" SG_ 514 Veh_V_ActlEng 1;
BA_ "U_CD764_MY2022_Rx" SG_ 514 Veh_V_ActlEng 1;
BA_ "ContentDependant" SG_ 514 EngAout_Tq_VacLimSpcN 1;
BA_ "ContentDependant" SG_ 514 EngCylSync_No_Ctr 1;
BA_ "GenSigStartValueInteger" SG_ 514 GearRvrse_D_Actl 7;
BA_ "GenSigStartValue" SG_ 514 GearRvrse_D_Actl 7;
BA_ "U_CX727_MY2021_Rx" SG_ 514 GearRvrse_D_Actl 1;
BA_ "U_P702_MY2021_Rx" SG_ 514 GearRvrse_D_Actl 1;
BA_ "U_T6_MCA_MY2020_Rx" SG_ 514 GearRvrse_D_Actl 1;
BA_ "U_CD542_MY2021_Rx" SG_ 514 GearRvrse_D_Actl 1;
BA_ "U_U55X_MY2022_Rx" SG_ 514 GearRvrse_D_Actl 1;
BA_ "U_CD764_MY2022_Rx" SG_ 514 GearRvrse_D_Actl 1;
BA_ "WakeupSignal" SG_ 1069 ReFuelSysStat_D_Dsply 1;
BA_ "U_CD542_MY2021_Rx" SG_ 1069 ULoSrcOnPlg_B_Cmd 1;
BA_ "U_CX727_MY2021_Rx" SG_ 1069 ULoSrcOnPlg_B_Cmd 1;
BA_ "U_CX727_MY2021_Rx" SG_ 1069 GrllShtrPos_D_Cmd 1;
BA_ "U_P702_MY2021_Rx" SG_ 1069 GrllShtrPos_D_Cmd 1;
BA_ "U_T6_MCA_MY2020_Rx" SG_ 1069 GrllShtrPos_D_Cmd 1;
BA_ "U_CD542_MY2021_Rx" SG_ 1069 GrllShtrPos_D_Cmd 1;
BA_ "U_U55X_MY2022_Rx" SG_ 1069 GrllShtrPos_D_Cmd 1;
BA_ "U_CD764_MY2022_Rx" SG_ 1069 GrllShtrPos_D_Cmd 1;
BA_ "U_CX727_MY2021_Rx" SG_ 1069 GrllShtrPos_B_Falt 1;
BA_ "U_P702_MY2021_Rx" SG_ 1069 GrllShtrPos_B_Falt 1;
BA_ "U_T6_MCA_MY2020_Rx" SG_ 1069 GrllShtrPos_B_Falt 1;
BA_ "U_CD542_MY2021_Rx" SG_ 1069 GrllShtrPos_B_Falt 1;
BA_ "U_U55X_MY2022_Rx" SG_ 1069 GrllShtrPos_B_Falt 1;
BA_ "U_CD764_MY2022_Rx" SG_ 1069 GrllShtrPos_B_Falt 1;
BA_ "ContentDependant" SG_ 1069 ObdWarmUp_B_Complt 1;
BA_ "U_CX727_MY2021_Rx" SG_ 1069 ObdWarmUp_B_Complt 1;
BA_ "U_P702_MY2021_Rx" SG_ 1069 ObdWarmUp_B_Complt 1;
BA_ "U_CD542_MY2021_Rx" SG_ 1069 ObdWarmUp_B_Complt 1;
BA_ "ContentDependant" SG_ 1069 EngMsgTxt_D_Rq 1;
BA_ "ContentDependant" SG_ 1069 EngClnt_Te_ActlDiag 1;
BA_ "U_CX727_MY2021_Rx" SG_ 1069 EngClnt_Te_ActlDiag 1;
BA_ "U_P702_MY2021_Rx" SG_ 1069 EngClnt_Te_ActlDiag 1;
BA_ "U_CD542_MY2021_Rx" SG_ 1069 EngClnt_Te_ActlDiag 1;
BA_ "ContentDependant" SG_ 1069 EngLoad_Pc_CalcDiag 1;
BA_ "U_CX727_MY2021_Rx" SG_ 1069 EngLoad_Pc_CalcDiag 1;
BA_ "U_P702_MY2021_Rx" SG_ 1069 EngLoad_Pc_CalcDiag 1;
BA_ "U_CD542_MY2021_Rx" SG_ 1069 EngLoad_Pc_CalcDiag 1;
BA_ "U_CX727_MY2021_Rx" SG_ 1069 EngAirIn_Te_Actl 1;
BA_ "U_P702_MY2021_Rx" SG_ 1069 EngAirIn_Te_Actl 1;
BA_ "U_T6_MCA_MY2020_Rx" SG_ 1069 EngAirIn_Te_Actl 1;
BA_ "U_CD542_MY2021_Rx" SG_ 1069 EngAirIn_Te_Actl 1;
BA_ "U_U55X_MY2022_Rx" SG_ 1069 EngAirIn_Te_Actl 1;
BA_ "U_CD764_MY2022_Rx" SG_ 1069 EngAirIn_Te_Actl 1;
BA_ "ContentDependant" SG_ 1069 ApedPos_Pc_ActlDiag 1;
BA_ "U_CX727_MY2021_Rx" SG_ 1069 ApedPos_Pc_ActlDiag 1;
BA_ "U_P702_MY2021_Rx" SG_ 1069 ApedPos_Pc_ActlDiag 1;
BA_ "U_CD542_MY2021_Rx" SG_ 1069 ApedPos_Pc_ActlDiag 1;
BA_ "GenSigSendType" SG_ 2015 TesterFunctionalReq 3;
BA_ "U_CX727_MY2021_Rx" SG_ 2015 TesterFunctionalReq 1;
BA_ "U_P702_MY2021_Rx" SG_ 2015 TesterFunctionalReq 1;
BA_ "U_T6_MCA_MY2020_Rx" SG_ 2015 TesterFunctionalReq 1;
BA_ "U_CD542_MY2021_Rx" SG_ 2015 TesterFunctionalReq 1;
BA_ "U_U55X_MY2022_Rx" SG_ 2015 TesterFunctionalReq 1;
BA_ "U_CD764_MY2022_Rx" SG_ 2015 TesterFunctionalReq 1;
BA_ "ECGUsedRxSignal" SG_ 2015 TesterFunctionalReq 1;
BA_ "GenSigStartValueInteger" SG_ 516 EngAoutNActl_D_QF 1;
BA_ "MetaData" SG_ 516 EngAoutNActl_D_QF 1;
BA_ "GenSigStartValue" SG_ 516 EngAoutNActl_D_QF 1;
BA_ "ContentDependant" SG_ 516 EngAout3_N_Actl 1;
BA_ "U_CX727_MY2021_Rx" SG_ 516 EngAout3_N_Actl 1;
BA_ "U_CX727_MY2021_Rx" SG_ 516 ApedPos_Pc_ActlArb 1;
BA_ "U_P702_MY2021_Rx" SG_ 516 ApedPos_Pc_ActlArb 1;
BA_ "U_T6_MCA_MY2020_Rx" SG_ 516 ApedPos_Pc_ActlArb 1;
BA_ "U_CD542_MY2021_Rx" SG_ 516 ApedPos_Pc_ActlArb 1;
BA_ "U_U55X_MY2022_Rx" SG_ 516 ApedPos_Pc_ActlArb 1;
BA_ "U_CD764_MY2022_Rx" SG_ 516 ApedPos_Pc_ActlArb 1;
BA_ "GenSigStartValueInteger" SG_ 516 ApedPosPcActl_D_Qf 1;
BA_ "MetaData" SG_ 516 ApedPosPcActl_D_Qf 1;
BA_ "GenSigStartValue" SG_ 516 ApedPosPcActl_D_Qf 1;
BA_ "U_CX727_MY2021_Rx" SG_ 516 EngAout_N_Actl 1;
BA_ "U_P702_MY2021_Rx" SG_ 516 EngAout_N_Actl 1;
BA_ "U_T6_MCA_MY2020_Rx" SG_ 516 EngAout_N_Actl 1;
BA_ "U_CD542_MY2021_Rx" SG_ 516 EngAout_N_Actl 1;
BA_ "U_U55X_MY2022_Rx" SG_ 516 EngAout_N_Actl 1;
BA_ "U_CD764_MY2022_Rx" SG_ 516 EngAout_N_Actl 1;
BA_ "ContentDependant" SG_ 516 ApedPosPcActl_No_Cnt 1;
BA_ "MetaData" SG_ 516 ApedPosPcActl_No_Cnt 1;
BA_ "ContentDependant" SG_ 516 ApedPosPcActl_No_Cs 1;
BA_ "MetaData" SG_ 516 ApedPosPcActl_No_Cs 1;
BA_ "MetaData" SG_ 76 FirstRowBuckle_No_Cs 1;
BA_ "MetaData" SG_ 76 RCMStatusMsg2_No_Cnt 1;
BA_ "GenSigStartValueInteger" SG_ 76 PsngrFmidDetct_D_Actl 3;
BA_ "GenSigStartValue" SG_ 76 PsngrFmidDetct_D_Actl 3;
BA_ "GenSigStartValueInteger" SG_ 76 FirstRowBuckleMid 3;
BA_ "GenSigStartValue" SG_ 76 FirstRowBuckleMid 3;
BA_ "GenSigStartValueInteger" SG_ 76 ThirdRowBucklePsngr 3;
BA_ "GenSigStartValue" SG_ 76 ThirdRowBucklePsngr 3;
BA_ "GenSigStartValueInteger" SG_ 76 ThirdRowBuckleMid 3;
BA_ "GenSigStartValue" SG_ 76 ThirdRowBuckleMid 3;
BA_ "GenSigStartValueInteger" SG_ 76 ThirdRowBuckleDriver 3;
BA_ "GenSigStartValue" SG_ 76 ThirdRowBuckleDriver 3;
BA_ "GenSigStartValueInteger" SG_ 76 SecondRowBucklePsngr 3;
BA_ "GenSigStartValue" SG_ 76 SecondRowBucklePsngr 3;
BA_ "GenSigStartValueInteger" SG_ 76 SecondRowBuckleMid 3;
BA_ "GenSigStartValue" SG_ 76 SecondRowBuckleMid 3;
BA_ "GenSigStartValueInteger" SG_ 76 SecondRowBuckleDriver 3;
BA_ "GenSigStartValue" SG_ 76 SecondRowBuckleDriver 3;
BA_ "GenSigStartValueInteger" SG_ 76 FirstRowBuckleDriver 3;
BA_ "GenSigStartValue" SG_ 76 FirstRowBuckleDriver 3;
BA_ "U_CX727_MY2021_Rx" SG_ 76 FirstRowBuckleDriver 1;
BA_ "U_P702_MY2021_Rx" SG_ 76 FirstRowBuckleDriver 1;
BA_ "U_T6_MCA_MY2020_Rx" SG_ 76 FirstRowBuckleDriver 1;
BA_ "U_CD542_MY2021_Rx" SG_ 76 FirstRowBuckleDriver 1;
BA_ "U_U55X_MY2022_Rx" SG_ 76 FirstRowBuckleDriver 1;
BA_ "U_CD764_MY2022_Rx" SG_ 76 FirstRowBuckleDriver 1;
BA_ "GenSigStartValueInteger" SG_ 76 FirstRowBucklePsngr 3;
BA_ "GenSigStartValue" SG_ 76 FirstRowBucklePsngr 3;
BA_ "U_T6_MCA_MY2020_Rx" SG_ 76 FirstRowBucklePsngr 1;
BA_ "U_U55X_MY2022_Rx" SG_ 76 FirstRowBucklePsngr 1;
BA_ "WakeupSignal" SG_ 76 RstrnImpactEvntStatus 1;
BA_ "U_CX727_MY2021_Rx" SG_ 76 RstrnImpactEvntStatus 1;
BA_ "U_P702_MY2021_Rx" SG_ 76 RstrnImpactEvntStatus 1;
BA_ "U_CD542_MY2021_Rx" SG_ 76 RstrnImpactEvntStatus 1;
BA_ "U_T6_MCA_MY2020_Rx" SG_ 76 RstrnImpactEvntStatus 1;
BA_ "U_U55X_MY2022_Rx" SG_ 76 RstrnImpactEvntStatus 1;
BA_ "U_CD764_MY2022_Rx" SG_ 76 RstrnImpactEvntStatus 1;
BA_ "GenSigStartValueInteger" SG_ 76 PsngrFrntDetct_D_Actl 3;
BA_ "GenSigStartValue" SG_ 76 PsngrFrntDetct_D_Actl 3;
BA_ "GenSigStartValueInteger" SG_ 76 PassRstrnInd_Req 3;
BA_ "GenSigStartValue" SG_ 76 PassRstrnInd_Req 3;
BA_ "GenSigSendType" SG_ 2028 TesterPhysicalResBECM 3;
BA_ "U_CX727_MY2021_Tx" SG_ 2028 TesterPhysicalResBECM 1;
BA_ "U_P702_MY2021_Tx" SG_ 2028 TesterPhysicalResBECM 1;
BA_ "U_CD542_MY2021_Tx" SG_ 2028 TesterPhysicalResBECM 1;
BA_ "GenSigSendType" SG_ 2020 TesterPhysicalReqBECM 3;
BA_ "U_CX727_MY2021_Rx" SG_ 2020 TesterPhysicalReqBECM 1;
BA_ "U_P702_MY2021_Rx" SG_ 2020 TesterPhysicalReqBECM 1;
BA_ "U_CD542_MY2021_Rx" SG_ 2020 TesterPhysicalReqBECM 1;
BA_ "MetaData" SG_ 862 ApaSwtch_No_Cnt 1;
BA_ "U_CX727_MY2021_Rx" SG_ 862 HvacBlwrFront_D_Stat 1;
BA_ "U_P702_MY2021_Rx" SG_ 862 HvacBlwrFront_D_Stat 1;
BA_ "U_T6_MCA_MY2020_Rx" SG_ 862 HvacBlwrFront_D_Stat 1;
BA_ "U_CD542_MY2021_Rx" SG_ 862 HvacBlwrFront_D_Stat 1;
BA_ "U_U55X_MY2022_Rx" SG_ 862 HvacBlwrFront_D_Stat 1;
BA_ "U_CD764_MY2022_Rx" SG_ 862 HvacBlwrFront_D_Stat 1;
BA_ "U_CX727_MY2021_Rx" SG_ 862 HvacBlwrRear_D_Stat 1;
BA_ "U_P702_MY2021_Rx" SG_ 862 HvacBlwrRear_D_Stat 1;
BA_ "U_T6_MCA_MY2020_Rx" SG_ 862 HvacBlwrRear_D_Stat 1;
BA_ "U_CD542_MY2021_Rx" SG_ 862 HvacBlwrRear_D_Stat 1;
BA_ "U_U55X_MY2022_Rx" SG_ 862 HvacBlwrRear_D_Stat 1;
BA_ "U_CD764_MY2022_Rx" SG_ 862 HvacBlwrRear_D_Stat 1;
BA_ "GenSigStartValueInteger" SG_ 862 CabnAmb_Te_Actl 114;
BA_ "U_CX727_MY2021_Rx" SG_ 862 CabnAmb_Te_Actl 1;
BA_ "U_CD542_MY2021_Rx" SG_ 862 CabnAmb_Te_Actl 1;
BA_ "GenSigStartValueInteger" SG_ 862 ClimtThrmlLoad_No_Actl 255;
BA_ "GenSigStartValue" SG_ 862 ClimtThrmlLoad_No_Actl 255;
BA_ "GenSigStartValueInteger" SG_ 862 AutoStpHvacDelta_I_Est 192;
BA_ "U_CX727_MY2021_Rx" SG_ 862 AutoStpHvacDelta_I_Est 1;
BA_ "U_P702_MY2021_Rx" SG_ 862 AutoStpHvacDelta_I_Est 1;
BA_ "U_T6_MCA_MY2020_Rx" SG_ 862 AutoStpHvacDelta_I_Est 1;
BA_ "U_CD542_MY2021_Rx" SG_ 862 AutoStpHvacDelta_I_Est 1;
BA_ "U_U55X_MY2022_Rx" SG_ 862 AutoStpHvacDelta_I_Est 1;
BA_ "U_CD764_MY2022_Rx" SG_ 862 AutoStpHvacDelta_I_Est 1;
BA_ "ContentDependant" SG_ 560 SelDrvMdeSwtch_D_Stat3 1;
BA_ "ContentDependant" SG_ 560 GearLvrPosActl_No_Cs 1;
BA_ "MetaData" SG_ 560 GearLvrPosActl_No_Cs 1;
BA_ "ContentDependant" SG_ 560 GearLvrPosActl_No_Cnt 1;
BA_ "MetaData" SG_ 560 GearLvrPosActl_No_Cnt 1;
BA_ "ContentDependant" SG_ 560 TrnGbox_Rt_Actl 1;
BA_ "ContentDependant" SG_ 560 TrnSrvcRqd_B_Rq 1;
BA_ "ContentDependant" SG_ 560 TrnCnvtClu_D_Actl 1;
BA_ "ContentDependant" SG_ 560 TrnShifActv_B_Actl 1;
BA_ "GenSigStartValueInteger" SG_ 560 GearLvrPos_D_Actl 14;
BA_ "GenSigStartValue" SG_ 560 GearLvrPos_D_Actl 14;
BA_ "U_CX727_MY2021_Rx" SG_ 560 GearLvrPos_D_Actl 1;
BA_ "U_P702_MY2021_Rx" SG_ 560 GearLvrPos_D_Actl 1;
BA_ "U_T6_MCA_MY2020_Rx" SG_ 560 GearLvrPos_D_Actl 1;
BA_ "U_CD542_MY2021_Rx" SG_ 560 GearLvrPos_D_Actl 1;
BA_ "U_U55X_MY2022_Rx" SG_ 560 GearLvrPos_D_Actl 1;
BA_ "U_CD764_MY2022_Rx" SG_ 560 GearLvrPos_D_Actl 1;
BA_ "GenSigStartValueInteger" SG_ 560 GboxOil_Te_Actl 254;
BA_ "ContentDependant" SG_ 560 GboxOil_Te_Actl 1;
BA_ "GenSigStartValue" SG_ 560 GboxOil_Te_Actl 254;
BA_ "U_CX727_MY2021_Rx" SG_ 1034 VehicleGGCCData 1;
BA_ "U_P702_MY2021_Rx" SG_ 1034 VehicleGGCCData 1;
BA_ "U_CD542_MY2021_Rx" SG_ 1034 VehicleGGCCData 1;
BA_ "U_U55X_MY2022_Rx" SG_ 1034 VehicleGGCCData 1;
BA_ "U_T6_MCA_MY2020_Rx" SG_ 1034 VehicleGGCCData 1;
BA_ "U_CX727_MY2021_Tx" SG_ 1034 VehicleGGCCData 1;
BA_ "U_P702_MY2021_Tx" SG_ 1034 VehicleGGCCData 1;
BA_ "U_T6_MCA_MY2020_Tx" SG_ 1034 VehicleGGCCData 1;
BA_ "U_CD542_MY2021_Tx" SG_ 1034 VehicleGGCCData 1;
BA_ "U_U55X_MY2022_Tx" SG_ 1034 VehicleGGCCData 1;
BA_ "U_CD764_MY2022_Tx" SG_ 1034 VehicleGGCCData 1;
BA_ "GenSigSendType" SG_ 947 ValetMode_D_Mem 3;
BA_ "U_CX727_MY2021_Tx" SG_ 947 ValetMode_D_Mem 1;
BA_ "U_P702_MY2021_Tx" SG_ 947 ValetMode_D_Mem 1;
BA_ "U_T6_MCA_MY2020_Tx" SG_ 947 ValetMode_D_Mem 1;
BA_ "U_CD542_MY2021_Tx" SG_ 947 ValetMode_D_Mem 1;
BA_ "U_U55X_MY2022_Tx" SG_ 947 ValetMode_D_Mem 1;
BA_ "U_CD764_MY2022_Tx" SG_ 947 ValetMode_D_Mem 1;
BA_ "WakeupSignal" SG_ 947 DimmingLvlEvnt_No_Actl 1;
BA_ "GenSigSendType" SG_ 947 DimmingLvlEvnt_No_Actl 3;
BA_ "U_CX727_MY2021_Tx" SG_ 947 DimmingLvlEvnt_No_Actl 1;
BA_ "U_P702_MY2021_Tx" SG_ 947 DimmingLvlEvnt_No_Actl 1;
BA_ "U_T6_MCA_MY2020_Tx" SG_ 947 DimmingLvlEvnt_No_Actl 1;
BA_ "U_CD542_MY2021_Tx" SG_ 947 DimmingLvlEvnt_No_Actl 1;
BA_ "U_U55X_MY2022_Tx" SG_ 947 DimmingLvlEvnt_No_Actl 1;
BA_ "U_CD764_MY2022_Tx" SG_ 947 DimmingLvlEvnt_No_Actl 1;
BA_ "GenSigSendType" SG_ 947 DrStatDrvErrCnt_B_Stat 3;
BA_ "U_CX727_MY2021_Tx" SG_ 947 DrStatDrvErrCnt_B_Stat 1;
BA_ "U_P702_MY2021_Tx" SG_ 947 DrStatDrvErrCnt_B_Stat 1;
BA_ "U_T6_MCA_MY2020_Tx" SG_ 947 DrStatDrvErrCnt_B_Stat 1;
BA_ "U_CD542_MY2021_Tx" SG_ 947 DrStatDrvErrCnt_B_Stat 1;
BA_ "U_U55X_MY2022_Tx" SG_ 947 DrStatDrvErrCnt_B_Stat 1;
BA_ "U_CD764_MY2022_Tx" SG_ 947 DrStatDrvErrCnt_B_Stat 1;
BA_ "WakeupSignal" SG_ 947 TurnLghtRight_D_Rq 1;
BA_ "GenSigSendType" SG_ 947 TurnLghtRight_D_Rq 3;
BA_ "U_CX727_MY2021_Tx" SG_ 947 TurnLghtRight_D_Rq 1;
BA_ "U_P702_MY2021_Tx" SG_ 947 TurnLghtRight_D_Rq 1;
BA_ "U_T6_MCA_MY2020_Tx" SG_ 947 TurnLghtRight_D_Rq 1;
BA_ "U_CD542_MY2021_Tx" SG_ 947 TurnLghtRight_D_Rq 1;
BA_ "U_U55X_MY2022_Tx" SG_ 947 TurnLghtRight_D_Rq 1;
BA_ "U_CD764_MY2022_Tx" SG_ 947 TurnLghtRight_D_Rq 1;
BA_ "GenSigSendType" SG_ 947 TurnLghtRightOn_B_Stat 3;
BA_ "U_CX727_MY2021_Tx" SG_ 947 TurnLghtRightOn_B_Stat 1;
BA_ "U_P702_MY2021_Tx" SG_ 947 TurnLghtRightOn_B_Stat 1;
BA_ "U_T6_MCA_MY2020_Tx" SG_ 947 TurnLghtRightOn_B_Stat 1;
BA_ "U_CD542_MY2021_Tx" SG_ 947 TurnLghtRightOn_B_Stat 1;
BA_ "U_U55X_MY2022_Tx" SG_ 947 TurnLghtRightOn_B_Stat 1;
BA_ "U_CD764_MY2022_Tx" SG_ 947 TurnLghtRightOn_B_Stat 1;
BA_ "GenSigSendType" SG_ 947 TurnLghtLeftOn_B_Stat 3;
BA_ "U_CX727_MY2021_Tx" SG_ 947 TurnLghtLeftOn_B_Stat 1;
BA_ "U_P702_MY2021_Tx" SG_ 947 TurnLghtLeftOn_B_Stat 1;
BA_ "U_T6_MCA_MY2020_Tx" SG_ 947 TurnLghtLeftOn_B_Stat 1;
BA_ "U_CD542_MY2021_Tx" SG_ 947 TurnLghtLeftOn_B_Stat 1;
BA_ "U_U55X_MY2022_Tx" SG_ 947 TurnLghtLeftOn_B_Stat 1;
BA_ "U_CD764_MY2022_Tx" SG_ 947 TurnLghtLeftOn_B_Stat 1;
BA_ "GenSigSendType" SG_ 947 FogLghtRearOn_B_Stat 3;
BA_ "U_T6_MCA_MY2020_Rx" SG_ 947 FogLghtRearOn_B_Stat 1;
BA_ "ECGUsedRxSignal" SG_ 947 FogLghtRearOn_B_Stat 1;
BA_ "U_CD542_MY2021_Rx" SG_ 947 FogLghtRearOn_B_Stat 1;
BA_ "U_U55X_MY2022_Rx" SG_ 947 FogLghtRearOn_B_Stat 1;
BA_ "U_CD764_MY2022_Rx" SG_ 947 FogLghtRearOn_B_Stat 1;
BA_ "U_CX727_MY2021_Tx" SG_ 947 FogLghtRearOn_B_Stat 1;
BA_ "U_P702_MY2021_Tx" SG_ 947 FogLghtRearOn_B_Stat 1;
BA_ "U_T6_MCA_MY2020_Tx" SG_ 947 FogLghtRearOn_B_Stat 1;
BA_ "U_CD542_MY2021_Tx" SG_ 947 FogLghtRearOn_B_Stat 1;
BA_ "U_U55X_MY2022_Tx" SG_ 947 FogLghtRearOn_B_Stat 1;
BA_ "U_CD764_MY2022_Tx" SG_ 947 FogLghtRearOn_B_Stat 1;
BA_ "WakeupSignal" SG_ 947 Backlit_LED_Status 1;
BA_ "GenSigSendType" SG_ 947 Backlit_LED_Status 3;
BA_ "U_CX727_MY2021_Tx" SG_ 947 Backlit_LED_Status 1;
BA_ "U_P702_MY2021_Tx" SG_ 947 Backlit_LED_Status 1;
BA_ "U_T6_MCA_MY2020_Tx" SG_ 947 Backlit_LED_Status 1;
BA_ "U_CD542_MY2021_Tx" SG_ 947 Backlit_LED_Status 1;
BA_ "U_U55X_MY2022_Tx" SG_ 947 Backlit_LED_Status 1;
BA_ "U_CD764_MY2022_Tx" SG_ 947 Backlit_LED_Status 1;
BA_ "WakeupSignal" SG_ 947 TurnLghtLeft_D_Rq 1;
BA_ "GenSigSendType" SG_ 947 TurnLghtLeft_D_Rq 3;
BA_ "U_CX727_MY2021_Tx" SG_ 947 TurnLghtLeft_D_Rq 1;
BA_ "U_P702_MY2021_Tx" SG_ 947 TurnLghtLeft_D_Rq 1;
BA_ "U_T6_MCA_MY2020_Tx" SG_ 947 TurnLghtLeft_D_Rq 1;
BA_ "U_CD542_MY2021_Tx" SG_ 947 TurnLghtLeft_D_Rq 1;
BA_ "U_U55X_MY2022_Tx" SG_ 947 TurnLghtLeft_D_Rq 1;
BA_ "U_CD764_MY2022_Tx" SG_ 947 TurnLghtLeft_D_Rq 1;
BA_ "GenSigSendType" SG_ 947 FogLghtFrontOn_B_Stat 3;
BA_ "U_T6_MCA_MY2020_Rx" SG_ 947 FogLghtFrontOn_B_Stat 1;
BA_ "ECGUsedRxSignal" SG_ 947 FogLghtFrontOn_B_Stat 1;
BA_ "U_CD542_MY2021_Rx" SG_ 947 FogLghtFrontOn_B_Stat 1;
BA_ "U_U55X_MY2022_Rx" SG_ 947 FogLghtFrontOn_B_Stat 1;
BA_ "U_CD764_MY2022_Rx" SG_ 947 FogLghtFrontOn_B_Stat 1;
BA_ "U_CX727_MY2021_Tx" SG_ 947 FogLghtFrontOn_B_Stat 1;
BA_ "U_P702_MY2021_Tx" SG_ 947 FogLghtFrontOn_B_Stat 1;
BA_ "U_T6_MCA_MY2020_Tx" SG_ 947 FogLghtFrontOn_B_Stat 1;
BA_ "U_CD542_MY2021_Tx" SG_ 947 FogLghtFrontOn_B_Stat 1;
BA_ "U_U55X_MY2022_Tx" SG_ 947 FogLghtFrontOn_B_Stat 1;
BA_ "U_CD764_MY2022_Tx" SG_ 947 FogLghtFrontOn_B_Stat 1;
BA_ "GenSigStartValueInteger" SG_ 947 IgnKeyType_D_Actl 14;
BA_ "GenSigStartValue" SG_ 947 IgnKeyType_D_Actl 14;
BA_ "GenSigSendType" SG_ 947 IgnKeyType_D_Actl 3;
BA_ "U_CX727_MY2021_Tx" SG_ 947 IgnKeyType_D_Actl 1;
BA_ "U_P702_MY2021_Tx" SG_ 947 IgnKeyType_D_Actl 1;
BA_ "U_T6_MCA_MY2020_Tx" SG_ 947 IgnKeyType_D_Actl 1;
BA_ "U_CD542_MY2021_Tx" SG_ 947 IgnKeyType_D_Actl 1;
BA_ "U_U55X_MY2022_Tx" SG_ 947 IgnKeyType_D_Actl 1;
BA_ "U_CD764_MY2022_Tx" SG_ 947 IgnKeyType_D_Actl 1;
BA_ "WakeupSignal" SG_ 947 Parklamp_Status 1;
BA_ "GenSigStartValueInteger" SG_ 947 Parklamp_Status 1;
BA_ "GenSigStartValue" SG_ 947 Parklamp_Status 1;
BA_ "GenSigSendType" SG_ 947 Parklamp_Status 3;
BA_ "U_T6_MCA_MY2020_Rx" SG_ 947 Parklamp_Status 1;
BA_ "ECGUsedRxSignal" SG_ 947 Parklamp_Status 1;
BA_ "U_CD542_MY2021_Rx" SG_ 947 Parklamp_Status 1;
BA_ "U_U55X_MY2022_Rx" SG_ 947 Parklamp_Status 1;
BA_ "U_CD764_MY2022_Rx" SG_ 947 Parklamp_Status 1;
BA_ "U_CX727_MY2021_Tx" SG_ 947 Parklamp_Status 1;
BA_ "U_P702_MY2021_Tx" SG_ 947 Parklamp_Status 1;
BA_ "U_T6_MCA_MY2020_Tx" SG_ 947 Parklamp_Status 1;
BA_ "U_CD542_MY2021_Tx" SG_ 947 Parklamp_Status 1;
BA_ "U_U55X_MY2022_Tx" SG_ 947 Parklamp_Status 1;
BA_ "U_CD764_MY2022_Tx" SG_ 947 Parklamp_Status 1;
BA_ "WakeupSignal" SG_ 947 Litval 1;
BA_ "GenSigSendType" SG_ 947 Litval 3;
BA_ "U_CX727_MY2021_Tx" SG_ 947 Litval 1;
BA_ "U_P702_MY2021_Tx" SG_ 947 Litval 1;
BA_ "U_T6_MCA_MY2020_Tx" SG_ 947 Litval 1;
BA_ "U_CD542_MY2021_Tx" SG_ 947 Litval 1;
BA_ "U_U55X_MY2022_Tx" SG_ 947 Litval 1;
BA_ "U_CD764_MY2022_Tx" SG_ 947 Litval 1;
BA_ "WakeupSignal" SG_ 947 Key_In_Ignition_Stat 1;
BA_ "GenSigSendType" SG_ 947 Key_In_Ignition_Stat 3;
BA_ "U_CX727_MY2021_Tx" SG_ 947 Key_In_Ignition_Stat 1;
BA_ "U_P702_MY2021_Tx" SG_ 947 Key_In_Ignition_Stat 1;
BA_ "U_T6_MCA_MY2020_Tx" SG_ 947 Key_In_Ignition_Stat 1;
BA_ "U_CD542_MY2021_Tx" SG_ 947 Key_In_Ignition_Stat 1;
BA_ "U_U55X_MY2022_Tx" SG_ 947 Key_In_Ignition_Stat 1;
BA_ "U_CD764_MY2022_Tx" SG_ 947 Key_In_Ignition_Stat 1;
BA_ "WakeupSignal" SG_ 947 Ignition_Status 1;
BA_ "GenSigSendType" SG_ 947 Ignition_Status 3;
BA_ "U_CX727_MY2021_Rx" SG_ 947 Ignition_Status 1;
BA_ "U_P702_MY2021_Rx" SG_ 947 Ignition_Status 1;
BA_ "U_CD542_MY2021_Rx" SG_ 947 Ignition_Status 1;
BA_ "U_U55X_MY2022_Rx" SG_ 947 Ignition_Status 1;
BA_ "U_T6_MCA_MY2020_Rx" SG_ 947 Ignition_Status 1;
BA_ "U_CD764_MY2022_Rx" SG_ 947 Ignition_Status 1;
BA_ "ECGUsedRxSignal" SG_ 947 Ignition_Status 1;
BA_ "U_CX727_MY2021_Tx" SG_ 947 Ignition_Status 1;
BA_ "U_P702_MY2021_Tx" SG_ 947 Ignition_Status 1;
BA_ "U_T6_MCA_MY2020_Tx" SG_ 947 Ignition_Status 1;
BA_ "U_CD542_MY2021_Tx" SG_ 947 Ignition_Status 1;
BA_ "U_U55X_MY2022_Tx" SG_ 947 Ignition_Status 1;
BA_ "U_CD764_MY2022_Tx" SG_ 947 Ignition_Status 1;
BA_ "WakeupSignal" SG_ 947 Dimming_Lvl 1;
BA_ "GenSigStartValueInteger" SG_ 947 Dimming_Lvl 12;
BA_ "GenSigStartValue" SG_ 947 Dimming_Lvl 12;
BA_ "GenSigSendType" SG_ 947 Dimming_Lvl 3;
BA_ "U_P702_MY2021_Rx" SG_ 947 Dimming_Lvl 1;
BA_ "U_CX727_MY2021_Tx" SG_ 947 Dimming_Lvl 1;
BA_ "U_P702_MY2021_Tx" SG_ 947 Dimming_Lvl 1;
BA_ "U_T6_MCA_MY2020_Tx" SG_ 947 Dimming_Lvl 1;
BA_ "U_CD542_MY2021_Tx" SG_ 947 Dimming_Lvl 1;
BA_ "U_U55X_MY2022_Tx" SG_ 947 Dimming_Lvl 1;
BA_ "U_CD764_MY2022_Tx" SG_ 947 Dimming_Lvl 1;
BA_ "WakeupSignal" SG_ 947 Day_Night_Status 1;
BA_ "GenSigSendType" SG_ 947 Day_Night_Status 3;
BA_ "U_CX727_MY2021_Rx" SG_ 947 Day_Night_Status 1;
BA_ "U_CD542_MY2021_Rx" SG_ 947 Day_Night_Status 1;
BA_ "U_CX727_MY2021_Tx" SG_ 947 Day_Night_Status 1;
BA_ "U_P702_MY2021_Tx" SG_ 947 Day_Night_Status 1;
BA_ "U_T6_MCA_MY2020_Tx" SG_ 947 Day_Night_Status 1;
BA_ "U_CD542_MY2021_Tx" SG_ 947 Day_Night_Status 1;
BA_ "U_U55X_MY2022_Tx" SG_ 947 Day_Night_Status 1;
BA_ "U_CD764_MY2022_Tx" SG_ 947 Day_Night_Status 1;
BA_ "WakeupSignal" SG_ 947 Remote_Start_Status 1;
BA_ "GenSigSendType" SG_ 947 Remote_Start_Status 3;
BA_ "U_CX727_MY2021_Rx" SG_ 947 Remote_Start_Status 1;
BA_ "U_P702_MY2021_Rx" SG_ 947 Remote_Start_Status 1;
BA_ "U_T6_MCA_MY2020_Rx" SG_ 947 Remote_Start_Status 1;
BA_ "U_CD542_MY2021_Rx" SG_ 947 Remote_Start_Status 1;
BA_ "U_U55X_MY2022_Rx" SG_ 947 Remote_Start_Status 1;
BA_ "U_CD764_MY2022_Rx" SG_ 947 Remote_Start_Status 1;
BA_ "U_CX727_MY2021_Tx" SG_ 947 Remote_Start_Status 1;
BA_ "U_P702_MY2021_Tx" SG_ 947 Remote_Start_Status 1;
BA_ "U_T6_MCA_MY2020_Tx" SG_ 947 Remote_Start_Status 1;
BA_ "U_CD542_MY2021_Tx" SG_ 947 Remote_Start_Status 1;
BA_ "U_U55X_MY2022_Tx" SG_ 947 Remote_Start_Status 1;
BA_ "U_CD764_MY2022_Tx" SG_ 947 Remote_Start_Status 1;
BA_ "WakeupSignal" SG_ 947 DrStatTgate_B_Actl 1;
BA_ "GenSigSendType" SG_ 947 DrStatTgate_B_Actl 3;
BA_ "U_T6_MCA_MY2020_Rx" SG_ 947 DrStatTgate_B_Actl 1;
BA_ "ECGUsedRxSignal" SG_ 947 DrStatTgate_B_Actl 1;
BA_ "U_CD542_MY2021_Rx" SG_ 947 DrStatTgate_B_Actl 1;
BA_ "U_U55X_MY2022_Rx" SG_ 947 DrStatTgate_B_Actl 1;
BA_ "U_CD764_MY2022_Rx" SG_ 947 DrStatTgate_B_Actl 1;
BA_ "U_CX727_MY2021_Tx" SG_ 947 DrStatTgate_B_Actl 1;
BA_ "U_P702_MY2021_Tx" SG_ 947 DrStatTgate_B_Actl 1;
BA_ "U_T6_MCA_MY2020_Tx" SG_ 947 DrStatTgate_B_Actl 1;
BA_ "U_CD542_MY2021_Tx" SG_ 947 DrStatTgate_B_Actl 1;
BA_ "U_U55X_MY2022_Tx" SG_ 947 DrStatTgate_B_Actl 1;
BA_ "U_CD764_MY2022_Tx" SG_ 947 DrStatTgate_B_Actl 1;
BA_ "WakeupSignal" SG_ 947 DrStatRr_B_Actl 1;
BA_ "GenSigSendType" SG_ 947 DrStatRr_B_Actl 3;
BA_ "U_T6_MCA_MY2020_Rx" SG_ 947 DrStatRr_B_Actl 1;
BA_ "ECGUsedRxSignal" SG_ 947 DrStatRr_B_Actl 1;
BA_ "U_CD542_MY2021_Rx" SG_ 947 DrStatRr_B_Actl 1;
BA_ "U_U55X_MY2022_Rx" SG_ 947 DrStatRr_B_Actl 1;
BA_ "U_CD764_MY2022_Rx" SG_ 947 DrStatRr_B_Actl 1;
BA_ "U_CX727_MY2021_Tx" SG_ 947 DrStatRr_B_Actl 1;
BA_ "U_P702_MY2021_Tx" SG_ 947 DrStatRr_B_Actl 1;
BA_ "U_T6_MCA_MY2020_Tx" SG_ 947 DrStatRr_B_Actl 1;
BA_ "U_CD542_MY2021_Tx" SG_ 947 DrStatRr_B_Actl 1;
BA_ "U_U55X_MY2022_Tx" SG_ 947 DrStatRr_B_Actl 1;
BA_ "U_CD764_MY2022_Tx" SG_ 947 DrStatRr_B_Actl 1;
BA_ "WakeupSignal" SG_ 947 DrStatRl_B_Actl 1;
BA_ "GenSigSendType" SG_ 947 DrStatRl_B_Actl 3;
BA_ "U_T6_MCA_MY2020_Rx" SG_ 947 DrStatRl_B_Actl 1;
BA_ "ECGUsedRxSignal" SG_ 947 DrStatRl_B_Actl 1;
BA_ "U_CD542_MY2021_Rx" SG_ 947 DrStatRl_B_Actl 1;
BA_ "U_U55X_MY2022_Rx" SG_ 947 DrStatRl_B_Actl 1;
BA_ "U_CD764_MY2022_Rx" SG_ 947 DrStatRl_B_Actl 1;
BA_ "U_CX727_MY2021_Tx" SG_ 947 DrStatRl_B_Actl 1;
BA_ "U_P702_MY2021_Tx" SG_ 947 DrStatRl_B_Actl 1;
BA_ "U_T6_MCA_MY2020_Tx" SG_ 947 DrStatRl_B_Actl 1;
BA_ "U_CD542_MY2021_Tx" SG_ 947 DrStatRl_B_Actl 1;
BA_ "U_U55X_MY2022_Tx" SG_ 947 DrStatRl_B_Actl 1;
BA_ "U_CD764_MY2022_Tx" SG_ 947 DrStatRl_B_Actl 1;
BA_ "WakeupSignal" SG_ 947 DrStatPsngr_B_Actl 1;
BA_ "GenSigSendType" SG_ 947 DrStatPsngr_B_Actl 3;
BA_ "U_T6_MCA_MY2020_Rx" SG_ 947 DrStatPsngr_B_Actl 1;
BA_ "ECGUsedRxSignal" SG_ 947 DrStatPsngr_B_Actl 1;
BA_ "U_CD542_MY2021_Rx" SG_ 947 DrStatPsngr_B_Actl 1;
BA_ "U_U55X_MY2022_Rx" SG_ 947 DrStatPsngr_B_Actl 1;
BA_ "U_CD764_MY2022_Rx" SG_ 947 DrStatPsngr_B_Actl 1;
BA_ "U_CX727_MY2021_Tx" SG_ 947 DrStatPsngr_B_Actl 1;
BA_ "U_P702_MY2021_Tx" SG_ 947 DrStatPsngr_B_Actl 1;
BA_ "U_T6_MCA_MY2020_Tx" SG_ 947 DrStatPsngr_B_Actl 1;
BA_ "U_CD542_MY2021_Tx" SG_ 947 DrStatPsngr_B_Actl 1;
BA_ "U_U55X_MY2022_Tx" SG_ 947 DrStatPsngr_B_Actl 1;
BA_ "U_CD764_MY2022_Tx" SG_ 947 DrStatPsngr_B_Actl 1;
BA_ "WakeupSignal" SG_ 947 DrStatInnrTgate_B_Actl 1;
BA_ "GenSigSendType" SG_ 947 DrStatInnrTgate_B_Actl 3;
BA_ "U_T6_MCA_MY2020_Rx" SG_ 947 DrStatInnrTgate_B_Actl 1;
BA_ "ECGUsedRxSignal" SG_ 947 DrStatInnrTgate_B_Actl 1;
BA_ "U_CD542_MY2021_Rx" SG_ 947 DrStatInnrTgate_B_Actl 1;
BA_ "U_U55X_MY2022_Rx" SG_ 947 DrStatInnrTgate_B_Actl 1;
BA_ "U_CD764_MY2022_Rx" SG_ 947 DrStatInnrTgate_B_Actl 1;
BA_ "U_CX727_MY2021_Tx" SG_ 947 DrStatInnrTgate_B_Actl 1;
BA_ "U_P702_MY2021_Tx" SG_ 947 DrStatInnrTgate_B_Actl 1;
BA_ "U_T6_MCA_MY2020_Tx" SG_ 947 DrStatInnrTgate_B_Actl 1;
BA_ "U_CD542_MY2021_Tx" SG_ 947 DrStatInnrTgate_B_Actl 1;
BA_ "U_U55X_MY2022_Tx" SG_ 947 DrStatInnrTgate_B_Actl 1;
BA_ "U_CD764_MY2022_Tx" SG_ 947 DrStatInnrTgate_B_Actl 1;
BA_ "WakeupSignal" SG_ 947 DrStatHood_B_Actl 1;
BA_ "GenSigSendType" SG_ 947 DrStatHood_B_Actl 3;
BA_ "U_T6_MCA_MY2020_Rx" SG_ 947 DrStatHood_B_Actl 1;
BA_ "ECGUsedRxSignal" SG_ 947 DrStatHood_B_Actl 1;
BA_ "U_CD542_MY2021_Rx" SG_ 947 DrStatHood_B_Actl 1;
BA_ "U_U55X_MY2022_Rx" SG_ 947 DrStatHood_B_Actl 1;
BA_ "U_CD764_MY2022_Rx" SG_ 947 DrStatHood_B_Actl 1;
BA_ "U_CX727_MY2021_Tx" SG_ 947 DrStatHood_B_Actl 1;
BA_ "U_P702_MY2021_Tx" SG_ 947 DrStatHood_B_Actl 1;
BA_ "U_T6_MCA_MY2020_Tx" SG_ 947 DrStatHood_B_Actl 1;
BA_ "U_CD542_MY2021_Tx" SG_ 947 DrStatHood_B_Actl 1;
BA_ "U_U55X_MY2022_Tx" SG_ 947 DrStatHood_B_Actl 1;
BA_ "U_CD764_MY2022_Tx" SG_ 947 DrStatHood_B_Actl 1;
BA_ "WakeupSignal" SG_ 947 DrStatDrv_B_Actl 1;
BA_ "GenSigSendType" SG_ 947 DrStatDrv_B_Actl 3;
BA_ "U_T6_MCA_MY2020_Rx" SG_ 947 DrStatDrv_B_Actl 1;
BA_ "ECGUsedRxSignal" SG_ 947 DrStatDrv_B_Actl 1;
BA_ "U_CD542_MY2021_Rx" SG_ 947 DrStatDrv_B_Actl 1;
BA_ "U_U55X_MY2022_Rx" SG_ 947 DrStatDrv_B_Actl 1;
BA_ "U_CD764_MY2022_Rx" SG_ 947 DrStatDrv_B_Actl 1;
BA_ "U_CX727_MY2021_Tx" SG_ 947 DrStatDrv_B_Actl 1;
BA_ "U_P702_MY2021_Tx" SG_ 947 DrStatDrv_B_Actl 1;
BA_ "U_T6_MCA_MY2020_Tx" SG_ 947 DrStatDrv_B_Actl 1;
BA_ "U_CD542_MY2021_Tx" SG_ 947 DrStatDrv_B_Actl 1;
BA_ "U_U55X_MY2022_Tx" SG_ 947 DrStatDrv_B_Actl 1;
BA_ "U_CD764_MY2022_Tx" SG_ 947 DrStatDrv_B_Actl 1;
BA_ "WakeupSignal" SG_ 947 PrkBrkActv_B_Actl 1;
BA_ "ContentDependant" SG_ 947 PrkBrkActv_B_Actl 1;
BA_ "GenSigSendType" SG_ 947 PrkBrkActv_B_Actl 3;
BA_ "U_T6_MCA_MY2020_Rx" SG_ 947 PrkBrkActv_B_Actl 1;
BA_ "ECGUsedRxSignal" SG_ 947 PrkBrkActv_B_Actl 1;
BA_ "U_CD542_MY2021_Rx" SG_ 947 PrkBrkActv_B_Actl 1;
BA_ "U_U55X_MY2022_Rx" SG_ 947 PrkBrkActv_B_Actl 1;
BA_ "U_CD764_MY2022_Rx" SG_ 947 PrkBrkActv_B_Actl 1;
BA_ "U_CX727_MY2021_Tx" SG_ 947 PrkBrkActv_B_Actl 1;
BA_ "U_P702_MY2021_Tx" SG_ 947 PrkBrkActv_B_Actl 1;
BA_ "U_T6_MCA_MY2020_Tx" SG_ 947 PrkBrkActv_B_Actl 1;
BA_ "U_CD542_MY2021_Tx" SG_ 947 PrkBrkActv_B_Actl 1;
BA_ "U_U55X_MY2022_Tx" SG_ 947 PrkBrkActv_B_Actl 1;
BA_ "U_CD764_MY2022_Tx" SG_ 947 PrkBrkActv_B_Actl 1;
BA_ "GenSigSendType" SG_ 947 LifeCycMde_D_Actl 3;
BA_ "U_CX727_MY2021_Rx" SG_ 947 LifeCycMde_D_Actl 1;
BA_ "U_P702_MY2021_Rx" SG_ 947 LifeCycMde_D_Actl 1;
BA_ "U_CD542_MY2021_Rx" SG_ 947 LifeCycMde_D_Actl 1;
BA_ "U_T6_MCA_MY2020_Rx" SG_ 947 LifeCycMde_D_Actl 1;
BA_ "U_U55X_MY2022_Rx" SG_ 947 LifeCycMde_D_Actl 1;
BA_ "U_CD764_MY2022_Rx" SG_ 947 LifeCycMde_D_Actl 1;
BA_ "ECGUsedRxSignal" SG_ 947 LifeCycMde_D_Actl 1;
BA_ "U_CX727_MY2021_Tx" SG_ 947 LifeCycMde_D_Actl 1;
BA_ "U_P702_MY2021_Tx" SG_ 947 LifeCycMde_D_Actl 1;
BA_ "U_T6_MCA_MY2020_Tx" SG_ 947 LifeCycMde_D_Actl 1;
BA_ "U_CD542_MY2021_Tx" SG_ 947 LifeCycMde_D_Actl 1;
BA_ "U_U55X_MY2022_Tx" SG_ 947 LifeCycMde_D_Actl 1;
BA_ "U_CD764_MY2022_Tx" SG_ 947 LifeCycMde_D_Actl 1;
BA_ "WakeupSignal" SG_ 947 Delay_Accy 1;
BA_ "GenSigSendType" SG_ 947 Delay_Accy 3;
BA_ "U_T6_MCA_MY2020_Rx" SG_ 947 Delay_Accy 1;
BA_ "ECGUsedRxSignal" SG_ 947 Delay_Accy 1;
BA_ "U_CD542_MY2021_Rx" SG_ 947 Delay_Accy 1;
BA_ "U_U55X_MY2022_Rx" SG_ 947 Delay_Accy 1;
BA_ "U_CD764_MY2022_Rx" SG_ 947 Delay_Accy 1;
BA_ "U_CX727_MY2021_Tx" SG_ 947 Delay_Accy 1;
BA_ "U_P702_MY2021_Tx" SG_ 947 Delay_Accy 1;
BA_ "U_T6_MCA_MY2020_Tx" SG_ 947 Delay_Accy 1;
BA_ "U_CD542_MY2021_Tx" SG_ 947 Delay_Accy 1;
BA_ "U_U55X_MY2022_Tx" SG_ 947 Delay_Accy 1;
BA_ "U_CD764_MY2022_Tx" SG_ 947 Delay_Accy 1;
BA_ "WakeupSignal" SG_ 947 CrashEvnt_D_Stat 1;
BA_ "GenSigStartValueInteger" SG_ 947 CrashEvnt_D_Stat 3;
BA_ "GenSigStartValue" SG_ 947 CrashEvnt_D_Stat 3;
BA_ "GenSigSendType" SG_ 947 CrashEvnt_D_Stat 3;
BA_ "U_CX727_MY2021_Tx" SG_ 947 CrashEvnt_D_Stat 1;
BA_ "U_P702_MY2021_Tx" SG_ 947 CrashEvnt_D_Stat 1;
BA_ "U_T6_MCA_MY2020_Tx" SG_ 947 CrashEvnt_D_Stat 1;
BA_ "U_CD542_MY2021_Tx" SG_ 947 CrashEvnt_D_Stat 1;
BA_ "U_U55X_MY2022_Tx" SG_ 947 CrashEvnt_D_Stat 1;
BA_ "U_CD764_MY2022_Tx" SG_ 947 CrashEvnt_D_Stat 1;
BA_ "GenSigSendType" SG_ 947 FuelPmpInhbt_B_Stat 3;
BA_ "U_CX727_MY2021_Tx" SG_ 947 FuelPmpInhbt_B_Stat 1;
BA_ "U_P702_MY2021_Tx" SG_ 947 FuelPmpInhbt_B_Stat 1;
BA_ "U_T6_MCA_MY2020_Tx" SG_ 947 FuelPmpInhbt_B_Stat 1;
BA_ "U_CD542_MY2021_Tx" SG_ 947 FuelPmpInhbt_B_Stat 1;
BA_ "U_U55X_MY2022_Tx" SG_ 947 FuelPmpInhbt_B_Stat 1;
BA_ "U_CD764_MY2022_Tx" SG_ 947 FuelPmpInhbt_B_Stat 1;
BA_ "GenSigSendType" SG_ 947 BodySrvcRqd_B_Rq 3;
BA_ "U_CX727_MY2021_Tx" SG_ 947 BodySrvcRqd_B_Rq 1;
BA_ "U_P702_MY2021_Tx" SG_ 947 BodySrvcRqd_B_Rq 1;
BA_ "U_T6_MCA_MY2020_Tx" SG_ 947 BodySrvcRqd_B_Rq 1;
BA_ "U_CD542_MY2021_Tx" SG_ 947 BodySrvcRqd_B_Rq 1;
BA_ "U_U55X_MY2022_Tx" SG_ 947 BodySrvcRqd_B_Rq 1;
BA_ "U_CD764_MY2022_Tx" SG_ 947 BodySrvcRqd_B_Rq 1;
VAL_ 740 PtWakeupActv2_B_Rq 1 "On" 0 "Off" ;
VAL_ 740 BattAuxCnnct_B_Cmd 1 "Close" 0 "Open" ;
VAL_ 748 ChrgrOutHi_U_Actl 511 "Invalid" ;
VAL_ 748 ChrgrOutHi_I_Actl 4095 "Invalid" ;
VAL_ 748 ChrgrIn_Pw_Mx 4095 "Fault" ;
VAL_ 748 PlgActv_D_ActlChrgr 3 "Faulty" 2 "NoDataExists" 1 "On_Plug__Connected_" 0 "Off_Plug__Disconnected_" ;
VAL_ 748 ChrgrRdyStat_D_Actl 7 "NotUsed4" 6 "NotUsed3" 5 "NotUsed2" 4 "NotUsed1" 3 "Charging" 2 "ChargerFault" 1 "ChargerReady" 0 "NotReady" ;
VAL_ 389 HtrnOvrTeLamp_B_Dsply 1 "On" 0 "Off" ;
VAL_ 389 HtrnMil_D_Rq 3 "Not_Used" 2 "Flash" 1 "On" 0 "Off" ;
VAL_ 389 HtrnAin_UHi_Actl 1023 "Fault" 1022 "Unknown" ;
VAL_ 389 HtrnSrvcRqd_B_Dsply 1 "On" 0 "Off" ;
VAL_ 389 HtrnHvilOpen_B_Actl 1 "HVIL_is_Open" 0 "Normal_Operation" ;
VAL_ 389 PtWakeupDeltaT_T_Rq 2047 "Fault" 2046 "NoDataExists" ;
VAL_ 389 PreCondActv_B_Actl 1 "On" 0 "Off" ;
VAL_ 389 DrvCondTpRrDefrs_B_Rq 1 "On" 0 "Off" ;
VAL_ 389 BattTrac_I_EstVsc 32767 "Fault" 32766 "NoDataExists" ;
VAL_ 1055 EcoCochInstNeg_B_Dsply 1 "True" 0 "False" ;
VAL_ 374 GearEngag_D_Actl 7 "Undefined" 6 "Fwd_Clutch_Fully_Engaged" 5 "Neutral_Idle" 4 "Disengaged_to_Neutral_Idle" 3 "Disengaged_to_Neutral_Park" 2 "Engagement_in_Progress" 1 "InitializeFwdClutchEngagmt" 0 "Park_Neutral" ;
VAL_ 374 TrnRng_D_Rq 15 "Fault" 14 "Unknown_Position" 13 "NotUsed_2" 12 "NotUsed_1" 11 "Range6" 10 "Range5" 9 "Range4" 8 "Range3_M3_L3" 7 "Range2_M2_L2" 6 "Range1_M1_L1" 5 "Low" 4 "Sport_DriveSport_Mposition" 3 "Drive" 2 "Neutral" 1 "Reverse" 0 "Park" ;
VAL_ 374 TrnPrkSys_D_Actl 15 "Faulty" 14 "NotUsed_5" 13 "NotUsed_4" 12 "NotUsed_3" 11 "NotUsed_2" 10 "NotUsed_1" 9 "FrequencyError" 8 "OutOfRangeHigh" 7 "OutOfRangeLow" 6 "Override" 5 "OutOfPark" 4 "TransitionCloseToOutOfPark" 3 "AtNoSpring" 2 "TransitionCloseToPark" 1 "Park" 0 "NotKnown" ;
VAL_ 374 GearLvr_D_ActlDrv 15 "Fault" 14 "Unknown_Position" 13 "NotUsed_2" 12 "NotUsed_1" 11 "Range6" 10 "Range5" 9 "Range4" 8 "Range3_M3_L3" 7 "Range2_M2_L2" 6 "Range1_M1_L1" 5 "Low" 4 "Sport_DriveSport_Mposition" 3 "Drive" 2 "Neutral" 1 "Reverse" 0 "Park" ;
VAL_ 374 GearPos_D_Trg 15 "Unknown" 14 "Reverse" 13 "Undefined_5" 12 "Undefined_4" 11 "Undefined_3" 10 "Tenth" 9 "Ninth" 8 "Eighth" 7 "Seventh" 6 "Sixth" 5 "Fifth" 4 "Fourth" 3 "Third" 2 "Second" 1 "First" 0 "Neutral" ;
VAL_ 374 GearPos_D_Actl 15 "Unknown" 14 "Reverse" 13 "Undefined_5" 12 "Undefined_4" 11 "Undefined_3" 10 "Tenth" 9 "Ninth" 8 "Eighth" 7 "Seventh" 6 "Sixth" 5 "Fifth" 4 "Fourth" 3 "Third" 2 "Second" 1 "First" 0 "Neutral" ;
VAL_ 817 ChildLckMde_B_Stat 1 "Enable" 0 "Disable" ;
VAL_ 817 VehLckInd_D_Rq 3 "NotUsed" 2 "On_Day" 1 "On_Night" 0 "Off" ;
VAL_ 817 DrTgateOpen_B_Rq 1 "Open" 0 "Null" ;
VAL_ 817 DrTgateExtSwMde_B_Stat 1 "Enable" 0 "Disable" ;
VAL_ 817 Remote_Device_Feedback 7 "Unused3" 6 "Unused2" 5 "Unused1" 4 "Shutdown" 3 "Running" 2 "Starting" 1 "Acknowledge" 0 "Null" ;
VAL_ 817 Veh_Lock_Requestor 31 "Walk_Away_Locking" 30 "Remote_Park_Assist" 29 "DoorsOffToOn_Smart_Unlock" 28 "Rgtm_Shutlock_Switch" 27 "Boundary_Alert" 26 "Transit_Vehicle_Relock" 25 "Transit_Cargo_Relock" 24 "Transit_Ajar_Lock" 23 "Diagnostics" 22 "Console_Lock" 21 "Child_Lock" 20 "Double_Lock" 19 "Passive_Pasenger" 18 "Passive_Driver" 17 "Slam_Lock_Protect" 16 "SYNC" 15 "Passport" 14 "Passive_Smart_Unlock" 13 "Autorelock" 12 "RemoteStart" 0 "Null" 1 "Autolock" 11 "Smart_Unlock" 10 "Sliding_Door" 9 "Passive" 8 "Remote" 7 "Programming" 6 "Powerslide" 5 "Keypad" 4 "Key_Cylinder" 3 "Interior" 2 "Auto_Unlock" ;
VAL_ 817 R_Pwr_Sliding_Dr_Rqst 1 "Active" 0 "Null" ;
VAL_ 817 Power_Liftgate_Rqst 1 "Active" 0 "Null" ;
VAL_ 817 Power_Decklid_Rqst 1 "Active" 0 "Null" ;
VAL_ 817 L_Pwr_Sliding_Dr_Rqst 1 "Active" 0 "Null" ;
VAL_ 817 Veh_Lock_Sub_Id 15 "Unused7" 14 "Unused6" 13 "Unused5" 12 "Unused4" 11 "Unused3" 10 "Unused2" 9 "Unused1" 8 "Customer_8" 7 "Customer_7" 6 "Customer_6" 5 "Customer_5" 4 "Customer_4" 3 "Customer_3" 2 "Customer_2" 1 "Customer_1" 0 "Null" ;
VAL_ 817 Veh_Lock_Status 3 "UNLOCK_DRV" 2 "UNLOCK_ALL" 1 "LOCK_ALL" 0 "LOCK_DBL" ;
VAL_ 817 ChildLck_D_Dsply 3 "NOT_SUPPORTED" 2 "ERROR" 1 "CHILD_UNLOCK" 0 "CHILD_LOCK" ;
VAL_ 817 WindowLockout_B_Stat 1 "Locked" 0 "Unlock" ;
VAL_ 817 Lockmsgtxt_D_Rq 7 "MSG7" 6 "MSG6" 5 "MSG5" 4 "MSG4" 3 "MSG3" 2 "MSG2" 1 "MSG1" 0 "NO_WARNING" ;
VAL_ 817 FobComm_D_Stat 3 "NotUsed" 2 "RemEngStartOK" 1 "RemEngStartFail" 0 "Null" ;
VAL_ 817 LockInhibit 1 "Inhibit" 0 "No_Inhibit" ;
VAL_ 359 PrplWhlRgenMn_Tq_Actl 8191 "Faulty" ;
VAL_ 359 ElPw_D_StatStrtStop 15 "NotUsed6" 14 "NotUsed5" 13 "NotUsed4" 12 "NotUsed3" 11 "NotUsed2" 10 "NotUsed1" 9 "Supported_Level_4" 8 "Supported_Level_3" 7 "Supported_Level_2" 6 "Supported_Level_1" 5 "Limited_Support" 4 "Fault_Limited" 3 "LV_Event_in_Progress" 2 "Not_Supported_Imminent" 1 "Supported_All" 0 "Not_Supported" ;
VAL_ 359 PrplWhlTot2_Tq_Actl 65535 "Fault" 65534 "NoDataExists" ;
VAL_ 359 LscmbbDeny_B_ActlPrpl 1 "Denied" 0 "Allowed" ;
VAL_ 359 LscmbbEngTqMn_B_Actl 1 "Engine_Braking_Activated" 0 "Engine_Braking_Off" ;
VAL_ 359 PwPckTq_D_Stat 3 "PwPckOn_TqAvailable" 2 "StartInPrgrss_TqNotAvail" 1 "PwPckOn_TqNotAvailable" 0 "PwPckOff_TqNotAvailable" ;
VAL_ 359 Eng_D_Stat 3 "NotUsed" 2 "EngAutoStopped" 1 "EngOn" 0 "EngOff" ;
VAL_ 359 PlgActvArb_B_Actl 1 "On" 0 "Off" ;
VAL_ 359 ElPw_D_Stat 7 "NotUsed_3" 6 "NotUsed_2" 5 "NotUsed_1" 4 "Fault_Limited" 3 "LV_Event_In_Progress" 2 "Not_Supported_Imminent" 1 "Supported" 0 "Not_Supported" ;
VAL_ 359 TrnAinTq_D_Qf 3 "OK" 2 "Not_Within_Specifications" 1 "No_Data_Exists" 0 "Faulty" ;
VAL_ 1085 PwSrcULoOvrTe_B_Actl 1 "Yes" 0 "No" ;
VAL_ 1085 PwSrcULoOn_B_Actl 1 "Operating" 0 "Not_Operating" ;
VAL_ 1085 PwSrcULoFalt_D_Stat 3 "Fault_No_Output" 2 "Fault_Reduced_Output" 1 "Fault_NonSpecific" 0 "No_Fault" ;
VAL_ 1085 PwSrcULoDcnnt_B_Stat 1 "Loose_or_Disconnected" 0 "Connected" ;
VAL_ 1085 PwSrcULo_Pc_Mx 255 "Fault" ;
VAL_ 1085 DcdcULo_U_Actl 255 "Fault" ;
VAL_ 1085 DcdcUHi_I_Actl 255 "Fault" ;
VAL_ 1085 PwSrcULo_I_Mx 255 "Fault" ;
VAL_ 1085 PwSrcULo_I_Actl 255 "Fault" ;
VAL_ 1085 DcdcUHi_U_Actl 1023 "Fault" 1022 "NoDataExists" ;
VAL_ 603 FuelCtlOpenLp_B_Inhbt 1 " Inhibit_FullPedal_Actions" 0 "Normal_Operation" ;
VAL_ 603 EngDiag_D_RqHtrn 7 "NotUsed4" 6 "NotUsed3" 5 "NotUsed2" 4 "NoUsed1" 3 "Eng_Diag_Cstdn" 2 "Eng_Diag_Run" 1 "Eng_Diag_Crank" 0 "Eng_Diag_Normal" ;
VAL_ 603 WhlDirAvgDrv_D_Actl 3 "Faulty" 2 "NoDataExists" 1 "Backward" 0 "Forward" ;
VAL_ 603 PrplTqMnRgen_B_Actl 1 "Yes" 0 "No" ;
VAL_ 603 EDrvTqMntrRconfg_D_Cmd 7 "OK" 6 "Disable_Cruise" 5 "NotUsed4" 4 "Supercreep" 3 "NotUsed3" 2 "NotUsed2" 1 "Engine_shutdown" 0 "NotUsed" ;
VAL_ 603 BattTracCnnct_D_Rq 3 "Undefined" 2 "Retain" 1 "Close" 0 "Open" ;
VAL_ 602 HtrnWarnLamp_B_Dsply 1 "On" 0 "Off" ;
VAL_ 602 HybPwLimOn_B_Stat 1 "Yes" 0 "No" ;
VAL_ 602 PwSrcULoMde_D_Rq 3 "BuckSpecial" 2 "ReverseBoost" 1 "ForwardBuck" 0 "Standby" ;
VAL_ 602 PtcHtrRun_B_Rq 1 "On" 0 "Off" ;
VAL_ 602 PwPckTqRdy_B_Dsply 1 "On" 0 "Off" ;
VAL_ 602 ObdEngStdy_B_Stat 1 "Yes" 0 "No" ;
VAL_ 602 BattTracRsrvSoc_Pc_Rq 16383 "Faulty" 16382 "NoDataExists" ;
VAL_ 602 EngStrtSrvc_B_Allw 1 "Yes" 0 "No" ;
VAL_ 587 BattTracClnt_Te_Actl 255 "Faulty" 254 "NoDataExists" ;
VAL_ 587 BattTracWarnLamp_B_Rq 1 "On" 0 "Off" ;
VAL_ 587 BattTracSrvcRqd_B_Rq 1 "On" 0 "Off" ;
VAL_ 1040 ElCmpr2Enbl_B_Rq 1 "Enable" 0 "Disable" ;
VAL_ 1040 BattTrac_I2_EstVsc 262143 "Faulty" 262142 "NoDataExists" ;
VAL_ 1040 ElCmprEnbl_B_Rq 1 "Enable" 0 "Disable" ;
VAL_ 1088 TrlrRng_L_Dsply 8191 "Faulty" 8190 "NoDataExists" ;
VAL_ 1088 HvacPrecondRecirc_D_Rq 3 "Last_User_Setting" 2 "Auto" 1 "Recirc" 0 "Outside" ;
VAL_ 1088 HvacPrecondMode2_D_Rq 15 "NotUsed4" 14 "NotUsed3" 13 "NotUsed2" 12 "NotUsed1" 11 "Last_User_Settings" 10 "Auto" 9 "Max_Defrost" 8 "Windshield_Panel_Floor" 7 "Windshield_Panel" 6 "Windshield" 5 "Windshield_Floor" 4 "Floor" 3 "Panel_Floor" 2 "Panel" 1 "MAX_AC" 0 "Off" ;
VAL_ 1088 HvacPrecondBlwr2_D_Rq 15 "NotUsed6" 14 "NotUsed5" 13 "NotUsed4" 12 "NotUsed3" 11 "NotUsed2" 10 "NotUsed1" 9 "Last_User_Setting" 8 "Auto" 7 "Speed7" 6 "Speed6" 5 "Speed5" 4 "Speed4" 3 "Speed3" 2 "Speed2" 1 "Speed1" 0 "Off" ;
VAL_ 1088 HvacPrecondAC_D_Rq 3 "Last_User_Setting" 2 "Auto" 1 "On" 0 "Off" ;
VAL_ 1088 BattDcChrgRms_I_Lim 32767 "Faulty" 32766 "NoDataExists" ;
VAL_ 1088 BattChrgInhbt_D_Rq 3 "MaintainTargetSoc" 2 "NotUsed" 1 "InhibitChargingThermal" 0 "Enable_Charging" ;
VAL_ 1088 ChrgStat_D2_Dsply 15 "ChargeStopCommanded" 14 "ChargeStartCommanded" 13 "ChargeTargetReached" 12 "DriveConditioning" 11 "CabinPreconditioning" 10 "ChargingSystemMaintain" 9 "ChargingInductive" 8 "ChargingDCFastCharge" 7 "ChargingAC" 6 "ChargeScheduled" 5 "EvsePaused" 4 "EvseNotDetected" 3 "EvseNotCompatible" 2 "FaultOutsideCar" 1 "FaultInsideCar" 0 "NotReady" ;
VAL_ 1088 ChrgTMatch_B_Stat 1 "True" 0 "False" ;
VAL_ 1072 ePRNDL_MODE_UB 1 "Fresh_data" 0 "Unchanged_data" ;
VAL_ 1072 NtrlTowMdeEnbl_B_RqDrv 1 "Yes" 0 "No" ;
VAL_ 1072 NtrlTowMdeEnbl_B_RqDrv_UB 1 "Fresh_data" 0 "Unchanged_data" ;
VAL_ 1072 Remote_Start_QuietMode_UB 1 "Fresh_data" 0 "Unchanged_data" ;
VAL_ 1072 Remote_Start_QuietMode 1 "Quiet" 0 "Not_Quiet" ;
VAL_ 1072 ParkDetect_Stat_UB 1 "Fresh_data" 0 "Unchanged_data" ;
VAL_ 1072 ParkDetect_Stat 1 "Park" 0 "Not_Park" ;
VAL_ 1072 TrlrLampCnnct_B_Actl_UB 1 "Fresh_data" 0 "Unchanged_data" ;
VAL_ 1072 StopLamp_B_RqTrlrBrk_UB 1 "Fresh_data" 0 "Unchanged_data" ;
VAL_ 1072 StopLamp_B_RqTrlrBrk 1 "Yes" 0 "No" ;
VAL_ 1072 OdometerMasterValue_UB 1 "Fresh_data" 0 "Unchanged_data" ;
VAL_ 1072 OdometerMasterValue 16777215 "Invalid" ;
VAL_ 1072 FrostWarn_D_Stat 3 "NotUsed" 2 "On_Amber" 1 "On_Red" 0 "Off" ;
VAL_ 1072 ReducedGuard_D_Rq_UB 1 "Fresh_data" 0 "Unchanged_data" ;
VAL_ 1072 ReducedGuard_D_Rq 3 "NotUsed" 2 "On" 1 "Off" 0 "Null" ;
VAL_ 1072 ePRNDL_MODE 1 "On" 0 "Off" ;
VAL_ 1072 EngOilLife_B_RqReset 1 "Yes" 0 "No" ;
VAL_ 1072 Outside_Air_Temp_Stat_UB 1 "Fresh_data" 0 "Unchanged_data" ;
VAL_ 1072 Outside_Air_Temp_Stat 255 "Invalid" 254 "Unknown" ;
VAL_ 1072 KeyTypeChngMykey_D_Rq_UB 1 "Fresh_data" 0 "Unchanged_data" ;
VAL_ 1072 KeyTypeChngMykey_D_Rq 3 "Search_PE_BackupSlot" 2 "Clear_All_MyKeys" 1 "Request_New_MyKey" 0 "None" ;
VAL_ 1072 TrlrLampCnnct_B_Actl 1 "Yes" 0 "No" ;
VAL_ 588 BattTracSoc_Pc_Dsply 255 "Faulty" 254 "NoDataExists" ;
VAL_ 588 BattChrgRdyStat_D_Actl 7 "NotUsed2" 6 "NotUsed1" 5 "Faulted" 4 "ChargeComplete" 3 "Charging" 2 "BatteryChargeReady" 1 "ChargeWait" 0 "NotReady" ;
VAL_ 588 BattTracSoc2_Pc_Actl 16383 "Faulty" 16382 "NoDataExists" ;
VAL_ 588 BattTrac_Te_Actl 1023 "Fault" 1022 "Unknown" ;
VAL_ 122 VehStrtInhbt_B_RqBatt 1 "Yes" 0 "No" ;
VAL_ 122 BattTracOffFst_D_Actl 3 "Unexpected_Contactor_Open" 2 "Restraints_Impact_Event" 1 "Interlock_Open" 0 "Normal" ;
VAL_ 122 BattTracOff_B_Actl 1 "Yes" 0 "No" ;
VAL_ 122 BattTracMil_D_Rq 3 "Not_Used" 2 "Flash" 1 "On" 0 "Off" ;
VAL_ 122 BattTrac_U_Actl 1023 "Fault" 1022 "Unknown" ;
VAL_ 122 BattTrac_I_Actl 32767 "Fault" 32766 "Unknown" ;
VAL_ 578 PtLatchActv_B_RqBcm 1 "On" 0 "Off" ;
VAL_ 578 immoSecureIdleMode 3 "NotUsed2" 2 "NotUsed1" 1 "Active" 0 "Inactive" ;
VAL_ 578 ReFuelSwtchStat_D_Actl 3 "NotUsed2" 2 "NotUsed1" 1 "On" 0 "Off" ;
VAL_ 578 FuelPumpPwr_D_Stat 7 "NotUsed3" 6 "NotUsed2" 5 "NotUsed1" 4 "Power_Off_Default" 3 "Power_Off_Command" 2 "Power_Off_Service" 1 "Power_Off_Impact" 0 "Power_On" ;
VAL_ 578 BattULo_U_Actl 255 "Fault" ;
VAL_ 578 PrkLckCtl_B_Enbl 1 "Enable" 0 "Disable" ;
VAL_ 578 PrkLckCtlMsgTxt_D_Rq 3 "BTSI_DI_3" 2 "BTSI_DI_2" 1 "BTSI_DI_1" 0 "Null_BTSI_DI" ;
VAL_ 578 BrkTrnShifLck_B_Stat 1 "Shift" 0 "NoShift" ;
VAL_ 578 PrkLckCtlUnlck_D_Stat 3 "Trans_And_Steer_Unlckd" 2 "Steering_Unlckd" 1 "Transmission_Unlckd" 0 "Null" ;
VAL_ 578 PrkLckCtlTow_B_Enbl 1 "Enable" 0 "Disable" ;
VAL_ 578 DriverCrankingReq 1 "Crank_Request" 0 "No_Crank_Request" ;
VAL_ 578 EngOff_T_Actl 65535 "Invalid" ;
VAL_ 578 DcacElPw_D_Rq 3 "NotUsed" 2 "AC_HighPower_Requested" 1 "AC_LowPower_Requested" 0 "AC_Power_NotRequested" ;
VAL_ 578 BattULo_I_Actl 16383 "Fault" ;
VAL_ 514 StrtrMtrCtlMsgTxt_D2_Rq 3 "NoRequestPcmStartingMsgCtl" 2 "ShiftToNeutralToStart" 1 "ShiftToParkToStart" 0 "NoRequestBcmStartingMsgCtl" ;
VAL_ 514 StrtrMtrDlyStrt_B_Stat 1 "Yes" 0 "No" ;
VAL_ 514 VehVTrlrAid_B_Avail 1 "Yes" 0 "No" ;
VAL_ 514 StrtrMtrCtlMsgTxt_D_Rq 7 "Start_In_Gear_Allowed" 6 "Pending_Start_Cancelled" 5 "Start_Pending_Please_Wait" 4 "Cranking_Limit_Exceeded" 3 "Press_Brk_and_Shift_to_P_N" 2 "Press_Clutch_and_Brake" 1 "Press_Clutch_To_Start" 0 "No_Display" ;
VAL_ 514 VehVActlEng_D_Qf 3 "OK" 2 "Not_Within_Specifications" 1 "No_Data_Exists" 0 "Faulty" ;
VAL_ 514 GearRvrse_D_Actl 7 "Fault" 6 "NotUsed_3" 5 "NotUsed_2" 4 "NotUsed_1" 3 "Active_confirmed" 2 "Active_not_confirmed" 1 "Inactive_confirmed" 0 "Inactive_not_confirmed" ;
VAL_ 1069 SlMde_D_Stat 3 "IsaNotConfigured" 2 "Manual_Mode" 1 "Auto_Mode" 0 "Null" ;
VAL_ 1069 SlMde_D_RqDsply 3 "NotUsed" 2 "ManualSpeed_LimiterSymbol" 1 "AutoSpeed_LimiterSymbol" 0 "NoSpeed_LimiterSymbol" ;
VAL_ 1069 IsaOffst_D_Stat 15 "Faulty" 14 "Null" 13 "Thirteen" 12 "Twelve" 11 "Eleven" 10 "Ten" 9 "Nine" 8 "Eight" 7 "Seven" 6 "Six" 5 "Five" 4 "Four" 3 "Three" 2 "Two" 1 "One" 0 "Zero" ;
VAL_ 1069 ReFuelSysStat_D_Dsply 7 "NotUsed3" 6 "NotUsed2" 5 "NotUsed1" 4 "Refuel_Err" 3 "Close_Fuel_Door" 2 "Refuel_Ready" 1 "Wait_To_Fuel" 0 "Null" ;
VAL_ 1069 ULoSrcOnPlg_B_Cmd 1 "Activate" 0 "Deactivate" ;
VAL_ 1069 EngOilMaint_B_Stat 1 "On" 0 "Off" ;
VAL_ 1069 GrllShtrPos_D_Cmd 15 "Fully_Open" 14 "Position14" 13 "Position13" 12 "Position12" 11 "Position11" 10 "Position10" 9 "Position9" 8 "Position8" 7 "Position7" 6 "Position6" 5 "Position5" 4 "Position4" 3 "Position3" 2 "Position2" 1 "Position1" 0 "Fully_Closed" ;
VAL_ 1069 GrllShtrPos_B_Falt 1 "Fault" 0 "No_Fault" ;
VAL_ 1069 ObdWarmUp_B_Complt 1 "Yes" 0 "No" ;
VAL_ 1069 EngMsgTxt_D_Rq 3 "Undefined_2" 2 "Undefined_1" 1 "Power_Reduced_to_LowerTemp" 0 "No_Message" ;
VAL_ 1069 EngAirIn_Te_Actl 1023 "Fault" 1022 "Unknown" ;
VAL_ 1069 TracKeyMdeEnbl_B_Stat 1 "On" 0 "Off" ;
VAL_ 516 EngAoutNActl_D_QF 3 "OK" 2 "Not_Within_Specifications" 1 "No_Data_Exists" 0 "Faulty" ;
VAL_ 516 EngAout3_N_Actl 65535 "Invalid" ;
VAL_ 516 ApedPos_PcRate_ActlArb 255 "Fault" 254 "Unknown" ;
VAL_ 516 ApedPosPcActl_D_Qf 3 "OK" 2 "Not_Within_Specifications" 1 "No_Data_Exists" 0 "Faulty" ;
VAL_ 76 RstrnPsngrOn_D_Stat 15 "Faulty" 14 "NotUsed_11" 13 "NotUsed_10" 12 "ConfiguredOff" 11 "NotUsed_9" 10 "On" 9 "NotUsed_8" 8 "NotUsed_7" 7 "NotUsed_6" 6 "NotUsed_5" 5 "Off" 4 "NotUsed_4" 3 "NotUsed_3" 2 "NotUsed_2" 1 "NotUsed_1" 0 "NoAction" ;
VAL_ 76 PsngrFmidDetct_D_Actl 3 "Unknown" 2 "Empty" 1 "Occupied" 0 "Fault" ;
VAL_ 76 FirstRowBuckleMid 3 "Unknown" 2 "Unbelted" 1 "Belted" 0 "Faulty" ;
VAL_ 76 ThirdRowBucklePsngr 3 "Unknown" 2 "Unbelted" 1 "Belted" 0 "Faulty" ;
VAL_ 76 ThirdRowBuckleMid 3 "Unknown" 2 "Unbelted" 1 "Belted" 0 "Faulty" ;
VAL_ 76 ThirdRowBuckleDriver 3 "Unknown" 2 "Unbelted" 1 "Belted" 0 "Faulty" ;
VAL_ 76 SecondRowBucklePsngr 3 "Unknown" 2 "Unbelted" 1 "Belted" 0 "Faulty" ;
VAL_ 76 SecondRowBuckleMid 3 "Unknown" 2 "Unbelted" 1 "Belted" 0 "Faulty" ;
VAL_ 76 SecondRowBuckleDriver 3 "Unknown" 2 "Unbelted" 1 "Belted" 0 "Faulty" ;
VAL_ 76 FirstRowBuckleDriver 3 "Unknown" 2 "Unbelted" 1 "Belted" 0 "Faulty" ;
VAL_ 76 RILReq 3 "Not_Used" 2 "Plant_Mode" 1 "On" 0 "Off" ;
VAL_ 76 FirstRowBucklePsngr 3 "Unknown" 2 "Unbelted" 1 "Belted" 0 "Faulty" ;
VAL_ 76 RstrnImpactEvntStatus 7 "Invalid" 6 "Not_Used_4" 5 "Threshold_2_Exceeded" 4 "Not_Used_3" 3 "Threshold_1_Exceeded" 2 "Not_Used_2" 1 "Not_Used_1" 0 "Normal" ;
VAL_ 76 PsngrFrntDetct_D_Actl 3 "Unknown" 2 "Empty" 0 "Faulty" 1 "Occupied" ;
VAL_ 76 EDRTriggerEvntSync 1 "Threshold_Exceeded" 0 "Normal" ;
VAL_ 76 PassRstrnInd_Req 3 "ABOnNotIllum_OffNotIllum" 2 "AirbagOnNot_Illum_OffIllum" 1 "AirbagOn_Illum_OffNotIllum" 0 "AirbagOn_Illum_Off_Illum" ;
VAL_ 862 EcoMde_D_RqDrv 3 "Faulty" 2 "On" 1 "Off" 0 "Null" ;
VAL_ 862 TwHlGrdAsst_B_RqTrn 1 "On" 0 "Off" ;
VAL_ 862 ApaSwtch_D_RqDrv 3 "NotUsed2" 2 "NotUsed1" 1 "Pressed" 0 "Not_Pressed" ;
VAL_ 862 HvacBlwrFront_D_Stat 31 "Not_Used" 20 "Full_On" 19 "95_Percent" 18 "90_Percent" 17 "85_Percent" 16 "80_Percent" 15 "75_Percent" 14 "70_Percent" 13 "65_Percent" 12 "60_Percent" 11 "55_Percent" 10 "50_Percent" 9 "45_Percent" 8 "40_Percent" 7 "35_Percent" 6 "30_Percent" 5 "25_Percent" 4 "20_Percent" 3 "15_Percent" 2 "10_Percent" 1 "5_Percent" 0 "Off" ;
VAL_ 862 HvacBlwrRear_D_Stat 31 "Not_Used" 20 "Full_On" 19 "95_Percent" 18 "90_Percent" 17 "85_Percent" 16 "80_Percent" 15 "75_Percent" 14 "70_Percent" 13 "65_Percent" 12 "60_Percent" 11 "55_Percent" 10 "50_Percent" 9 "45_Percent" 8 "40_Percent" 7 "35_Percent" 6 "30_Percent" 5 "25_Percent" 4 "20_Percent" 3 "15_Percent" 2 "10_Percent" 1 "5_Percent" 0 "Off" ;
VAL_ 862 CabnAmb_Te_Actl 255 "Fault" ;
VAL_ 862 ClimtThrmlLoad_No_Actl 255 "Fault" ;
VAL_ 862 CamraDefog_B_Actl 1 "On" 0 "Off" ;
VAL_ 862 AutoStpHvacDelta_I_Est 255 "Fault" ;
VAL_ 560 SelDrvMdeSwtch_D_Stat3 3 "Faulty" 2 "SwitchState2" 1 "SwitchState1" 0 "NotPressed" ;
VAL_ 560 TrnGbox_Rt_Actl 65535 "Fault" 65534 "Unknown" ;
VAL_ 560 TrnSrvcRqd_B_Rq 1 "On" 0 "Off" ;
VAL_ 560 TrnCnvtClu_D_Actl 3 "Transition_or_Micro_Slip" 2 "Lock_Up_Fixed" 1 "Lock_Up_Slip" 0 "No_Lock_Up" ;
VAL_ 560 TrnShifActv_B_Actl 1 "Active" 0 "Inactive" ;
VAL_ 560 RtmTerrMdeChng_D_Rdy 7 "Fault" 6 "Undefined_2" 5 "Undefined_1" 4 "ModeUnavailDrInputRqd" 3 "SpOpModes_NotSupported" 2 "ModeUnavailDynamicCond" 1 "Module_In_Initialization" 0 "Mode_Change_Available" ;
VAL_ 560 RtmTerrMde_D_Actl 7 "Fail_Safe_Default" 6 "Dynamic_Mode" 5 "Rock_Crawl_Mode" 4 "Mud_Ruts_Mode" 3 "Sand_Mode" 2 "Undefined" 1 "Low_Mu_Mode" 0 "Special_Operating_Mode_Off" ;
VAL_ 560 GearLvrPos_D_Actl 15 "Fault" 14 "Unknown_Position" 13 "Undefined_Treat_as__Fault" 12 "Undefined_Treat_as_Fault" 11 "sixth" 10 "fifth" 9 "fourth" 8 "third" 7 "second" 6 "first" 5 "Low" 4 "Sport_DriveSport" 3 "Drive" 2 "Neutral" 1 "Reverse" 0 "Park" ;
VAL_ 560 GboxOil_Te_Actl 255 "Faulty" 254 "NoDataExists" ;
VAL_ 947 ValetMode_D_Mem 1 "On" 0 "Off" ;
VAL_ 947 DrStatDrvErrCnt_B_Stat 1 "Yes" 0 "No" ;
VAL_ 947 TurnLghtRight_D_Rq 3 "Seq" 2 "On" 1 "Off" 0 "Null" ;
VAL_ 947 TurnLghtRightOn_B_Stat 1 "On" 0 "Off" ;
VAL_ 947 TurnLghtLeftOn_B_Stat 1 "On" 0 "Off" ;
VAL_ 947 FogLghtRearOn_B_Stat 1 "On" 0 "Off" ;
VAL_ 947 Backlit_LED_Status 15 "Unused3" 14 "Unused2" 13 "Unused1" 12 "Night_12" 11 "Night_11" 10 "Night_10" 9 "Night_9" 8 "Night_8" 7 "Night_7" 6 "Night_6" 5 "Night_5" 4 "Night_4" 3 "Night_3" 2 "Night_2" 1 "Night_1" 0 "Off" ;
VAL_ 947 TurnLghtLeft_D_Rq 3 "Seq" 2 "On" 1 "Off" 0 "Null" ;
VAL_ 947 FogLghtFrontOn_B_Stat 1 "On" 0 "Off" ;
VAL_ 947 IgnKeyType_D_Actl 15 "Invalid" 14 "Unknown" 3 "Key_Not_Prgrm_Read_Failure" 2 "Key_In_Ign_My_Key" 1 "Key_In_Ign_Standard_Key" 0 "Key_Read_In_Progress" ;
VAL_ 947 Parklamp_Status 3 "Invalid" 2 "Unknown" 1 "On" 0 "Off" ;
VAL_ 947 Litval 255 "Invalid" 254 "Unknown" 5 "Day" 4 "Twilight_4" 3 "Twilight_3" 2 "Twilight_2" 1 "Twilight_1" 0 "Night" ;
VAL_ 947 Key_In_Ignition_Stat 1 "In" 0 "Out" ;
VAL_ 947 Ignition_Status 0 "Unknown" 1 "Off" 15 "Invalid" 8 "Start" 4 "Run" 2 "Accessory" ;
VAL_ 947 Dimming_Lvl 255 "Invalid" 254 "Unknown" 18 "Day_6" 17 "Day_5" 16 "Day_4" 15 "Day_3" 14 "Day_2" 13 "Day_1" 12 "Night_12" 11 "Night_11" 10 "Night_10" 9 "Night_9" 8 "Night_8" 7 "Night_7" 6 "Night_6" 5 "Night_5" 4 "Night_4" 3 "Night_3" 2 "Night_2" 1 "Night_1" 0 "Off" ;
VAL_ 947 Day_Night_Status 3 "NotUsed" 2 "Night" 1 "Day" 0 "Null" ;
VAL_ 947 Remote_Start_Status 3 "Invalid" 2 "Unknown" 1 "Remote" 0 "Null" ;
VAL_ 947 DrStatTgate_B_Actl 1 "Ajar" 0 "Closed" ;
VAL_ 947 DrStatRr_B_Actl 1 "Ajar" 0 "Closed" ;
VAL_ 947 DrStatRl_B_Actl 1 "Ajar" 0 "Closed" ;
VAL_ 947 DrStatPsngr_B_Actl 1 "Ajar" 0 "Closed" ;
VAL_ 947 DrStatInnrTgate_B_Actl 1 "Ajar" 0 "Closed" ;
VAL_ 947 DrStatHood_B_Actl 1 "Ajar" 0 "Closed" ;
VAL_ 947 DrStatDrv_B_Actl 1 "Ajar" 0 "Closed" ;
VAL_ 947 PrkBrkActv_B_Actl 1 "Active" 0 "Inactive" ;
VAL_ 947 LifeCycMde_D_Actl 3 "Transport" 2 "NotUsed" 1 "Factory" 0 "Normal" ;
VAL_ 947 Delay_Accy 1 "On" 0 "Off" ;
VAL_ 947 CrashEvnt_D_Stat 3 "Invalid" 2 "Fuel_Cutoff_Event" 1 "Deploy_Event" 0 "No_Event" ;
VAL_ 947 FuelPmpInhbt_B_Stat 1 "Inhibit" 0 "No_Inibit" ;
VAL_ 947 BodySrvcRqd_B_Rq 1 "Yes" 0 "No" ;
